VERSION "HNNBNNNYNNNNNNNNNNNNNNNNNNNNNNNNNNNNNNNNNN/4/%%%/4/'%**4NNN///"

NS_ :

BS_:

BU_: BAP_Tester CGS Gateway Gateway_PAG HUD Kombi Kombi_LB Kombi_PAG Waehlhebel_SB

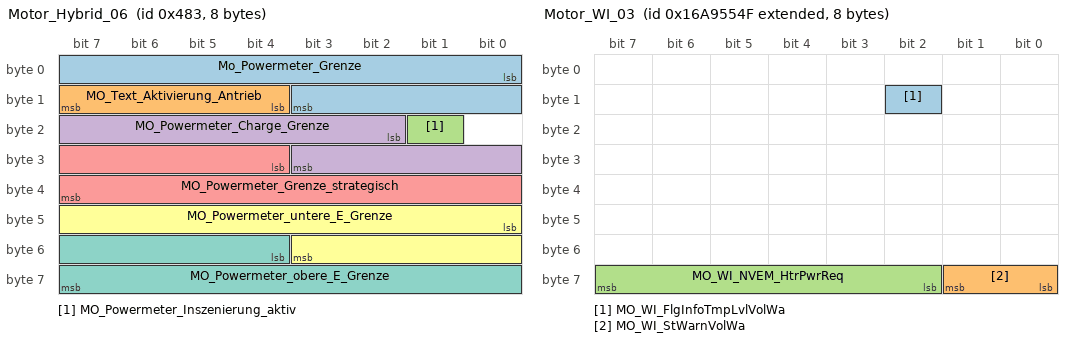
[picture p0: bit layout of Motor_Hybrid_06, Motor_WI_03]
BO_ 1155 Motor_Hybrid_06: 8 Gateway
 SG_ Mo_Powermeter_Grenze : 0|12@1+ (1,0) [0|4092] ""  HUD,Kombi,Kombi_LB,Kombi_PAG
 SG_ MO_Text_Aktivierung_Antrieb : 12|4@1+ (1.0,0.0) [0.0|15] ""  Kombi,Kombi_LB
 SG_ MO_Powermeter_Inszenierung_aktiv : 17|1@1+ (1.0,0.0) [0.0|1] ""  Kombi,Kombi_LB
 SG_ MO_Powermeter_Charge_Grenze : 18|10@1+ (1,0) [0|1021] "Unit_None"  HUD,Kombi,Kombi_LB,Kombi_PAG
 SG_ MO_Powermeter_Grenze_strategisch : 28|12@1+ (1,0) [0|4093] "Unit_None"  HUD,Kombi,Kombi_LB,Kombi_PAG
 SG_ MO_Powermeter_untere_E_Grenze : 40|12@1+ (1,0) [0|4093] "Unit_None"  Kombi,Kombi_LB,Kombi_PAG
 SG_ MO_Powermeter_obere_E_Grenze : 52|12@1+ (1,0) [0|4093] "Unit_None"  Kombi,Kombi_LB,Kombi_PAG

BO_ 878 Motor_Hybrid_12: 8 Gateway
 SG_ RML_Status_Anzeige_Range : 51|3@1+ (1.0,0.0) [0.0|7] ""  HUD,Kombi,Kombi_LB,Kombi_PAG
 SG_ RML_vMax_Range : 54|10@1+ (0.32,0) [0.00|326.72] "Unit_KiloMeterPerHour"  HUD,Kombi,Kombi_LB,Kombi_PAG

BO_ 2527679823 Motor_WI_03: 8 Gateway_PAG
 SG_ MO_WI_FlgInfoTmpLvlVolWa : 10|1@1+ (1.0,0.0) [0.0|1] ""  Kombi_PAG
 SG_ MO_WI_StWarnVolWa : 56|2@1+ (1.0,0.0) [0.0|3] ""  Kombi,Kombi_PAG
 SG_ MO_WI_NVEM_HtrPwrReq : 58|6@1+ (50,0) [0|3150] "Unit_Watt"  Vector__XXX

BO_ 2589284146 MRR_HL_P_Text_01: 8 Gateway
 SG_ MRR_HL_P_Text_Mux M  : 0|2@1+ (1,0) [0|3] ""  Kombi,Kombi_LB
 SG_ MRR_HL_P_Text_ASCII_01 m0  : 8|8@1+ (1.0,0.0) [0.0|255] ""  Kombi,Kombi_LB
 SG_ MRR_HL_P_Text_ASCII_08 m1  : 8|8@1+ (1.0,0.0) [0.0|255] ""  Kombi,Kombi_LB
 SG_ MRR_HL_P_Text_ASCII_15 m2  : 8|8@1+ (1.0,0.0) [0.0|255] ""  Kombi,Kombi_LB
 SG_ MRR_HL_P_Text_ASCII_02 m0  : 16|8@1+ (1.0,0.0) [0.0|255] ""  Kombi,Kombi_LB
 SG_ MRR_HL_P_Text_ASCII_09 m1  : 16|8@1+ (1.0,0.0) [0.0|255] ""  Kombi,Kombi_LB
 SG_ MRR_HL_P_Text_ASCII_16 m2  : 16|8@1+ (1.0,0.0) [0.0|255] ""  Kombi,Kombi_LB
 SG_ MRR_HL_P_Text_ASCII_03 m0  : 24|8@1+ (1.0,0.0) [0.0|255] ""  Kombi,Kombi_LB
 SG_ MRR_HL_P_Text_ASCII_10 m1  : 24|8@1+ (1.0,0.0) [0.0|255] ""  Kombi,Kombi_LB
 SG_ MRR_HL_P_Text_ASCII_17 m2  : 24|8@1+ (1.0,0.0) [0.0|255] ""  Kombi,Kombi_LB
 SG_ MRR_HL_P_Text_ASCII_04 m0  : 32|8@1+ (1.0,0.0) [0.0|255] ""  Kombi,Kombi_LB
 SG_ MRR_HL_P_Text_ASCII_11 m1  : 32|8@1+ (1.0,0.0) [0.0|255] ""  Kombi,Kombi_LB
 SG_ MRR_HL_P_Text_ASCII_18 m2  : 32|8@1+ (1.0,0.0) [0.0|255] ""  Kombi,Kombi_LB
 SG_ MRR_HL_P_Text_ASCII_05 m0  : 40|8@1+ (1.0,0.0) [0.0|255] ""  Kombi,Kombi_LB
 SG_ MRR_HL_P_Text_ASCII_12 m1  : 40|8@1+ (1.0,0.0) [0.0|255] ""  Kombi,Kombi_LB
 SG_ MRR_HL_P_Text_ASCII_19 m2  : 40|8@1+ (1.0,0.0) [0.0|255] ""  Kombi,Kombi_LB
 SG_ MRR_HL_P_Text_ASCII_06 m0  : 48|8@1+ (1.0,0.0) [0.0|255] ""  Kombi,Kombi_LB
 SG_ MRR_HL_P_Text_ASCII_13 m1  : 48|8@1+ (1.0,0.0) [0.0|255] ""  Kombi,Kombi_LB
 SG_ MRR_HL_P_Text_ASCII_20 m2  : 48|8@1+ (1.0,0.0) [0.0|255] ""  Kombi,Kombi_LB
 SG_ MRR_HL_P_Text_ASCII_07 m0  : 56|8@1+ (1.0,0.0) [0.0|255] ""  Kombi,Kombi_LB
 SG_ MRR_HL_P_Text_ASCII_14 m1  : 56|8@1+ (1.0,0.0) [0.0|255] ""  Kombi,Kombi_LB
 SG_ MRR_HL_P_Text_ASCII_21 m2  : 56|8@1+ (1.0,0.0) [0.0|255] ""  Kombi,Kombi_LB

BO_ 2589284147 MRR_HR_P_Text_01: 8 Gateway
 SG_ MRR_HR_P_Text_Mux M  : 0|2@1+ (1,0) [0|3] ""  Kombi,Kombi_LB
 SG_ MRR_HR_P_Text_ASCII_01 m0  : 8|8@1+ (1.0,0.0) [0.0|255] ""  Kombi,Kombi_LB
 SG_ MRR_HR_P_Text_ASCII_08 m1  : 8|8@1+ (1.0,0.0) [0.0|255] ""  Kombi,Kombi_LB
 SG_ MRR_HR_P_Text_ASCII_15 m2  : 8|8@1+ (1.0,0.0) [0.0|255] ""  Kombi,Kombi_LB
 SG_ MRR_HR_P_Text_ASCII_02 m0  : 16|8@1+ (1.0,0.0) [0.0|255] ""  Kombi,Kombi_LB
 SG_ MRR_HR_P_Text_ASCII_09 m1  : 16|8@1+ (1.0,0.0) [0.0|255] ""  Kombi,Kombi_LB
 SG_ MRR_HR_P_Text_ASCII_16 m2  : 16|8@1+ (1.0,0.0) [0.0|255] ""  Kombi,Kombi_LB
 SG_ MRR_HR_P_Text_ASCII_03 m0  : 24|8@1+ (1.0,0.0) [0.0|255] ""  Kombi,Kombi_LB
 SG_ MRR_HR_P_Text_ASCII_10 m1  : 24|8@1+ (1.0,0.0) [0.0|255] ""  Kombi,Kombi_LB
 SG_ MRR_HR_P_Text_ASCII_17 m2  : 24|8@1+ (1.0,0.0) [0.0|255] ""  Kombi,Kombi_LB
 SG_ MRR_HR_P_Text_ASCII_04 m0  : 32|8@1+ (1.0,0.0) [0.0|255] ""  Kombi,Kombi_LB
 SG_ MRR_HR_P_Text_ASCII_11 m1  : 32|8@1+ (1.0,0.0) [0.0|255] ""  Kombi,Kombi_LB
 SG_ MRR_HR_P_Text_ASCII_18 m2  : 32|8@1+ (1.0,0.0) [0.0|255] ""  Kombi,Kombi_LB
 SG_ MRR_HR_P_Text_ASCII_05 m0  : 40|8@1+ (1.0,0.0) [0.0|255] ""  Kombi,Kombi_LB
 SG_ MRR_HR_P_Text_ASCII_12 m1  : 40|8@1+ (1.0,0.0) [0.0|255] ""  Kombi,Kombi_LB
 SG_ MRR_HR_P_Text_ASCII_19 m2  : 40|8@1+ (1.0,0.0) [0.0|255] ""  Kombi,Kombi_LB
 SG_ MRR_HR_P_Text_ASCII_06 m0  : 48|8@1+ (1.0,0.0) [0.0|255] ""  Kombi,Kombi_LB
 SG_ MRR_HR_P_Text_ASCII_13 m1  : 48|8@1+ (1.0,0.0) [0.0|255] ""  Kombi,Kombi_LB
 SG_ MRR_HR_P_Text_ASCII_20 m2  : 48|8@1+ (1.0,0.0) [0.0|255] ""  Kombi,Kombi_LB
 SG_ MRR_HR_P_Text_ASCII_07 m0  : 56|8@1+ (1.0,0.0) [0.0|255] ""  Kombi,Kombi_LB
 SG_ MRR_HR_P_Text_ASCII_14 m1  : 56|8@1+ (1.0,0.0) [0.0|255] ""  Kombi,Kombi_LB
 SG_ MRR_HR_P_Text_ASCII_21 m2  : 56|8@1+ (1.0,0.0) [0.0|255] ""  Kombi,Kombi_LB

BO_ 2589284144 MRR_VL_P_Text_01: 8 Gateway
 SG_ MRR_VL_P_Text_Mux M  : 0|2@1+ (1,0) [0|3] ""  Kombi,Kombi_LB
 SG_ MRR_VL_P_Text_ASCII_01 m0  : 8|8@1+ (1.0,0.0) [0.0|255] ""  Kombi,Kombi_LB
 SG_ MRR_VL_P_Text_ASCII_08 m1  : 8|8@1+ (1.0,0.0) [0.0|255] ""  Kombi,Kombi_LB
 SG_ MRR_VL_P_Text_ASCII_15 m2  : 8|8@1+ (1.0,0.0) [0.0|255] ""  Kombi,Kombi_LB
 SG_ MRR_VL_P_Text_ASCII_02 m0  : 16|8@1+ (1.0,0.0) [0.0|255] ""  Kombi,Kombi_LB
 SG_ MRR_VL_P_Text_ASCII_09 m1  : 16|8@1+ (1.0,0.0) [0.0|255] ""  Kombi,Kombi_LB
 SG_ MRR_VL_P_Text_ASCII_16 m2  : 16|8@1+ (1.0,0.0) [0.0|255] ""  Kombi,Kombi_LB
 SG_ MRR_VL_P_Text_ASCII_03 m0  : 24|8@1+ (1.0,0.0) [0.0|255] ""  Kombi,Kombi_LB
 SG_ MRR_VL_P_Text_ASCII_10 m1  : 24|8@1+ (1.0,0.0) [0.0|255] ""  Kombi,Kombi_LB
 SG_ MRR_VL_P_Text_ASCII_17 m2  : 24|8@1+ (1.0,0.0) [0.0|255] ""  Kombi,Kombi_LB
 SG_ MRR_VL_P_Text_ASCII_04 m0  : 32|8@1+ (1.0,0.0) [0.0|255] ""  Kombi,Kombi_LB
 SG_ MRR_VL_P_Text_ASCII_11 m1  : 32|8@1+ (1.0,0.0) [0.0|255] ""  Kombi,Kombi_LB
 SG_ MRR_VL_P_Text_ASCII_18 m2  : 32|8@1+ (1.0,0.0) [0.0|255] ""  Kombi,Kombi_LB
 SG_ MRR_VL_P_Text_ASCII_05 m0  : 40|8@1+ (1.0,0.0) [0.0|255] ""  Kombi,Kombi_LB
 SG_ MRR_VL_P_Text_ASCII_12 m1  : 40|8@1+ (1.0,0.0) [0.0|255] ""  Kombi,Kombi_LB
 SG_ MRR_VL_P_Text_ASCII_19 m2  : 40|8@1+ (1.0,0.0) [0.0|255] ""  Kombi,Kombi_LB
 SG_ MRR_VL_P_Text_ASCII_06 m0  : 48|8@1+ (1.0,0.0) [0.0|255] ""  Kombi,Kombi_LB
 SG_ MRR_VL_P_Text_ASCII_13 m1  : 48|8@1+ (1.0,0.0) [0.0|255] ""  Kombi,Kombi_LB
 SG_ MRR_VL_P_Text_ASCII_20 m2  : 48|8@1+ (1.0,0.0) [0.0|255] ""  Kombi,Kombi_LB
 SG_ MRR_VL_P_Text_ASCII_07 m0  : 56|8@1+ (1.0,0.0) [0.0|255] ""  Kombi,Kombi_LB
 SG_ MRR_VL_P_Text_ASCII_14 m1  : 56|8@1+ (1.0,0.0) [0.0|255] ""  Kombi,Kombi_LB
 SG_ MRR_VL_P_Text_ASCII_21 m2  : 56|8@1+ (1.0,0.0) [0.0|255] ""  Kombi,Kombi_LB

BO_ 2589284145 MRR_VR_P_Text_01: 8 Gateway
 SG_ MRR_VR_P_Text_Mux M  : 0|2@1+ (1,0) [0|3] ""  Kombi,Kombi_LB
 SG_ MRR_VR_P_Text_ASCII_01 m0  : 8|8@1+ (1.0,0.0) [0.0|255] ""  Kombi,Kombi_LB
 SG_ MRR_VR_P_Text_ASCII_08 m1  : 8|8@1+ (1.0,0.0) [0.0|255] ""  Kombi,Kombi_LB
 SG_ MRR_VR_P_Text_ASCII_15 m2  : 8|8@1+ (1.0,0.0) [0.0|255] ""  Kombi,Kombi_LB
 SG_ MRR_VR_P_Text_ASCII_02 m0  : 16|8@1+ (1.0,0.0) [0.0|255] ""  Kombi,Kombi_LB
 SG_ MRR_VR_P_Text_ASCII_09 m1  : 16|8@1+ (1.0,0.0) [0.0|255] ""  Kombi,Kombi_LB
 SG_ MRR_VR_P_Text_ASCII_16 m2  : 16|8@1+ (1.0,0.0) [0.0|255] ""  Kombi,Kombi_LB
 SG_ MRR_VR_P_Text_ASCII_03 m0  : 24|8@1+ (1.0,0.0) [0.0|255] ""  Kombi,Kombi_LB
 SG_ MRR_VR_P_Text_ASCII_10 m1  : 24|8@1+ (1.0,0.0) [0.0|255] ""  Kombi,Kombi_LB
 SG_ MRR_VR_P_Text_ASCII_17 m2  : 24|8@1+ (1.0,0.0) [0.0|255] ""  Kombi,Kombi_LB
 SG_ MRR_VR_P_Text_ASCII_04 m0  : 32|8@1+ (1.0,0.0) [0.0|255] ""  Kombi,Kombi_LB
 SG_ MRR_VR_P_Text_ASCII_11 m1  : 32|8@1+ (1.0,0.0) [0.0|255] ""  Kombi,Kombi_LB
 SG_ MRR_VR_P_Text_ASCII_18 m2  : 32|8@1+ (1.0,0.0) [0.0|255] ""  Kombi,Kombi_LB
 SG_ MRR_VR_P_Text_ASCII_05 m0  : 40|8@1+ (1.0,0.0) [0.0|255] ""  Kombi,Kombi_LB
 SG_ MRR_VR_P_Text_ASCII_12 m1  : 40|8@1+ (1.0,0.0) [0.0|255] ""  Kombi,Kombi_LB
 SG_ MRR_VR_P_Text_ASCII_19 m2  : 40|8@1+ (1.0,0.0) [0.0|255] ""  Kombi
 SG_ MRR_VR_P_Text_ASCII_06 m0  : 48|8@1+ (1.0,0.0) [0.0|255] ""  Kombi,Kombi_LB
 SG_ MRR_VR_P_Text_ASCII_13 m1  : 48|8@1+ (1.0,0.0) [0.0|255] ""  Kombi,Kombi_LB
 SG_ MRR_VR_P_Text_ASCII_20 m2  : 48|8@1+ (1.0,0.0) [0.0|255] ""  Kombi
 SG_ MRR_VR_P_Text_ASCII_07 m0  : 56|8@1+ (1.0,0.0) [0.0|255] ""  Kombi,Kombi_LB
 SG_ MRR_VR_P_Text_ASCII_14 m1  : 56|8@1+ (1.0,0.0) [0.0|255] ""  Kombi,Kombi_LB
 SG_ MRR_VR_P_Text_ASCII_21 m2  : 56|8@1+ (1.0,0.0) [0.0|255] ""  Kombi

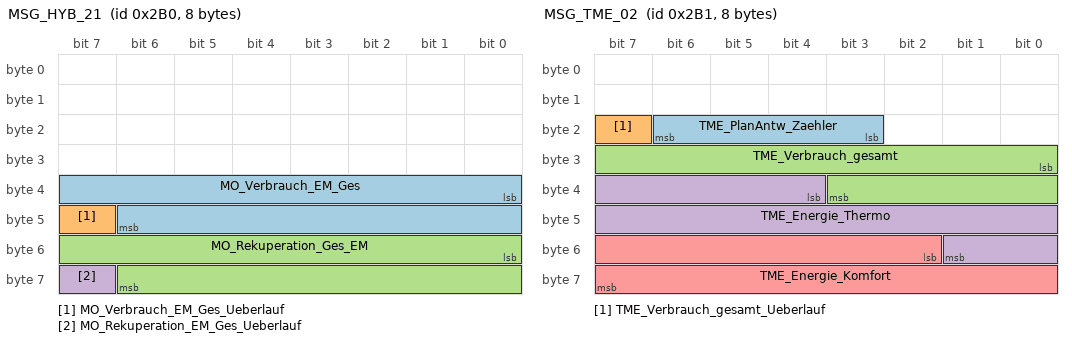
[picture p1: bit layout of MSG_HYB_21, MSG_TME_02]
BO_ 688 MSG_HYB_21: 8 Gateway
 SG_ MO_Verbrauch_EM_Ges : 32|15@1+ (10,0) [0|327670] "Unit_WattSecond"  Kombi,Kombi_LB,Kombi_PAG
 SG_ MO_Verbrauch_EM_Ges_Ueberlauf : 47|1@1+ (1.0,0.0) [0.0|1] ""  Kombi,Kombi_LB,Kombi_PAG
 SG_ MO_Rekuperation_Ges_EM : 48|15@1+ (10,0) [0|327670] "Unit_WattSecond"  Kombi,Kombi_LB,Kombi_PAG
 SG_ MO_Rekuperation_EM_Ges_Ueberlauf : 63|1@1+ (1.0,0.0) [0.0|1] ""  Kombi,Kombi_LB,Kombi_PAG

BO_ 689 MSG_TME_02: 8 Gateway
 SG_ TME_PlanAntw_Zaehler : 19|4@1+ (1,0) [0|13] "Unit_None"  Vector__XXX
 SG_ TME_Verbrauch_gesamt_Ueberlauf : 23|1@1+ (1.0,0.0) [0.0|1] ""  Kombi,Kombi_LB
 SG_ TME_Verbrauch_gesamt : 24|12@1+ (1,0) [0|4095] "Unit_WattSecond"  Kombi,Kombi_LB
 SG_ TME_Energie_Thermo : 36|14@1+ (5,0) [0|63250] "Unit_WattHour"  Vector__XXX
 SG_ TME_Energie_Komfort : 50|14@1+ (5,0) [0|63250] "Unit_WattHour"  Vector__XXX

BO_ 1284 MVK_01: 8 Gateway
 SG_ MVK_01_CRC : 0|8@1+ (1,0) [0|255] ""  Vector__XXX
 SG_ MVK_01_BZ : 8|4@1+ (1,0) [0|15] ""  Vector__XXX
 SG_ MVK_DCDC_Sollmodus_02 : 12|4@1+ (1.0,0.0) [0.0|15] ""  Vector__XXX
 SG_ MVK_eKAT_Sollmodus : 24|3@1+ (1.0,0.0) [0.0|7] ""  Vector__XXX
 SG_ MVK_eKMV_Sollmodus : 27|3@1+ (1.0,0.0) [0.0|7] ""  Vector__XXX
 SG_ MVK_MVH_L_Sollmodus : 30|3@1+ (1.0,0.0) [0.0|7] ""  Vector__XXX
 SG_ MV_Bordnetz_aktiv : 33|1@1+ (1.0,0.0) [0.0|1] ""  Vector__XXX
 SG_ MVK_BOOST_Sollmodus : 34|3@1+ (1.0,0.0) [0.0|7] ""  Vector__XXX
 SG_ MVK_eABC_Sollmodus : 37|3@1+ (1.0,0.0) [0.0|7] ""  Vector__XXX
 SG_ MVK_eAWS_Sollmodus : 40|3@1+ (1.0,0.0) [0.0|7] ""  Vector__XXX
 SG_ MV_Bordnetz_Fehler : 43|1@1+ (1.0,0.0) [0.0|1] ""  Vector__XXX
 SG_ MVK_MVPTC_Sollmodus : 44|3@1+ (1.0,0.0) [0.0|7] ""  Vector__XXX
 SG_ MVK_Istmodus_Anf : 47|1@1+ (1.0,0.0) [0.0|1] ""  Vector__XXX
 SG_ MVK_MO_EmSollzustand : 48|8@1+ (1.0,0.0) [0.0|255] ""  Vector__XXX
 SG_ MVK_BMS_Sollmodus : 56|3@1+ (1.0,0.0) [0.0|7] ""  Vector__XXX
 SG_ MVK_DCDC_Sollmodus : 59|3@1+ (1.0,0.0) [0.0|7] ""  Vector__XXX
 SG_ MVK_MV_Netz_Warnungen : 62|2@1+ (1.0,0.0) [0.0|3] ""  Kombi,Kombi_PAG

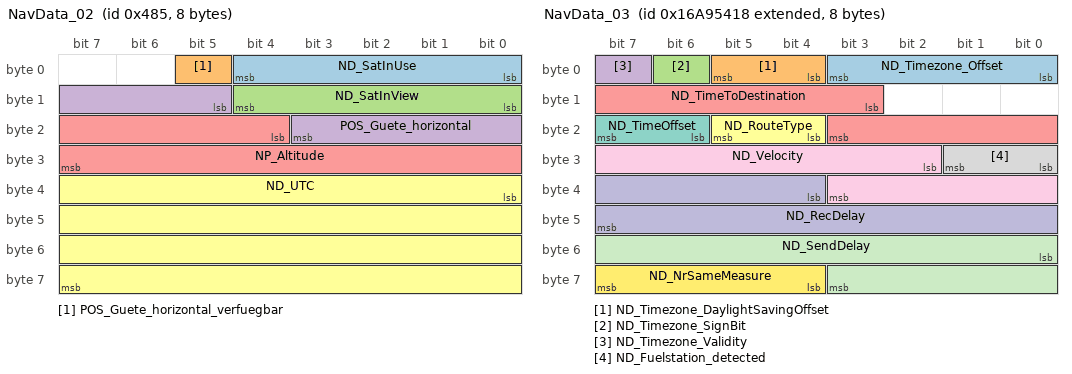
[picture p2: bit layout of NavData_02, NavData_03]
BO_ 1157 NavData_02: 8 Gateway
 SG_ ND_SatInUse : 0|5@1+ (1,0) [0|29] ""  Vector__XXX
 SG_ POS_Guete_horizontal_verfuegbar : 5|1@1+ (1.0,0.0) [0.0|1] ""  Vector__XXX
 SG_ ND_SatInView : 8|5@1+ (1,0) [0|29] ""  Vector__XXX
 SG_ POS_Guete_horizontal : 13|7@1+ (2,0) [0|246] "Unit_Meter"  Vector__XXX
 SG_ NP_Altitude : 20|12@1+ (2,-500) [-500|7686] "Unit_Meter"  Kombi_PAG
 SG_ ND_UTC : 32|32@1+ (1,0) [0|4294967293] "Unit_Secon"  Vector__XXX

BO_ 2527679512 NavData_03: 8 Gateway
 SG_ ND_Timezone_Offset : 0|4@1+ (1,0) [0|12] "Unit_Hours"  Vector__XXX
 SG_ ND_Timezone_DaylightSavingOffset : 4|2@1+ (30,0) [0|60] "Unit_Minut"  Vector__XXX
 SG_ ND_Timezone_SignBit : 6|1@1+ (1.0,0.0) [0.0|1] ""  Vector__XXX
 SG_ ND_Timezone_Validity : 7|1@1+ (1.0,0.0) [0.0|1] ""  Vector__XXX
 SG_ ND_TimeToDestination : 11|9@1+ (1,0) [0|509] "Unit_Minut"  Vector__XXX
 SG_ ND_RouteType : 20|2@1+ (1.0,0.0) [0.0|3] ""  Vector__XXX
 SG_ ND_TimeOffset : 22|2@1+ (1.0,0.0) [0.0|3] ""  Vector__XXX
 SG_ ND_Fuelstation_detected : 24|2@1+ (1.0,0.0) [0.0|3] ""  Kombi,Kombi_LB,Kombi_PAG
 SG_ ND_Velocity : 26|10@1+ (0.1,0) [0.0|102.1] "Unit_MeterPerSecon"  Vector__XXX
 SG_ ND_RecDelay : 36|12@1+ (1,0) [0|4093] "Unit_MilliSecon"  Vector__XXX
 SG_ ND_SendDelay : 48|12@1+ (1,0) [0|4093] "Unit_MilliSecon"  Vector__XXX
 SG_ ND_NrSameMeasure : 60|4@1+ (1,0) [0|8] ""  Vector__XXX

BO_ 1696 NightVision_01: 8 Gateway
 SG_ NV_aktiv : 12|1@1+ (1.0,0.0) [0.0|1] ""  Kombi,Kombi_PAG
 SG_ NV_Texte : 13|3@1+ (1.0,0.0) [0.0|7] ""  Kombi,Kombi_PAG
 SG_ NV_Gong : 16|2@1+ (1.0,0.0) [0.0|3] ""  Kombi,Kombi_PAG
 SG_ NV_Symbol : 18|1@1+ (1.0,0.0) [0.0|1] ""  HUD,Kombi,Kombi_PAG
 SG_ NV_Hinweise : 19|2@1+ (1.0,0.0) [0.0|3] ""  Kombi,Kombi_PAG
 SG_ NV_Piktogramm_aktiv : 21|1@1+ (1.0,0.0) [0.0|1] ""  Kombi,Kombi_PAG
 SG_ NV_Akustik_deaktiviert_Icon : 22|1@1+ (1.0,0.0) [0.0|1] ""  Kombi,Kombi_PAG
 SG_ NV_FGM_deaktiviert_Icon : 23|1@1+ (1.0,0.0) [0.0|1] ""  Kombi,Kombi_PAG
 SG_ NV_Markierungslicht_links : 24|1@1+ (1.0,0.0) [0.0|1] ""  Vector__XXX
 SG_ NV_Markierungslicht_rechts : 25|1@1+ (1.0,0.0) [0.0|1] ""  Vector__XXX
 SG_ NV_Symbol_Tierwarnung : 26|1@1+ (1.0,0.0) [0.0|1] ""  HUD,Kombi,Kombi_PAG
 SG_ NV_Anf_Prefill : 27|1@1+ (1.0,0.0) [0.0|1] ""  Vector__XXX
 SG_ NV_HBA_Parameter : 28|2@1+ (1.0,0.0) [0.0|3] ""  Vector__XXX
 SG_ NV_LED_Leiste : 30|2@1+ (1.0,0.0) [0.0|3] ""  HUD,Kombi,Kombi_PAG
 SG_ NV_PreSense_Status : 32|2@1+ (1.0,0.0) [0.0|3] ""  Vector__XXX
 SG_ NV_PreSense_Modus_System : 34|1@1+ (1.0,0.0) [0.0|1] ""  Vector__XXX
 SG_ NV_PreSense_Modus_Warnung : 35|3@1+ (1.0,0.0) [0.0|7] ""  Vector__XXX
 SG_ NV_FAS_Fkt_Status : 38|2@1+ (1.0,0.0) [0.0|3] ""  Vector__XXX
 SG_ NV_Akt_Status_MMI : 40|2@1+ (1.0,0.0) [0.0|3] ""  Kombi,Kombi_PAG
 SG_ NV_AnforderungBildaufschaltung : 42|1@1+ (1.0,0.0) [0.0|1] ""  Kombi

BO_ 2600468496 NMH_Gateway: 8 Gateway
 SG_ NM_Gateway_SNI : 0|8@1+ (1.0,0.0) [0.0|255] ""  CGS,HUD,Kombi,Kombi_LB,Kombi_PAG,Waehlhebel_SB
 SG_ NM_Gateway_CBV_AWB : 12|1@1+ (1.0,0.0) [0.0|1] ""  Vector__XXX
 SG_ NM_Gateway_CBV_CRI : 14|1@1+ (1.0,0.0) [0.0|1] ""  CGS,HUD,Kombi,Kombi_LB,Kombi_PAG,Waehlhebel_SB
 SG_ NM_Gateway_NM_State : 16|6@1+ (1.0,0.0) [0.0|63] ""  Vector__XXX
 SG_ NM_Gateway_Car_Wakeup : 22|1@1+ (1.0,0.0) [0.0|1] ""  Vector__XXX
 SG_ NM_Gateway_UDS_CC : 23|1@1+ (1.0,0.0) [0.0|1] ""  Vector__XXX
 SG_ NM_Gateway_NM_aktiv_KL15 : 24|1@1+ (1.0,0.0) [0.0|1] ""  Vector__XXX
 SG_ NM_Gateway_NM_aktiv_Diagnose : 25|1@1+ (1.0,0.0) [0.0|1] ""  Vector__XXX
 SG_ NM_Gateway_NM_aktiv_Tmin : 26|1@1+ (1.0,0.0) [0.0|1] ""  Vector__XXX
 SG_ NM_Gateway_NM_aktiv_CWU : 27|1@1+ (1.0,0.0) [0.0|1] ""  Vector__XXX
 SG_ NM_Gateway_NM_aktiv_FC : 28|1@1+ (1.0,0.0) [0.0|1] ""  Vector__XXX
 SG_ NM_Gateway_NM_aktiv_Connect : 29|1@1+ (1.0,0.0) [0.0|1] ""  Vector__XXX
 SG_ NM_Gateway_NM_aktiv_EM : 30|1@1+ (1.0,0.0) [0.0|1] ""  Vector__XXX
 SG_ NM_Gateway_NM_aktiv_OBDC : 31|1@1+ (1.0,0.0) [0.0|1] ""  Vector__XXX
 SG_ NM_Gateway_NM_aktiv_Buskopplung : 32|1@1+ (1.0,0.0) [0.0|1] ""  Vector__XXX
 SG_ NM_Gateway_NM_aktiv_LIN2 : 33|1@1+ (1.0,0.0) [0.0|1] ""  Vector__XXX
 SG_ NM_Gateway_NM_aktiv_Fremdladung : 34|1@1+ (1.0,0.0) [0.0|1] ""  Vector__XXX
 SG_ NM_Gateway_CAB : 40|24@1+ (1.0,0.0) [0.0|16777215] ""  CGS,HUD,Kombi,Kombi_LB,Kombi_PAG,Waehlhebel_SB

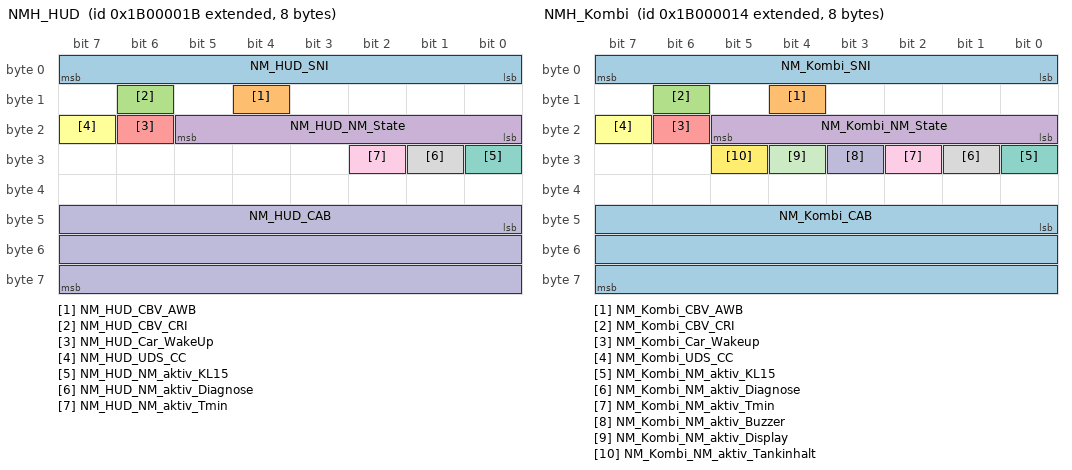
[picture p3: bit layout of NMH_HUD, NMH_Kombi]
BO_ 2600468507 NMH_HUD: 8 HUD
 SG_ NM_HUD_SNI : 0|8@1+ (1.0,0.0) [0.0|255] ""  CGS,Gateway,Gateway_PAG,HUD,Kombi,Kombi_LB,Kombi_PAG,Waehlhebel_SB
 SG_ NM_HUD_CBV_AWB : 12|1@1+ (1.0,0.0) [0.0|1] ""  Gateway,Gateway_PAG
 SG_ NM_HUD_CBV_CRI : 14|1@1+ (1.0,0.0) [0.0|1] ""  CGS,Gateway,Gateway_PAG,HUD,Kombi,Kombi_LB,Kombi_PAG,Waehlhebel_SB
 SG_ NM_HUD_NM_State : 16|6@1+ (1.0,0.0) [0.0|63] ""  Vector__XXX
 SG_ NM_HUD_Car_WakeUp : 22|1@1+ (1.0,0.0) [0.0|1] ""  Gateway
 SG_ NM_HUD_UDS_CC : 23|1@1+ (1.0,0.0) [0.0|1] ""  Vector__XXX
 SG_ NM_HUD_NM_aktiv_KL15 : 24|1@1+ (1.0,0.0) [0.0|1] ""  Vector__XXX
 SG_ NM_HUD_NM_aktiv_Diagnose : 25|1@1+ (1.0,0.0) [0.0|1] ""  Vector__XXX
 SG_ NM_HUD_NM_aktiv_Tmin : 26|1@1+ (1.0,0.0) [0.0|1] ""  Vector__XXX
 SG_ NM_HUD_CAB : 40|24@1+ (1.0,0.0) [0.0|16777215] ""  CGS,Gateway,Gateway_PAG,HUD,Kombi,Kombi_LB,Kombi_PAG,Waehlhebel_SB

BO_ 2600468500 NMH_Kombi: 8 Kombi
 SG_ NM_Kombi_SNI : 0|8@1+ (1.0,0.0) [0.0|255] ""  CGS,Gateway,Gateway_PAG,HUD,Kombi,Kombi_PAG,Waehlhebel_SB
 SG_ NM_Kombi_CBV_AWB : 12|1@1+ (1.0,0.0) [0.0|1] ""  Gateway,Gateway_PAG
 SG_ NM_Kombi_CBV_CRI : 14|1@1+ (1.0,0.0) [0.0|1] ""  CGS,Gateway,Gateway_PAG,HUD,Kombi,Kombi_PAG,Waehlhebel_SB
 SG_ NM_Kombi_NM_State : 16|6@1+ (1.0,0.0) [0.0|63] ""  Vector__XXX
 SG_ NM_Kombi_Car_Wakeup : 22|1@1+ (1.0,0.0) [0.0|1] ""  Gateway,Gateway_PAG
 SG_ NM_Kombi_UDS_CC : 23|1@1+ (1.0,0.0) [0.0|1] ""  Vector__XXX
 SG_ NM_Kombi_NM_aktiv_KL15 : 24|1@1+ (1.0,0.0) [0.0|1] ""  Vector__XXX
 SG_ NM_Kombi_NM_aktiv_Diagnose : 25|1@1+ (1.0,0.0) [0.0|1] ""  Vector__XXX
 SG_ NM_Kombi_NM_aktiv_Tmin : 26|1@1+ (1.0,0.0) [0.0|1] ""  Vector__XXX
 SG_ NM_Kombi_NM_aktiv_Buzzer : 27|1@1+ (1.0,0.0) [0.0|1] ""  Vector__XXX
 SG_ NM_Kombi_NM_aktiv_Display : 28|1@1+ (1.0,0.0) [0.0|1] ""  Vector__XXX
 SG_ NM_Kombi_NM_aktiv_Tankinhalt : 29|1@1+ (1.0,0.0) [0.0|1] ""  Vector__XXX
 SG_ NM_Kombi_CAB : 40|24@1+ (1.0,0.0) [0.0|16777215] ""  CGS,Gateway,Gateway_PAG,HUD,Kombi,Kombi_PAG,Waehlhebel_SB

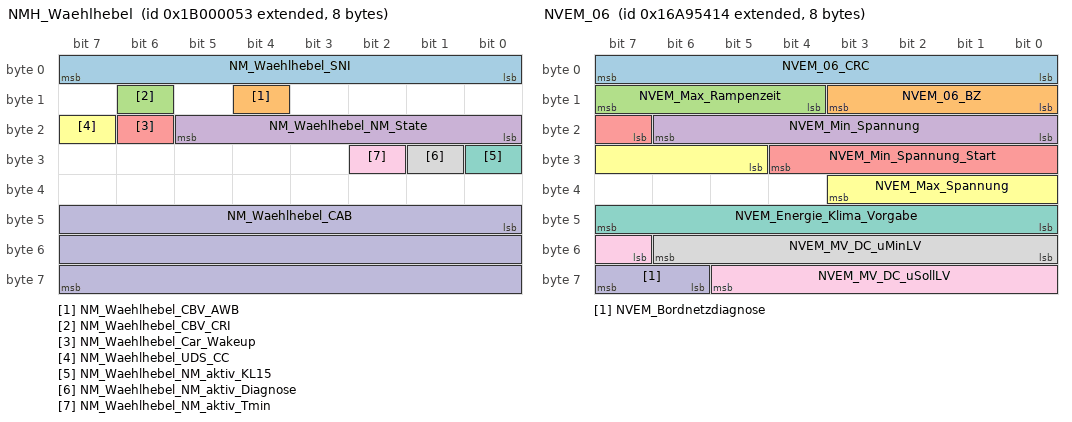
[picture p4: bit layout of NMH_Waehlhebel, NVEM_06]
BO_ 2600468563 NMH_Waehlhebel: 8 CGS
 SG_ NM_Waehlhebel_SNI : 0|8@1+ (1.0,0.0) [0.0|255] ""  Gateway,Gateway_PAG,HUD,Kombi,Kombi_LB,Kombi_PAG
 SG_ NM_Waehlhebel_CBV_AWB : 12|1@1+ (1.0,0.0) [0.0|1] ""  Gateway,Gateway_PAG
 SG_ NM_Waehlhebel_CBV_CRI : 14|1@1+ (1.0,0.0) [0.0|1] ""  Gateway,Gateway_PAG,HUD,Kombi,Kombi_LB,Kombi_PAG
 SG_ NM_Waehlhebel_NM_State : 16|6@1+ (1.0,0.0) [0.0|63] ""  Vector__XXX
 SG_ NM_Waehlhebel_Car_Wakeup : 22|1@1+ (1.0,0.0) [0.0|1] ""  Gateway,Gateway_PAG
 SG_ NM_Waehlhebel_UDS_CC : 23|1@1+ (1.0,0.0) [0.0|1] ""  Vector__XXX
 SG_ NM_Waehlhebel_NM_aktiv_KL15 : 24|1@1+ (1.0,0.0) [0.0|1] ""  Vector__XXX
 SG_ NM_Waehlhebel_NM_aktiv_Diagnose : 25|1@1+ (1.0,0.0) [0.0|1] ""  Vector__XXX
 SG_ NM_Waehlhebel_NM_aktiv_Tmin : 26|1@1+ (1.0,0.0) [0.0|1] ""  Vector__XXX
 SG_ NM_Waehlhebel_CAB : 40|24@1+ (1.0,0.0) [0.0|16777215] ""  Gateway,Gateway_PAG,HUD,Kombi,Kombi_LB,Kombi_PAG

BO_ 1635 NVEM_02: 8 Gateway
 SG_ BEM_02_Abschaltstufen : 0|3@1+ (1.0,0.0) [0.0|7] ""  HUD,Kombi,Kombi_LB,Kombi_PAG
 SG_ BEM_STH_Zielzeit : 3|4@1+ (5,0) [0|60] "Unit_Minut"  Vector__XXX
 SG_ BEM_MMI_Vorwarnung : 7|1@1+ (1.0,0.0) [0.0|1] ""  Vector__XXX
 SG_ NVEM_Anf_SD_schalten : 15|1@1+ (1.0,0.0) [0.0|1] ""  Vector__XXX
 SG_ BEM_Generatordiagnose : 16|2@1+ (1.0,0.0) [0.0|3] ""  Kombi,Kombi_LB,Kombi_PAG
 SG_ BEM_Red_Innengeblaese : 18|2@1+ (1.0,0.0) [0.0|3] ""  Vector__XXX
 SG_ BEM_STH_Einschaltverbot : 20|1@1+ (1.0,0.0) [0.0|1] ""  Vector__XXX
 SG_ BEM_HL_Regelung_Status : 21|3@1+ (1.0,0.0) [0.0|7] ""  Vector__XXX
 SG_ BEM_Ladezustand : 24|4@1+ (10,0) [0|100] "Unit_PerCent"  Kombi,Kombi_LB,Kombi_PAG
 SG_ BEM_Batteriediagnose : 28|3@1+ (1.0,0.0) [0.0|7] ""  Kombi,Kombi_LB,Kombi_PAG
 SG_ MIB_Stromsparmodus : 31|1@1+ (1.0,0.0) [0.0|1] ""  Vector__XXX
 SG_ BEM_REK_aktiv : 37|1@1+ (1.0,0.0) [0.0|1] ""  Vector__XXX
 SG_ NVEM_Last_Anf : 38|2@1+ (1.0,0.0) [0.0|3] ""  Vector__XXX
 SG_ BEM_UBDM : 40|8@1+ (0.05,5) [5.05|17.70] "Unit_Volt"  Kombi_PAG
 SG_ BEM_UGenSoll : 48|6@1+ (0.1,10.6) [10.6|16.0] "Unit_Volt"  Vector__XXX
 SG_ BEM_Anf_KL15_schalten : 54|2@1+ (1.0,0.0) [0.0|3] ""  Vector__XXX
 SG_ NVEM_Batterie_Service : 56|2@1+ (1.0,0.0) [0.0|3] ""  Kombi,Kombi_LB,Kombi_PAG
 SG_ NVEM_Freigabe_OnlineUpdate : 58|1@1+ (1.0,0.0) [0.0|1] ""  Vector__XXX
 SG_ NVEM_Freigabe_ORU4 : 59|2@1+ (1.0,0.0) [0.0|3] ""  Vector__XXX

BO_ 2527679508 NVEM_06: 8 Gateway
 SG_ NVEM_06_CRC : 0|8@1+ (1,0) [0|255] ""  Kombi,Kombi_LB,Kombi_PAG
 SG_ NVEM_06_BZ : 8|4@1+ (1,0) [0|15] ""  Kombi,Kombi_LB,Kombi_PAG
 SG_ NVEM_Max_Rampenzeit : 12|4@1+ (1.0,0.0) [0.0|15] ""  Vector__XXX
 SG_ NVEM_Min_Spannung : 16|7@1+ (0.05,10.6) [10.60|16.00] "Unit_Volt"  Vector__XXX
 SG_ NVEM_Min_Spannung_Start : 23|6@1+ (0.1,7) [7.0|13.1] "Unit_Volt"  Vector__XXX
 SG_ NVEM_Max_Spannung : 29|7@1+ (0.05,10.6) [10.60|16.00] "Unit_Volt"  Vector__XXX
 SG_ NVEM_Energie_Klima_Vorgabe : 40|8@1+ (10,0) [0|2530] "Unit_WattHour"  Vector__XXX
 SG_ NVEM_MV_DC_uMinLV : 48|7@1+ (0.1,3.5) [3.5|16.0] "Unit_Volt"  Vector__XXX
 SG_ NVEM_MV_DC_uSollLV : 55|7@1+ (0.05,10.6) [10.60|16.00] "Unit_Volt"  Vector__XXX
 SG_ NVEM_Bordnetzdiagnose : 62|2@1+ (1.0,0.0) [0.0|3] ""  Kombi,Kombi_LB,Kombi_PAG

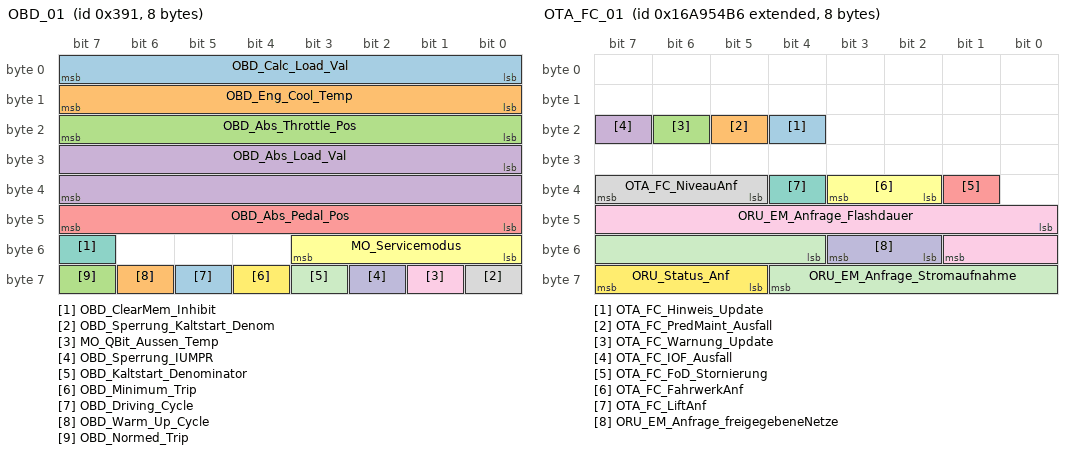
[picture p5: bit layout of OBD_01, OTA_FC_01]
BO_ 913 OBD_01: 8 Gateway
 SG_ OBD_Calc_Load_Val : 0|8@1+ (0.39215686274509803,0) [0E-17|99.99999999999999765] "Unit_PerCent"  Vector__XXX
 SG_ OBD_Eng_Cool_Temp : 8|8@1+ (1,-40) [-40|215] "Unit_DegreCelsi"  Vector__XXX
 SG_ OBD_Abs_Throttle_Pos : 16|8@1+ (0.39215686274509803,0) [0E-17|99.99999999999999765] "Unit_PerCent"  Vector__XXX
 SG_ OBD_Abs_Load_Val : 24|16@1+ (0.39215686274509803,0) [0E-17|25699.99999999999939605] "Unit_PerCent"  Vector__XXX
 SG_ OBD_Abs_Pedal_Pos : 40|8@1+ (0.39215686274509803,0) [0E-17|99.99999999999999765] "Unit_PerCent"  Vector__XXX
 SG_ MO_Servicemodus : 48|4@1+ (1.0,0.0) [0.0|15] ""  Vector__XXX
 SG_ OBD_ClearMem_Inhibit : 55|1@1+ (1.0,0.0) [0.0|1] ""  Vector__XXX
 SG_ OBD_Sperrung_Kaltstart_Denom : 56|1@1+ (1.0,0.0) [0.0|1] ""  Vector__XXX
 SG_ MO_QBit_Aussen_Temp : 57|1@1+ (1.0,0.0) [0.0|1] ""  Vector__XXX
 SG_ OBD_Sperrung_IUMPR : 58|1@1+ (1.0,0.0) [0.0|1] ""  Vector__XXX
 SG_ OBD_Kaltstart_Denominator : 59|1@1+ (1.0,0.0) [0.0|1] ""  Vector__XXX
 SG_ OBD_Minimum_Trip : 60|1@1+ (1.0,0.0) [0.0|1] ""  Vector__XXX
 SG_ OBD_Driving_Cycle : 61|1@1+ (1.0,0.0) [0.0|1] ""  Waehlhebel_SB
 SG_ OBD_Warm_Up_Cycle : 62|1@1+ (1.0,0.0) [0.0|1] ""  HUD,Kombi,Kombi_PAG,Waehlhebel_SB
 SG_ OBD_Normed_Trip : 63|1@1+ (1.0,0.0) [0.0|1] ""  Vector__XXX

BO_ 2549940736 OBDC_Funktionaler_Req_All: 8 Gateway
 SG_ OBDC_Funktionaler_Req_All_Data : 0|64@1+ (1.0,0.0) [0.0|18446744073709551615] ""  CGS,HUD,Kombi,Kombi_LB,Kombi_PAG,Waehlhebel_SB

BO_ 2549875227 OBDC_HUD_Req: 8 Gateway
 SG_ OBDC_HUD_Req_Data : 0|64@1+ (1.0,0.0) [0.0|18446744073709551615] ""  HUD

BO_ 2550006299 OBDC_HUD_Resp: 8 HUD
 SG_ OBDC_HUD_Resp_Data : 0|64@1+ (1.0,0.0) [0.0|18446744073709551615] ""  Gateway,Gateway_PAG

BO_ 2549875220 OBDC_Kombi_Req: 8 Gateway
 SG_ OBDC_Kombi_Req_Data : 0|64@1+ (1.0,0.0) [0.0|18446744073709551615] ""  Kombi,Kombi_LB,Kombi_PAG

BO_ 2550006292 OBDC_Kombi_Resp: 8 Kombi
 SG_ OBDC_Kombi_Resp_Data : 0|64@1+ (1.0,0.0) [0.0|18446744073709551615] ""  Gateway,Gateway_PAG

BO_ 2549875283 OBDC_Waehlhebel_Req: 8 Gateway
 SG_ OBDC_Waehlhebel_Req_Data : 0|64@1+ (1.0,0.0) [0.0|18446744073709551615] ""  CGS,Waehlhebel_SB

BO_ 2550006355 OBDC_Waehlhebel_Resp: 8 CGS
 SG_ OBDC_Waehlhebel_Resp_Data : 0|64@1+ (1.0,0.0) [0.0|18446744073709551615] ""  Gateway,Gateway_PAG

BO_ 2589283656 ORU_01: 8 Gateway
 SG_ ORU_Warnung : 58|2@1+ (1.0,0.0) [0.0|3] ""  Kombi,Kombi_LB,Kombi_PAG
 SG_ ORU_Status : 61|3@1+ (1.0,0.0) [0.0|7] ""  HUD,Kombi_PAG

BO_ 2527679670 OTA_FC_01: 8 Gateway_PAG
 SG_ OTA_FC_Hinweis_Update : 20|1@1+ (1.0,0.0) [0.0|1] ""  Kombi_PAG
 SG_ OTA_FC_PredMaint_Ausfall : 21|1@1+ (1.0,0.0) [0.0|1] ""  Kombi_PAG
 SG_ OTA_FC_Warnung_Update : 22|1@1+ (1.0,0.0) [0.0|1] ""  Kombi_PAG
 SG_ OTA_FC_IOF_Ausfall : 23|1@1+ (1.0,0.0) [0.0|1] ""  Kombi_PAG
 SG_ OTA_FC_FoD_Stornierung : 33|1@1+ (1.0,0.0) [0.0|1] ""  Kombi_PAG
 SG_ OTA_FC_FahrwerkAnf : 34|2@1+ (1.0,0.0) [0.0|3] ""  Vector__XXX
 SG_ OTA_FC_LiftAnf : 36|1@1+ (1.0,0.0) [0.0|1] ""  Vector__XXX
 SG_ OTA_FC_NiveauAnf : 37|3@1+ (1.0,0.0) [0.0|7] ""  Vector__XXX
 SG_ ORU_EM_Anfrage_Flashdauer : 40|10@1+ (10,0) [0|10230] "Unit_Secon"  Vector__XXX
 SG_ ORU_EM_Anfrage_freigegebeneNetze : 50|2@1+ (1.0,0.0) [0.0|3] ""  Vector__XXX
 SG_ ORU_EM_Anfrage_Stromaufnahme : 52|9@1+ (0.1,0) [0.0|51.1] "Unit_Amper"  Vector__XXX
 SG_ ORU_Status_Anf : 61|3@1+ (1.0,0.0) [0.0|7] ""  Vector__XXX

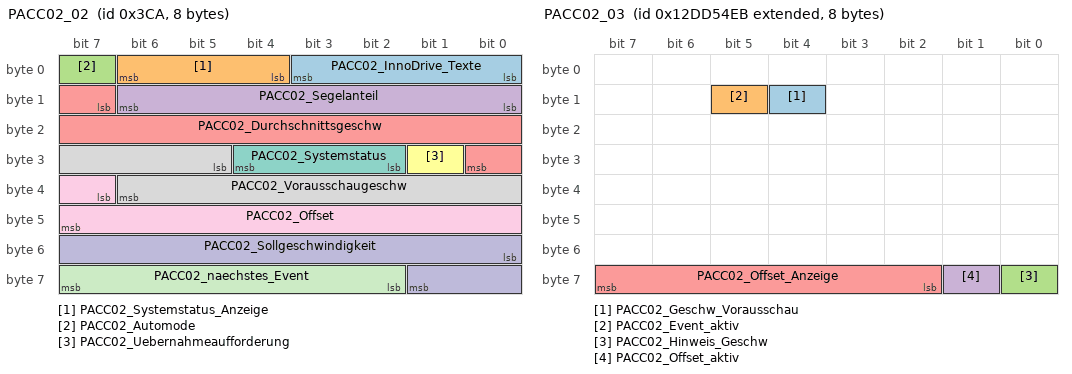
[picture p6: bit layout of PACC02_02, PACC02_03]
BO_ 970 PACC02_02: 8 Gateway
 SG_ PACC02_InnoDrive_Texte : 0|4@1+ (1.0,0.0) [0.0|15] ""  Kombi_PAG
 SG_ PACC02_Systemstatus_Anzeige : 4|3@1+ (1.0,0.0) [0.0|7] ""  HUD,Kombi_PAG
 SG_ PACC02_Automode : 7|1@1+ (1.0,0.0) [0.0|1] ""  HUD,Kombi_PAG
 SG_ PACC02_Segelanteil : 8|7@1+ (1,0) [1|100] "Unit_PerCent"  Vector__XXX
 SG_ PACC02_Durchschnittsgeschw : 15|10@1+ (0.3,0) [0.3|306.9] "Unit_KiloMeterPerHour"  Vector__XXX
 SG_ PACC02_Uebernahmeaufforderung : 25|1@1+ (1.0,0.0) [0.0|1] ""  Kombi_PAG
 SG_ PACC02_Systemstatus : 26|3@1+ (1.0,0.0) [0.0|7] ""  Kombi_PAG
 SG_ PACC02_Vorausschaugeschw : 29|10@1+ (0.32,0) [0.00|327.04] "Unit_KiloMeterPerHour"  HUD,Kombi_PAG
 SG_ PACC02_Offset : 39|9@1+ (1,-255) [-255|256] "Unit_KiloMeterPerHour"  Kombi_PAG
 SG_ PACC02_Sollgeschwindigkeit : 48|10@1+ (0.32,0) [0.00|327.04] "Unit_KiloMeterPerHour"  HUD,Kombi_PAG
 SG_ PACC02_naechstes_Event : 58|6@1+ (1.0,0.0) [0.0|63] ""  HUD,Kombi_PAG

BO_ 2463978731 PACC02_03: 8 Gateway
 SG_ PACC02_Geschw_Vorausschau : 12|1@1+ (1.0,0.0) [0.0|1] ""  HUD,Kombi_PAG
 SG_ PACC02_Event_aktiv : 13|1@1+ (1.0,0.0) [0.0|1] ""  HUD,Kombi_PAG
 SG_ PACC02_Hinweis_Geschw : 56|1@1+ (1.0,0.0) [0.0|1] ""  Kombi_PAG
 SG_ PACC02_Offset_aktiv : 57|1@1+ (1.0,0.0) [0.0|1] ""  HUD,Kombi_PAG
 SG_ PACC02_Offset_Anzeige : 58|6@1+ (1.0,0.0) [0.0|63] ""  HUD,Kombi_PAG

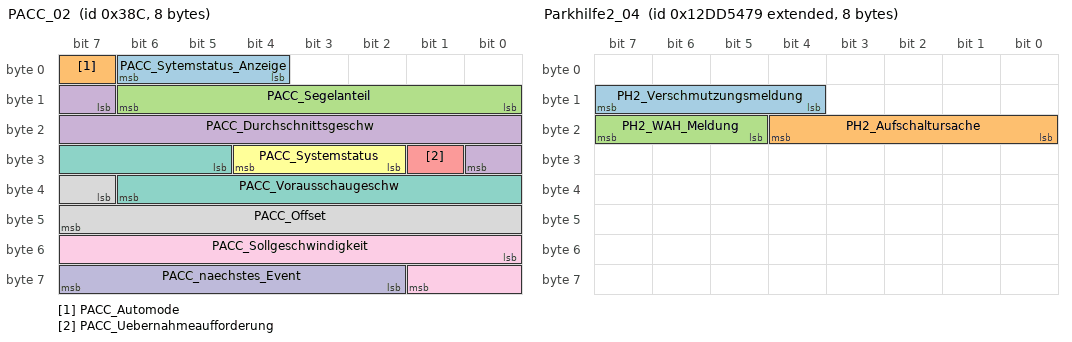
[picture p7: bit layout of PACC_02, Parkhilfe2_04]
BO_ 908 PACC_02: 8 Gateway
 SG_ PACC_Sytemstatus_Anzeige : 4|3@1+ (1.0,0.0) [0.0|7] ""  HUD,Kombi_PAG
 SG_ PACC_Automode : 7|1@1+ (1.0,0.0) [0.0|1] ""  HUD,Kombi_PAG
 SG_ PACC_Segelanteil : 8|7@1+ (1,0) [1|100] "Unit_PerCent"  Vector__XXX
 SG_ PACC_Durchschnittsgeschw : 15|10@1+ (0.3,0) [0.3|306.9] "Unit_KiloMeterPerHour"  Vector__XXX
 SG_ PACC_Uebernahmeaufforderung : 25|1@1+ (1.0,0.0) [0.0|1] ""  Vector__XXX
 SG_ PACC_Systemstatus : 26|3@1+ (1.0,0.0) [0.0|7] ""  HUD,Kombi_PAG
 SG_ PACC_Vorausschaugeschw : 29|10@1+ (0.32,0) [0.00|327.04] "Unit_KiloMeterPerHour"  Vector__XXX
 SG_ PACC_Offset : 39|9@1+ (1,-255) [-255|256] "Unit_KiloMeterPerHour"  Vector__XXX
 SG_ PACC_Sollgeschwindigkeit : 48|10@1+ (0.32,0) [0.00|327.04] "Unit_KiloMeterPerHour"  HUD,Kombi_PAG
 SG_ PACC_naechstes_Event : 58|6@1+ (1.0,0.0) [0.0|63] ""  Vector__XXX

BO_ 696 PADM_01: 8 Gateway
 SG_ PADM_Warnmeldung_Prio2 : 63|1@1+ (1.0,0.0) [0.0|1] ""  Kombi_PAG

BO_ 872 Parkhilfe2_01: 8 Gateway
 SG_ PH2_Visualisierung : 0|3@1+ (1.0,0.0) [0.0|7] ""  Vector__XXX
 SG_ PDC2_Tonausgabe_Front : 4|4@1+ (1.0,0.0) [0.0|15] ""  Kombi_PAG
 SG_ PDC2_Tonausgabe_Heck : 8|4@1+ (1.0,0.0) [0.0|15] ""  Kombi_PAG
 SG_ PH2_nachtr_Stopp_An : 12|1@1+ (1.0,0.0) [0.0|1] ""  Vector__XXX
 SG_ PH2_Abschaltursache : 13|3@1+ (1.0,0.0) [0.0|7] ""  Vector__XXX
 SG_ PH2_Opt_Anzeige_V_ein : 16|1@1+ (1.0,0.0) [0.0|1] ""  Vector__XXX
 SG_ PH2_Opt_Anzeige_H_ein : 17|1@1+ (1.0,0.0) [0.0|1] ""  Vector__XXX
 SG_ PH2_Opt_Anz_V_Hindernis : 18|1@1+ (1.0,0.0) [0.0|1] ""  Vector__XXX
 SG_ PH2_Opt_Anz_H_Hindernis : 19|1@1+ (1.0,0.0) [0.0|1] ""  Vector__XXX
 SG_ PH2_Tongeber_V_aktiv : 20|1@1+ (1.0,0.0) [0.0|1] ""  Vector__XXX
 SG_ PH2_Tongeber_H_aktiv : 21|1@1+ (1.0,0.0) [0.0|1] ""  Vector__XXX
 SG_ PH2_Tongeber_mute : 22|1@1+ (1.0,0.0) [0.0|1] ""  Vector__XXX
 SG_ PH2_Anf_Audioabsenkung : 23|1@1+ (1.0,0.0) [0.0|1] ""  Vector__XXX
 SG_ PH2_Tongeber_H_verfuegbar : 24|1@1+ (1.0,0.0) [0.0|1] ""  Vector__XXX
 SG_ PH2_Taster : 28|2@1+ (1.0,0.0) [0.0|3] ""  Vector__XXX
 SG_ PH2_Anf_Verdeck : 30|2@1+ (1.0,0.0) [0.0|3] ""  Vector__XXX
 SG_ PH2_Frequenz_hinten : 32|4@1+ (1,0) [0|15] ""  Vector__XXX
 SG_ PH2_Lautstaerke_hinten : 36|4@1+ (1,0) [0|15] ""  Kombi_PAG
 SG_ PH2_Frequenz_vorn : 40|4@1+ (1,0) [0|15] ""  Vector__XXX
 SG_ PH2_Lautstaerke_vorn : 44|4@1+ (1,0) [0|15] ""  Kombi_PAG
 SG_ PH2_StartStopp_Info : 49|2@1+ (1.0,0.0) [0.0|3] ""  Vector__XXX
 SG_ PH2_Stoermeldung : 52|4@1+ (1.0,0.0) [0.0|15] ""  Kombi,Kombi_LB,Kombi_PAG
 SG_ PH2_defekt : 56|1@1+ (1.0,0.0) [0.0|1] ""  Vector__XXX
 SG_ PH2_gestoert : 57|1@1+ (1.0,0.0) [0.0|1] ""  Vector__XXX
 SG_ PH2_Systemzustand : 58|3@1+ (1.0,0.0) [0.0|7] ""  Vector__XXX
 SG_ PH2_Display_Kundenwunsch : 61|2@1+ (1.0,0.0) [0.0|3] ""  Vector__XXX

BO_ 2463978617 Parkhilfe2_04: 8 Gateway
 SG_ PH2_Verschmutzungsmeldung : 12|4@1+ (1.0,0.0) [0.0|15] ""  Kombi,Kombi_LB,Kombi_PAG
 SG_ PH2_Aufschaltursache : 16|5@1+ (1.0,0.0) [0.0|31] ""  Vector__XXX
 SG_ PH2_WAH_Meldung : 21|3@1+ (1.0,0.0) [0.0|7] ""  Kombi,Kombi_LB,Kombi_PAG

BO_ 1175 Parkhilfe_01: 8 Gateway
 SG_ PH_Visualisierung : 0|3@1+ (1.0,0.0) [0.0|7] ""  Vector__XXX
 SG_ PDC_Tonausgabe_Front : 4|4@1+ (1.0,0.0) [0.0|15] ""  Kombi,Kombi_LB,Kombi_PAG
 SG_ PDC_Tonausgabe_Heck : 8|4@1+ (1.0,0.0) [0.0|15] ""  Kombi,Kombi_LB,Kombi_PAG
 SG_ PH_nachtr_Stopp_Anf : 12|1@1+ (1.0,0.0) [0.0|1] ""  Vector__XXX
 SG_ PH_Abschaltursache : 13|3@1+ (1.0,0.0) [0.0|7] ""  Vector__XXX
 SG_ PH_Opt_Anzeige_V_ein : 16|1@1+ (1.0,0.0) [0.0|1] ""  Vector__XXX
 SG_ PH_Opt_Anzeige_H_ein : 17|1@1+ (1.0,0.0) [0.0|1] ""  Vector__XXX
 SG_ PH_Opt_Anz_V_Hindernis : 18|1@1+ (1.0,0.0) [0.0|1] ""  Vector__XXX
 SG_ PH_Opt_Anz_H_Hindernis : 19|1@1+ (1.0,0.0) [0.0|1] ""  Vector__XXX
 SG_ PH_Tongeber_V_aktiv : 20|1@1+ (1.0,0.0) [0.0|1] ""  Vector__XXX
 SG_ PH_Tongeber_H_aktiv : 21|1@1+ (1.0,0.0) [0.0|1] ""  Vector__XXX
 SG_ PH_Tongeber_mute : 22|1@1+ (1.0,0.0) [0.0|1] ""  Vector__XXX
 SG_ PH_Anf_Audioabsenkung : 23|1@1+ (1.0,0.0) [0.0|1] ""  Vector__XXX
 SG_ PH_Tongeber_H_verfuegbar : 24|1@1+ (1.0,0.0) [0.0|1] ""  Vector__XXX
 SG_ PLA_Anf_Aufschaltung_RVC : 25|1@1+ (1.0,0.0) [0.0|1] ""  Vector__XXX
 SG_ PH_Taster : 28|2@1+ (1.0,0.0) [0.0|3] ""  Vector__XXX
 SG_ PH_Anf_Verdeck : 30|2@1+ (1.0,0.0) [0.0|3] ""  Vector__XXX
 SG_ PH_Frequenz_hinten : 32|4@1+ (1,0) [0|15] ""  Kombi,Kombi_LB,Kombi_PAG
 SG_ PH_Lautstaerke_hinten : 36|4@1+ (1,0) [0|15] ""  Kombi,Kombi_LB,Kombi_PAG
 SG_ PH_Frequenz_vorn : 40|4@1+ (1,0) [0|15] ""  Kombi,Kombi_LB,Kombi_PAG
 SG_ PH_Lautstaerke_vorn : 44|4@1+ (1,0) [0|15] ""  Kombi,Kombi_LB,Kombi_PAG
 SG_ PH_StartStopp_Info : 49|2@1+ (1.0,0.0) [0.0|3] ""  Vector__XXX
 SG_ PH_Stoermeldung : 52|4@1+ (1.0,0.0) [0.0|15] ""  Kombi,Kombi_LB,Kombi_PAG
 SG_ PH_defekt : 56|1@1+ (1.0,0.0) [0.0|1] ""  Vector__XXX
 SG_ PH_gestoert : 57|1@1+ (1.0,0.0) [0.0|1] ""  Vector__XXX
 SG_ PH_Systemzustand : 58|3@1+ (1.0,0.0) [0.0|7] ""  Vector__XXX
 SG_ PH_Display_Kundenwunsch : 61|2@1+ (1.0,0.0) [0.0|3] ""  Vector__XXX

BO_TX_BU_ 1155 :Gateway,Gateway_PAG;
BO_TX_BU_ 878 :Gateway,Gateway_PAG;
BO_TX_BU_ 2589284146 :Gateway,Gateway_PAG;
BO_TX_BU_ 2589284147 :Gateway,Gateway_PAG;
BO_TX_BU_ 2589284144 :Gateway,Gateway_PAG;
BO_TX_BU_ 2589284145 :Gateway,Gateway_PAG;
BO_TX_BU_ 688 :Gateway,Gateway_PAG;
BO_TX_BU_ 689 :Gateway,Gateway_PAG;
BO_TX_BU_ 1284 :Gateway,Gateway_PAG;
BO_TX_BU_ 1157 :Gateway,Gateway_PAG;
BO_TX_BU_ 2527679512 :Gateway,Gateway_PAG;
BO_TX_BU_ 1696 :Gateway,Gateway_PAG;
BO_TX_BU_ 2600468496 :Gateway,Gateway_PAG;
BO_TX_BU_ 2600468500 :Kombi,Kombi_LB,Kombi_PAG;
BO_TX_BU_ 2600468563 :CGS,Waehlhebel_SB;
BO_TX_BU_ 1635 :Gateway,Gateway_PAG;
BO_TX_BU_ 2527679508 :Gateway,Gateway_PAG;
BO_TX_BU_ 913 :Gateway,Gateway_PAG;
BO_TX_BU_ 2549940736 :Gateway,Gateway_PAG;
BO_TX_BU_ 2549875227 :Gateway,Gateway_PAG;
BO_TX_BU_ 2549875220 :Gateway,Gateway_PAG;
BO_TX_BU_ 2550006292 :Kombi,Kombi_LB,Kombi_PAG;
BO_TX_BU_ 2549875283 :Gateway,Gateway_PAG;
BO_TX_BU_ 2550006355 :CGS,Waehlhebel_SB;
BO_TX_BU_ 2589283656 :Gateway,Gateway_PAG;
BO_TX_BU_ 970 :Gateway,Gateway_PAG;
BO_TX_BU_ 2463978731 :Gateway,Gateway_PAG;
BO_TX_BU_ 908 :Gateway,Gateway_PAG;
BO_TX_BU_ 696 :Gateway,Gateway_PAG;
BO_TX_BU_ 872 :Gateway,Gateway_PAG;
BO_TX_BU_ 2463978617 :Gateway,Gateway_PAG;
BO_TX_BU_ 1175 :Gateway,Gateway_PAG;
CM_ BO_ 1696 "MLBevo ohne KD-Bit";
CM_ BO_ 2600468507 "CAN_NM_PDU MLBevo";
CM_ BO_ 1635 "DLC=8 ab D4 gültig";
CM_ BO_ 2549940736 "VDC funktionaler Request auf CANHS";
CM_ BO_ 1175 "neue Struktur ab MQB ohne KD-Fehler";

CM_ SG_ 1155 MO_Powermeter_Charge_Grenze "Zeigt eine Einschränkung der Rekuperationsleistung an
";
CM_ SG_ 1155 Mo_Powermeter_Grenze "Anzeige des verfügbaren Powermeterstands im Kombi. Bei EV Unterscheidung zwischen Boost- und Dauerbereich, bei HEV für die Zustartgrenze nutzber";
CM_ SG_ 1155 MO_Powermeter_Grenze_strategisch "Zeigt eine strategische Leistungsbeschränkung des Antriebs, 
zum Beispiel kein Boost im Efficiency Modus";
CM_ SG_ 1155 MO_Powermeter_Inszenierung_aktiv "Mit Hilfe des Signals kann eine Dynamikabfahrt für den Kunden inszeniert werden. Die Inszenierung wird im Powermeter des Kombi-Instruments verortet.";
CM_ SG_ 1155 MO_Powermeter_obere_E_Grenze "Zeigt die obere Grenze für das elektrische Fahren an";
CM_ SG_ 1155 MO_Powermeter_untere_E_Grenze "Zeigt die untere Grenze für das elektrische Fahren an";
CM_ SG_ 1155 MO_Text_Aktivierung_Antrieb "Fahrerinformation zur Antriebsstrangaktivierung.";

CM_ SG_ 878 RML_Status_Anzeige_Range "Der Statuswert steuert die Anzeige für den Range Mode in der Anzeigeeinheit.";
CM_ SG_ 878 RML_vMax_Range "Maximale Sollgeschwindigkeit des Range Mode.";

CM_ SG_ 2527679823 MO_WI_FlgInfoTmpLvlVolWa "Trigger für temporäre Füllstandsanzeige";
CM_ SG_ 2527679823 MO_WI_NVEM_HtrPwrReq "Heizleistungsanfrage für Gesamt WI System (Heizungskoordinator Motor)";
CM_ SG_ 2527679823 MO_WI_StWarnVolWa "Füllstandswarnung des WCU Wassertanks";

CM_ SG_ 2589284146 MRR_HL_P_Text_ASCII_01 "Übertragung der Textanzeigen des Kalibrierungsstatus";
CM_ SG_ 2589284146 MRR_HL_P_Text_ASCII_02 "Übertragung der Textanzeigen des Kalibrierungsstatus";
CM_ SG_ 2589284146 MRR_HL_P_Text_ASCII_03 "Übertragung der Textanzeigen des Kalibrierungsstatus";
CM_ SG_ 2589284146 MRR_HL_P_Text_ASCII_04 "Übertragung der Textanzeigen des Kalibrierungsstatus";
CM_ SG_ 2589284146 MRR_HL_P_Text_ASCII_05 "Übertragung der Textanzeigen des Kalibrierungsstatus";
CM_ SG_ 2589284146 MRR_HL_P_Text_ASCII_06 "Übertragung der Textanzeigen des Kalibrierungsstatus";
CM_ SG_ 2589284146 MRR_HL_P_Text_ASCII_07 "Übertragung der Textanzeigen des Kalibrierungsstatus";
CM_ SG_ 2589284146 MRR_HL_P_Text_ASCII_08 "Übertragung der Textanzeigen des Kalibrierungsstatus";
CM_ SG_ 2589284146 MRR_HL_P_Text_ASCII_09 "Übertragung der Textanzeigen des Kalibrierungsstatus";
CM_ SG_ 2589284146 MRR_HL_P_Text_ASCII_10 "Übertragung der Textanzeigen des Kalibrierungsstatus";
CM_ SG_ 2589284146 MRR_HL_P_Text_ASCII_11 "Übertragung der Textanzeigen des Kalibrierungsstatus";
CM_ SG_ 2589284146 MRR_HL_P_Text_ASCII_12 "Übertragung der Textanzeigen des Kalibrierungsstatus";
CM_ SG_ 2589284146 MRR_HL_P_Text_ASCII_13 "Übertragung der Textanzeigen des Kalibrierungsstatus";
CM_ SG_ 2589284146 MRR_HL_P_Text_ASCII_14 "Übertragung der Textanzeigen des Kalibrierungsstatus";
CM_ SG_ 2589284146 MRR_HL_P_Text_ASCII_15 "Übertragung der Textanzeigen des Kalibrierungsstatus";
CM_ SG_ 2589284146 MRR_HL_P_Text_ASCII_16 "Übertragung der Textanzeigen des Kalibrierungsstatus";
CM_ SG_ 2589284146 MRR_HL_P_Text_ASCII_17 "Übertragung der Textanzeigen des Kalibrierungsstatus";
CM_ SG_ 2589284146 MRR_HL_P_Text_ASCII_18 "Übertragung der Textanzeigen des Kalibrierungsstatus";
CM_ SG_ 2589284146 MRR_HL_P_Text_ASCII_19 "Übertragung der Textanzeigen des Kalibrierungsstatus";
CM_ SG_ 2589284146 MRR_HL_P_Text_ASCII_20 "Übertragung der Textanzeigen des Kalibrierungsstatus";
CM_ SG_ 2589284146 MRR_HL_P_Text_ASCII_21 "Übertragung der Textanzeigen des Kalibrierungsstatus";
CM_ SG_ 2589284146 MRR_HL_P_Text_Mux "Übertragung der Textanzeigen des Kalibrierungsstatus";

CM_ SG_ 2589284147 MRR_HR_P_Text_ASCII_01 "Übertragung der Textanzeigen des Kalibrierungsstatus";
CM_ SG_ 2589284147 MRR_HR_P_Text_ASCII_02 "Übertragung der Textanzeigen des Kalibrierungsstatus";
CM_ SG_ 2589284147 MRR_HR_P_Text_ASCII_03 "Übertragung der Textanzeigen des Kalibrierungsstatus";
CM_ SG_ 2589284147 MRR_HR_P_Text_ASCII_04 "Übertragung der Textanzeigen des Kalibrierungsstatus";
CM_ SG_ 2589284147 MRR_HR_P_Text_ASCII_05 "Übertragung der Textanzeigen des Kalibrierungsstatus";
CM_ SG_ 2589284147 MRR_HR_P_Text_ASCII_06 "Übertragung der Textanzeigen des Kalibrierungsstatus";
CM_ SG_ 2589284147 MRR_HR_P_Text_ASCII_07 "Übertragung der Textanzeigen des Kalibrierungsstatus";
CM_ SG_ 2589284147 MRR_HR_P_Text_ASCII_08 "Übertragung der Textanzeigen des Kalibrierungsstatus";
CM_ SG_ 2589284147 MRR_HR_P_Text_ASCII_09 "Übertragung der Textanzeigen des Kalibrierungsstatus";
CM_ SG_ 2589284147 MRR_HR_P_Text_ASCII_10 "Übertragung der Textanzeigen des Kalibrierungsstatus";
CM_ SG_ 2589284147 MRR_HR_P_Text_ASCII_11 "Übertragung der Textanzeigen des Kalibrierungsstatus";
CM_ SG_ 2589284147 MRR_HR_P_Text_ASCII_12 "Übertragung der Textanzeigen des Kalibrierungsstatus";
CM_ SG_ 2589284147 MRR_HR_P_Text_ASCII_13 "Übertragung der Textanzeigen des Kalibrierungsstatus";
CM_ SG_ 2589284147 MRR_HR_P_Text_ASCII_14 "Übertragung der Textanzeigen des Kalibrierungsstatus";
CM_ SG_ 2589284147 MRR_HR_P_Text_ASCII_15 "Übertragung der Textanzeigen des Kalibrierungsstatus";
CM_ SG_ 2589284147 MRR_HR_P_Text_ASCII_16 "Übertragung der Textanzeigen des Kalibrierungsstatus";
CM_ SG_ 2589284147 MRR_HR_P_Text_ASCII_17 "Übertragung der Textanzeigen des Kalibrierungsstatus";
CM_ SG_ 2589284147 MRR_HR_P_Text_ASCII_18 "Übertragung der Textanzeigen des Kalibrierungsstatus";
CM_ SG_ 2589284147 MRR_HR_P_Text_ASCII_19 "Übertragung der Textanzeigen des Kalibrierungsstatus";
CM_ SG_ 2589284147 MRR_HR_P_Text_ASCII_20 "Übertragung der Textanzeigen des Kalibrierungsstatus";
CM_ SG_ 2589284147 MRR_HR_P_Text_ASCII_21 "Übertragung der Textanzeigen des Kalibrierungsstatus";
CM_ SG_ 2589284147 MRR_HR_P_Text_Mux "Übertragung der Textanzeigen des Kalibrierungsstatus";

CM_ SG_ 2589284144 MRR_VL_P_Text_ASCII_01 "Übertragung der Textanzeigen des Kalibrierungsstatus";
CM_ SG_ 2589284144 MRR_VL_P_Text_ASCII_02 "Übertragung der Textanzeigen des Kalibrierungsstatus";
CM_ SG_ 2589284144 MRR_VL_P_Text_ASCII_03 "Übertragung der Textanzeigen des Kalibrierungsstatus";
CM_ SG_ 2589284144 MRR_VL_P_Text_ASCII_04 "Übertragung der Textanzeigen des Kalibrierungsstatus";
CM_ SG_ 2589284144 MRR_VL_P_Text_ASCII_05 "Übertragung der Textanzeigen des Kalibrierungsstatus";
CM_ SG_ 2589284144 MRR_VL_P_Text_ASCII_06 "Übertragung der Textanzeigen des Kalibrierungsstatus";
CM_ SG_ 2589284144 MRR_VL_P_Text_ASCII_07 "Übertragung der Textanzeigen des Kalibrierungsstatus";
CM_ SG_ 2589284144 MRR_VL_P_Text_ASCII_08 "Übertragung der Textanzeigen des Kalibrierungsstatus";
CM_ SG_ 2589284144 MRR_VL_P_Text_ASCII_09 "Übertragung der Textanzeigen des Kalibrierungsstatus";
CM_ SG_ 2589284144 MRR_VL_P_Text_ASCII_10 "Übertragung der Textanzeigen des Kalibrierungsstatus";
CM_ SG_ 2589284144 MRR_VL_P_Text_ASCII_11 "Übertragung der Textanzeigen des Kalibrierungsstatus";
CM_ SG_ 2589284144 MRR_VL_P_Text_ASCII_12 "Übertragung der Textanzeigen des Kalibrierungsstatus";
CM_ SG_ 2589284144 MRR_VL_P_Text_ASCII_13 "Übertragung der Textanzeigen des Kalibrierungsstatus";
CM_ SG_ 2589284144 MRR_VL_P_Text_ASCII_14 "Übertragung der Textanzeigen des Kalibrierungsstatus";
CM_ SG_ 2589284144 MRR_VL_P_Text_ASCII_15 "Übertragung der Textanzeigen des Kalibrierungsstatus";
CM_ SG_ 2589284144 MRR_VL_P_Text_ASCII_16 "Übertragung der Textanzeigen des Kalibrierungsstatus";
CM_ SG_ 2589284144 MRR_VL_P_Text_ASCII_17 "Übertragung der Textanzeigen des Kalibrierungsstatus";
CM_ SG_ 2589284144 MRR_VL_P_Text_ASCII_18 "Übertragung der Textanzeigen des Kalibrierungsstatus";
CM_ SG_ 2589284144 MRR_VL_P_Text_ASCII_19 "Übertragung der Textanzeigen des Kalibrierungsstatus";
CM_ SG_ 2589284144 MRR_VL_P_Text_ASCII_20 "Übertragung der Textanzeigen des Kalibrierungsstatus";
CM_ SG_ 2589284144 MRR_VL_P_Text_ASCII_21 "Übertragung der Textanzeigen des Kalibrierungsstatus";
CM_ SG_ 2589284144 MRR_VL_P_Text_Mux "Übertragung der Textanzeigen des Kalibrierungsstatus";

CM_ SG_ 2589284145 MRR_VR_P_Text_ASCII_01 "Übertragung der Textanzeigen des Kalibrierungsstatus";
CM_ SG_ 2589284145 MRR_VR_P_Text_ASCII_02 "Übertragung der Textanzeigen des Kalibrierungsstatus";
CM_ SG_ 2589284145 MRR_VR_P_Text_ASCII_03 "Übertragung der Textanzeigen des Kalibrierungsstatus";
CM_ SG_ 2589284145 MRR_VR_P_Text_ASCII_04 "Übertragung der Textanzeigen des Kalibrierungsstatus";
CM_ SG_ 2589284145 MRR_VR_P_Text_ASCII_05 "Übertragung der Textanzeigen des Kalibrierungsstatus";
CM_ SG_ 2589284145 MRR_VR_P_Text_ASCII_06 "Übertragung der Textanzeigen des Kalibrierungsstatus";
CM_ SG_ 2589284145 MRR_VR_P_Text_ASCII_07 "Übertragung der Textanzeigen des Kalibrierungsstatus";
CM_ SG_ 2589284145 MRR_VR_P_Text_ASCII_08 "Übertragung der Textanzeigen des Kalibrierungsstatus";
CM_ SG_ 2589284145 MRR_VR_P_Text_ASCII_09 "Übertragung der Textanzeigen des Kalibrierungsstatus";
CM_ SG_ 2589284145 MRR_VR_P_Text_ASCII_10 "Übertragung der Textanzeigen des Kalibrierungsstatus";
CM_ SG_ 2589284145 MRR_VR_P_Text_ASCII_11 "Übertragung der Textanzeigen des Kalibrierungsstatus";
CM_ SG_ 2589284145 MRR_VR_P_Text_ASCII_12 "Übertragung der Textanzeigen des Kalibrierungsstatus";
CM_ SG_ 2589284145 MRR_VR_P_Text_ASCII_13 "Übertragung der Textanzeigen des Kalibrierungsstatus";
CM_ SG_ 2589284145 MRR_VR_P_Text_ASCII_14 "Übertragung der Textanzeigen des Kalibrierungsstatus";
CM_ SG_ 2589284145 MRR_VR_P_Text_ASCII_15 "Übertragung der Textanzeigen des Kalibrierungsstatus";
CM_ SG_ 2589284145 MRR_VR_P_Text_ASCII_16 "Übertragung der Textanzeigen des Kalibrierungsstatus";
CM_ SG_ 2589284145 MRR_VR_P_Text_ASCII_17 "Übertragung der Textanzeigen des Kalibrierungsstatus";
CM_ SG_ 2589284145 MRR_VR_P_Text_ASCII_18 "Übertragung der Textanzeigen des Kalibrierungsstatus";
CM_ SG_ 2589284145 MRR_VR_P_Text_ASCII_19 "Übertragung der Textanzeigen des Kalibrierungsstatus";
CM_ SG_ 2589284145 MRR_VR_P_Text_ASCII_20 "Übertragung der Textanzeigen des Kalibrierungsstatus";
CM_ SG_ 2589284145 MRR_VR_P_Text_ASCII_21 "Übertragung der Textanzeigen des Kalibrierungsstatus";
CM_ SG_ 2589284145 MRR_VR_P_Text_Mux "Übertragung der Textanzeigen des Kalibrierungsstatus";

CM_ SG_ 688 MO_Rekuperation_EM_Ges_Ueberlauf "Rekuperationleistungssignal mindest 1x übergelaufen";
CM_ SG_ 688 MO_Rekuperation_Ges_EM "Rekuperation-Energie des Antriebs";
CM_ SG_ 688 MO_Verbrauch_EM_Ges "Antriebs-Energie des Antriebs";
CM_ SG_ 688 MO_Verbrauch_EM_Ges_Ueberlauf "Verbrauchssignal mindest 1x übergelaufen";

CM_ SG_ 689 TME_Energie_Komfort "Energieverbrauch für die Vorkonditionierung des Innenraums (beim Laden)";
CM_ SG_ 689 TME_Energie_Thermo "Energieverbrauch für die Temperierung der Bauteile (beim Laden)";
CM_ SG_ 689 TME_PlanAntw_Zaehler "TME Antwort-Zähler der Ladeplan-Anfragen des ILF";
CM_ SG_ 689 TME_Verbrauch_gesamt "Energieverbrauch vom TME für Komfort- und Thermo-Bereich";
CM_ SG_ 689 TME_Verbrauch_gesamt_Ueberlauf "Überlauf-Bit für das Signal TME_Verbrauch_gesamt";

CM_ SG_ 1284 MV_Bordnetz_aktiv "Signalisiert ein aktives MV-Bordnetz. MV-Schütze geschlossen.";
CM_ SG_ 1284 MV_Bordnetz_Fehler "Status ob im  MV-Netz ein Fehler detektiert wurde.";
CM_ SG_ 1284 MVK_01_BZ "4bit Botschaftszähler, wird mit jeder Sendebotschaft inkrementiert";
CM_ SG_ 1284 MVK_01_CRC "Für MLB:
Berechnung siehe Lastenheft 'Kommunikationsabsicherung für FlexRay und CAN'
Ab MQB und MLBevo:
Berechnung siehe Lastenheft 'End-to-End Kommunikationsabsicherung'

Endwerte siehe Begleitdokument 'S-PDU Kennungsfolgen'";
CM_ SG_ 1284 MVK_BMS_Sollmodus "Angeforderter Sollmodus der MV-Batterie:
0 : MV_Off                                
1 : MV_On (HS geschlossen)                
2 : nicht belegbar                        
3 : nicht belegbar                        
4 : nicht belegbar 
5 : nicht belegb";
CM_ SG_ 1284 MVK_BOOST_Sollmodus "Sollmodus eBooster auf 48V
0 : keine Freigabe
1 : Freigabe
2 : nicht belegbar
3 : nicht belegbar
4 : nicht belegbar
5 : nicht belegbar
6 : nicht belegbar
7 : Init   (CAN-Initialisierung)   

Info: 'nicht belegbar' d.h. Sollmodus nicht relevant f";
CM_ SG_ 1284 MVK_DCDC_Sollmodus "angeforderte Soll-Betriebsart des 48V DC/DC-Wandlers: 
0: Standby; Kommunikation aktiv
1: MvOn (48V-Netz ist aktiv)
2: Tiefsetzen (48V --> BN 14,4V)
3: Hochsetzen (BN 14,4V --> 48V)
4: Startunterstuetzung_48V (Stützung des 48V-BN im Startvorgang)
5:";
CM_ SG_ 1284 MVK_DCDC_Sollmodus_02 "Angeforderte Soll-Betriebsart des 48V DC/DC-Wandlers: 
0: Standby; Kommunikation aktiv
1: MvOn (48V-Netz ist aktiv)
2: Tiefsetzen (48V --> BN12)
3: Hochsetzen (BN12 --> 48V)
4: Startunterstuetzung_48V (Stützung des 48V-BN im Startvorgang)
5: nicht v";
CM_ SG_ 1284 MVK_eABC_Sollmodus "Sollmodus eABC auf 48V
0 : keine Freigabe
1 : Freigabe
2 : nicht belegbar
3 : nicht belegbar
4 : nicht belegbar
5 : nicht belegbar
6 : nicht belegbar
7 : Init   (CAN-Initialisierung)   

Info: 'nicht belegbar' d.h. Sollmodus nicht relevant für M";
CM_ SG_ 1284 MVK_eAWS_Sollmodus "Sollmodus eAWS auf 48V
0 : keine Freigabe
1 : Freigabe
2 : nicht belegbar
3 : nicht belegbar
4 : nicht belegbar
5 : nicht belegbar
6 : nicht belegbar
7 : Init   (CAN-Initialisierung)   

Info: 'nicht belegbar' d.h. Sollmodus nicht relevant für M";
CM_ SG_ 1284 MVK_eKAT_Sollmodus "Angeforderter Sollmodus des eKAT";
CM_ SG_ 1284 MVK_eKMV_Sollmodus "Sollmodus MVK --> TME für Ansteuerung des eKMV";
CM_ SG_ 1284 MVK_Istmodus_Anf "MVK-Anforderung an alle 48V-Komponenten deren Istmodus im schnellen Zyklus (Inhibitzeit) zu senden.";
CM_ SG_ 1284 MVK_MO_EmSollzustand "Anforderung vom MVK Sollzustand der Elm_State
0 = MvOff              
1 = MvStbyReq          
2 = MvStbyWait         
3 = MvBattOnReq        
4 = MvBattOnWait       
10 = MvOnIdle          
18 = MvOnDrvReq        
19 = MvOnDrvWait       
20 = MvO";
CM_ SG_ 1284 MVK_MV_Netz_Warnungen "Anforderung Warnung/Fehler MV-System im Kombi
0: Keine Warnung/Init
1:Anforderung_Anzeige_Warnung_MV-Netz (gelbes Symbol)
2:Anforderung_Anzeige_Fehler_MV-Netz (rotes Symbol)
3:Anforderung_Anzeige_Warnung_Kein_Wiederstart_möglich";
CM_ SG_ 1284 MVK_MVH_L_Sollmodus "Sollmodus MVK --> TME für Ansteuerung des MVH_L";
CM_ SG_ 1284 MVK_MVPTC_Sollmodus "Sollmodus MV-PTC
0 : keine Freigabe
1 : Freigabe
2 : nicht belegbar
3 : nicht belegbar
4 : nicht belegbar
5 : nicht belegbar
6 : nicht belegbar
7 : Init   (CAN-Initialisierung)   

Info: 'nicht belegbar' d.h. Sollmodus nicht relevant für MVK";

CM_ SG_ 1157 ND_SatInUse "Anzahl der zur Berechnung verwendeten Satelliten";
CM_ SG_ 1157 ND_SatInView "Anzahl der sichtbaren Satelliten";
CM_ SG_ 1157 ND_UTC "UTC-Zeit, verstrichene Sekunden seit 01.01.1970 00:00
0xFFFFFFFE = Init
0xFFFFFFFF = Fehler bei Berechnung der UTC-Time";
CM_ SG_ 1157 NP_Altitude "Hoehe ueber NN
0xFFF = Fehler bei der Berechnung der Höhe über NN";
CM_ SG_ 1157 POS_Guete_horizontal "Horizontale Genauigkeit der Position in der Botschaft NavPos_02_MapMatched (Signale
POS_LatDegree, POS_LongDegree)

Abhängig vom Signal
POS_Guete_horizontal_verfuegbar";
CM_ SG_ 1157 POS_Guete_horizontal_verfuegbar "Bei gesetztem Bit wird das Signal POS_Guete_horizontal befüllt und ist verfügbar.";

CM_ SG_ 2527679512 ND_Fuelstation_detected "Signal gibt an ob eine Tankstelle erkannt wurde";
CM_ SG_ 2527679512 ND_NrSameMeasure "GPS Anzahl der gleichen Messungen";
CM_ SG_ 2527679512 ND_RecDelay "Für MLBevo:
Zeit in ms zwischen zwei Interruptauslösungen des GPS Receiver.

Für MLBevoGen2:
Zeit in ms zwischen UTC-Sekunde und Messzeitpunkt des GPS Receiver.";
CM_ SG_ 2527679512 ND_RouteType "Routentyp.";
CM_ SG_ 2527679512 ND_SendDelay "Zeit in ms zwischen Interruptauslösung GPS Receiver (Beginn der Messung) und Senden auf den CAN Bus.";
CM_ SG_ 2527679512 ND_TimeOffset "Offset zu ND_TimeToDestination.";
CM_ SG_ 2527679512 ND_TimeToDestination "Zeit in min bis zum Erreichen des Ziel. Wird ausgegeben bei aktiver Routenführung oder bei gelernter Route (MPR).";
CM_ SG_ 2527679512 ND_Timezone_DaylightSavingOffset "Offest der Sommerzeit/Winterzeit
 
0 = kein Offset ; 
1 = 0,5h;  
2 = 1h";
CM_ SG_ 2527679512 ND_Timezone_Offset "Aktuelle Zeitzonen-Offset des Fahrzeugs.
Vorzeichen und Gültigkeit beachten";
CM_ SG_ 2527679512 ND_Timezone_SignBit "Vorzeichen des Zeitzonenoffsets.";
CM_ SG_ 2527679512 ND_Timezone_Validity "Gültigkeit des Zeitzonensignals.";
CM_ SG_ 2527679512 ND_Velocity "GPS Geschwindigkeit";

CM_ SG_ 1696 NV_Akt_Status_MMI "Zustand des Nightvison Systems im MMI: Warnalgo & NV-Reiter Ein/Aus

";
CM_ SG_ 1696 NV_aktiv "Nightvision aktiviert (liefert Bild)";
CM_ SG_ 1696 NV_Akustik_deaktiviert_Icon "Ansteuerungssignal für das  Akustik-deaktiviert-Icon";
CM_ SG_ 1696 NV_Anf_Prefill "Anforderung an ESP, dass die Prefill-Funktion aktiviert werden soll.";
CM_ SG_ 1696 NV_AnforderungBildaufschaltung "Automatische Bildaufschaltung im Warnfall";
CM_ SG_ 1696 NV_FAS_Fkt_Status "Signal für FAS Profile-Master";
CM_ SG_ 1696 NV_FGM_deaktiviert_Icon "Ansteuerungssignal für das  Fussgängermarkierung-deaktiviert-Icon";
CM_ SG_ 1696 NV_Gong "Das Signal löst einen Gong des NightVision-Systems im Kombidisplay aus";
CM_ SG_ 1696 NV_HBA_Parameter "Anforderung an ESP, welcher HBA-Parametersatz verwendet werden soll. Die Festlegung der Empfindlichkeitsschwellen der verschiedenen Parametersätze erfolgt mit der Applikation des Gesamtsystems ESP/ACC bzw. des HBA.
Nur Audi B8: Umsetzung der Anforderung ";
CM_ SG_ 1696 NV_Hinweise "Das Signal dient dazu Hinweistexte in das NightVision Bild im Kombiinstrument einzublenden.Die Anzeigedauer der Hinweistexte ist Signalgesteuert. D.h., sie werden angezeigt bis das CAN-Signal s_NV_Texte seinen Wert ändert.";
CM_ SG_ 1696 NV_LED_Leiste "Ansteuerung_LED_Warnleiste";
CM_ SG_ 1696 NV_Markierungslicht_links "Das Signal steuert die Aktivierung des Markierungslicht links bei Fußgängerwarnung";
CM_ SG_ 1696 NV_Markierungslicht_rechts "Das Signal steuert die Aktivierung des Markierungslicht rechts bei Fußgängerwarnung";
CM_ SG_ 1696 NV_Piktogramm_aktiv "Signal sagt, dass das Piktogramm im NightVision-Reiter geändert werden soll";
CM_ SG_ 1696 NV_PreSense_Modus_System "Signal zur Realisierung der BAP-Kommunikation für PreSense";
CM_ SG_ 1696 NV_PreSense_Modus_Warnung "Signal zur Realisierung der BAP-Kommunikation für PreSense";
CM_ SG_ 1696 NV_PreSense_Status "Signal zur Realisierung der BAP-Kommunikation für PreSense";
CM_ SG_ 1696 NV_Symbol "Wenn das NV-System einen Fußgänger findet, fordert es mit dem Signal das HUD auf, ein Symbol zu zeigen";
CM_ SG_ 1696 NV_Symbol_Tierwarnung "Signal zur Anforderung einer Symbolanzeige für Tierwarnung.";
CM_ SG_ 1696 NV_Texte "Angeforderte Textmeldung";

CM_ SG_ 2600468496 NM_Gateway_CAB "CAB = Clusteraktivbits";
CM_ SG_ 2600468496 NM_Gateway_Car_Wakeup "Car Wakeup (Subbusmaster wertet aus)

MQB: 
-Diagnose- oder Komponentenschutzmaster-Funktion weckt den schlafenden Subbus (z.B. MOST)

E3_Volumen:
- Diagnose aktiv -aktive Diagnosekommunikation am OBD-Stecker

MQBw_Baseline:
- Diagnose aktiv -akt";
CM_ SG_ 2600468496 NM_Gateway_CBV_AWB "Das Signal ist zu setzen, wenn das SG aktiv den Bus geweckt hat
0 = Passiver_WakeUp = SG hat das Netzwerk nicht aktiv geweckt
1 = Akitiver_WakeUp = SG hat das Netzwerk aktiv geweckt";
CM_ SG_ 2600468496 NM_Gateway_CBV_CRI "Das Signal ist dauerhaft gesetzt, wenn das NM-Layout Cluster- Anforderungen enthält";
CM_ SG_ 2600468496 NM_Gateway_NM_aktiv_Buskopplung "Nachlauf aufgrund Kopplung zweier Busse. z.B. K-CAN und K2-CAN";
CM_ SG_ 2600468496 NM_Gateway_NM_aktiv_Connect "Nachlauf aufgrund Connect";
CM_ SG_ 2600468496 NM_Gateway_NM_aktiv_CWU "Nachlauf aufgrund CWU Anforderung";
CM_ SG_ 2600468496 NM_Gateway_NM_aktiv_Diagnose "Diagnose befindet sich nach VW80124 in einer NonDefaultDiagnostic-Session, z.B. ExtendedDiagnostic-Session";
CM_ SG_ 2600468496 NM_Gateway_NM_aktiv_EM "Nachlauf aufgrund Energiemanagement";
CM_ SG_ 2600468496 NM_Gateway_NM_aktiv_FC "Nachlauf aufgrund Funktionscluster Anforderung";
CM_ SG_ 2600468496 NM_Gateway_NM_aktiv_Fremdladung "Nachlauf aufgrund Fremdladung";
CM_ SG_ 2600468496 NM_Gateway_NM_aktiv_KL15 "Steuergerät hat KL15-EIN erkannt";
CM_ SG_ 2600468496 NM_Gateway_NM_aktiv_LIN2 "Bus aktiv aufgrund aktivem LIN2 (Hupe betätigt)";
CM_ SG_ 2600468496 NM_Gateway_NM_aktiv_OBDC "Nachlauf aufgrund OBDC";
CM_ SG_ 2600468496 NM_Gateway_NM_aktiv_Tmin "Mindestaktivzeit ist noch nicht abgelaufen (bei jedem Weckereignis wird die Mindestaktivzeit neu gestartet)";
CM_ SG_ 2600468496 NM_Gateway_NM_State "1 = Zustand Repeat Message (<-- Bus-Sleep Mode)
2 = Zustand Repeat Message (<-- Prepare Bus-Sleep Mode)
4 = Zustand Normal Operation (<-- Repeat Message)
8 = Zustand Normal Operation (<-- Ready Sleep)";
CM_ SG_ 2600468496 NM_Gateway_SNI "Source Node-Identifier (SNI) identifiziert den Sender der NM-Botschaft (Knotenadresse) eindeutig im Fahrzeug";
CM_ SG_ 2600468496 NM_Gateway_UDS_CC "Funktionseinschränkung aufgrund aktivem UDS-Communication Control, siehe VW80124";

CM_ SG_ 2600468507 NM_HUD_CAB "CAB = Clusteraktivbits";
CM_ SG_ 2600468507 NM_HUD_Car_WakeUp "Das Bit wird vom Waehlhebel nicht bedient. Die Car Wakeup-Funktionalität ist im Waehlhebel nicht umgesetzt.
";
CM_ SG_ 2600468507 NM_HUD_CBV_AWB "Das Signal ist zu setzen, wenn das SG aktiv den Bus geweckt hat
0 = Passiver_WakeUp = SG hat das Netzwerk nicht aktiv geweckt
1 = Akitiver_WakeUp = SG hat das Netzwerk aktiv geweckt";
CM_ SG_ 2600468507 NM_HUD_CBV_CRI "Das Signal ist dauerhaft gesetzt, wenn das NM-Layout Cluster- Anforderungen enthält";
CM_ SG_ 2600468507 NM_HUD_NM_aktiv_Diagnose "Diagnose befindet sich nach VW80124 in einer NonDefaultDiagnostic-Session, z.B. ExtendedDiagnostic-Session";
CM_ SG_ 2600468507 NM_HUD_NM_aktiv_KL15 "Steuergerät hat KL15-EIN erkannt";
CM_ SG_ 2600468507 NM_HUD_NM_aktiv_Tmin "Mindestaktivzeit ist noch nicht abgelaufen (bei jedem Weckereignis wird die Mindestaktivzeit neu gestartet)";
CM_ SG_ 2600468507 NM_HUD_NM_State "1 = Zustand Repeat Message (<-- Bus-Sleep Mode)
2 = Zustand Repeat Message (<-- Prepare Bus-Sleep Mode)
4 = Zustand Normal Operation (<-- Repeat Message)
8 = Zustand Normal Operation (<-- Ready Sleep)";
CM_ SG_ 2600468507 NM_HUD_SNI "Source Node-Identifier (SNI) identifiziert den Sender der NM-Botschaft (Knotenadresse) eindeutig im Fahrzeug";
CM_ SG_ 2600468507 NM_HUD_UDS_CC "Funktionseinschränkung aufgrund aktivem UDS-Communication Control, siehe VW80124";

CM_ SG_ 2600468500 NM_Kombi_CAB "CAB = Clusteraktivbits";
CM_ SG_ 2600468500 NM_Kombi_Car_Wakeup "Car Wakeup (Gateway wertet aus)
MQB: Timer abgelaufen, Zeitverstellung manuell oder automatisch (>5Min) beim aktiven Timer, Verlassenswarnung

MLBevo: Timer abgelaufen, Zeitverstellung manuell oder automatisch (>5Min) beim aktiven Timer
Berechnung Tan";
CM_ SG_ 2600468500 NM_Kombi_CBV_AWB "Das Signal ist zu setzen, wenn das SG aktiv den Bus geweckt hat";
CM_ SG_ 2600468500 NM_Kombi_CBV_CRI "Das Signal ist dauerhaft gesetzt, wenn das NM-Layout dem neuen NM-Layout für Teilnetzbetrieb entspricht";
CM_ SG_ 2600468500 NM_Kombi_NM_aktiv_Buzzer "Buzzer Weckereignis aktiv (1 Minute)";
CM_ SG_ 2600468500 NM_Kombi_NM_aktiv_Diagnose "Diagnose befindet sich nach VW80124 in einer NonDefaultDiagnostic-Session, z.B. ExtendedDiagnostic-Session";
CM_ SG_ 2600468500 NM_Kombi_NM_aktiv_Display "Display ist im Kombi aktiv und Anzeigen erfolgen";
CM_ SG_ 2600468500 NM_Kombi_NM_aktiv_KL15 "Steuergerät hat KL15-EIN erkannt";
CM_ SG_ 2600468500 NM_Kombi_NM_aktiv_Tankinhalt "Ermittlung des Tankinhaltes aktiv";
CM_ SG_ 2600468500 NM_Kombi_NM_aktiv_Tmin "Mindestaktivzeit ist noch nicht abgelaufen (bei jedem Weckereignis wird die Mindestaktivzeit neu gestartet)";
CM_ SG_ 2600468500 NM_Kombi_NM_State "1 = Zustand Repeat Message (<-- Bus-Sleep Mode)
2 = Zustand Repeat Message (<-- Prepare Bus-Sleep Mode)
4 = Zustand Normal Operation (<-- Repeat Message)
8 = Zustand Normal Operation (<-- Ready Sleep)";
CM_ SG_ 2600468500 NM_Kombi_SNI "Source Node-Identifier (SNI) identifiziert den Sender der NM-Botschaft (Knotenadresse) eindeutig im Fahrzeug";
CM_ SG_ 2600468500 NM_Kombi_UDS_CC "Funktionseinschränkung aufgrund aktivem UDS-Communication Control; siehe VW80124";

CM_ SG_ 2600468563 NM_Waehlhebel_CAB "CAB = Clusteraktivbits";
CM_ SG_ 2600468563 NM_Waehlhebel_Car_Wakeup "Car Wakeup (Gateway wertet aus)

MLBevo: Fahrerwunsch_P";
CM_ SG_ 2600468563 NM_Waehlhebel_CBV_AWB "Das Signal ist zu setzen, wenn das SG aktiv den Bus geweckt hat
0 = Passiver_WakeUp = SG hat das Netzwerk nicht aktiv geweckt
1 = Akitiver_WakeUp = SG hat das Netzwerk aktiv geweckt";
CM_ SG_ 2600468563 NM_Waehlhebel_CBV_CRI "Das Signal ist dauerhaft gesetzt, wenn das NM-Layout Cluster- Anforderungen enthält";
CM_ SG_ 2600468563 NM_Waehlhebel_NM_aktiv_Diagnose "Diagnose befindet sich nach VW80124 in einer NonDefaultDiagnostic-Session, z.B. ExtendedDiagnostic-Session";
CM_ SG_ 2600468563 NM_Waehlhebel_NM_aktiv_KL15 "Steuergerät hat KL15-EIN erkannt";
CM_ SG_ 2600468563 NM_Waehlhebel_NM_aktiv_Tmin "Mindestaktivzeit ist noch nicht abgelaufen (bei jedem Weckereignis wird die Mindestaktivzeit neu gestartet)";
CM_ SG_ 2600468563 NM_Waehlhebel_NM_State "1 = Zustand Repeat Message (<-- Bus-Sleep Mode)
2 = Zustand Repeat Message (<-- Prepare Bus-Sleep Mode)
4 = Zustand Normal Operation (<-- Repeat Message)
8 = Zustand Normal Operation (<-- Ready Sleep)";
CM_ SG_ 2600468563 NM_Waehlhebel_SNI "Source Node-Identifier (SNI) identifiziert den Sender der NM-Botschaft (Knotenadresse) eindeutig im Fahrzeug";
CM_ SG_ 2600468563 NM_Waehlhebel_UDS_CC "Funktionseinschränkung aufgrund aktivem UDS-Communication Control, siehe VW80124";

CM_ SG_ 1635 BEM_02_Abschaltstufen "Abschaltstufen des Ruhestrommanagements (Initialisierungswert aus EEprom)

Stufe 0 (keine Einschraenkungen)
Stufe 1 (Abschaltung Hochstromverbraucher)
Stufe 2 (Infotainmentabschaltung)
Stufe 3 (Wake-Up-Sperre)

Für den Transport- und Ruhestrommessm";
CM_ SG_ 1635 BEM_Anf_KL15_schalten "Abschaltempfehlung bzw. Verhinderung der automatischen Abschaltung Kl15 durch das BCM";
CM_ SG_ 1635 BEM_Batteriediagnose "Anzeige von Textwarnungen";
CM_ SG_ 1635 BEM_Generatordiagnose "Ansteuerung Generatorwarnleuchte im Kombi
";
CM_ SG_ 1635 BEM_HL_Regelung_Status "Status Regelung Heizleistung
";
CM_ SG_ 1635 BEM_Ladezustand "Ladezustand der Niedervoltbatterie
";
CM_ SG_ 1635 BEM_MMI_Vorwarnung "Anzeige Vorwarnung MMI-Abschaltung (Initialisierungswert aus EEprom)
";
CM_ SG_ 1635 BEM_Red_Innengeblaese "Reduzierung Innengebläse
";
CM_ SG_ 1635 BEM_REK_aktiv "Rekuperationsfreigabe vom Energiemanagement
0x0 = keine Rekuperationsfreigabe
0x1 = Rekuperationsfreigabe";
CM_ SG_ 1635 BEM_STH_Einschaltverbot "Einschränkung Standheizung/-lüftung durch BEM: Setzt der BEM das Bit, dann darf die Standheizung nicht mehr einschalten
(Die Standheizung muss aber nicht abschalten, sondern darf weiterbrennen)
(Initialisierungswert aus EEprom)
";
CM_ SG_ 1635 BEM_STH_Zielzeit "Maximal mögliche Zeit für den Standheizungsbetrieb, um die Startfähigkeit nicht zu gefährden";
CM_ SG_ 1635 BEM_UBDM "Batteriespannung, gemessen vom Batteriedatenmodul";
CM_ SG_ 1635 BEM_UGenSoll "Sollspannungsvorgabe an den Generator, beinhaltet temperaturoptimierte Batterieladung und Rekuperation";
CM_ SG_ 1635 MIB_Stromsparmodus "Signal beschreibt die Aktivierung für den Stromsparmodus beim MIB.
Bei AUS (= 0) gibt es keine weitere Anforderung an die MIB-Komponenten.
Bei EIN (= 1) werden alle MIB Komponenten in einen Stromsparmodus versetzt.";
CM_ SG_ 1635 NVEM_Anf_SD_schalten "Anforderung Nachlauf für den Steckdosenbetrieb
Initialisierungswert aus EEprom";
CM_ SG_ 1635 NVEM_Batterie_Service "Anforderung einer Batterie-Service - Anzeige / Anforderung an die Werkstatt über MOD";
CM_ SG_ 1635 NVEM_Freigabe_OnlineUpdate "Freigabe für Online-Update durch Energiemanagement";
CM_ SG_ 1635 NVEM_Freigabe_ORU4 "Bestätigung oder Ablehnung eines konkreten, angefragten Online Updates durch das Energiemanagements";
CM_ SG_ 1635 NVEM_Last_Anf "Das NVEM fordert für die Batteriediagnose einen Lastimpuls vom Fahrzeug an, der durch kontrollierte Verbraucherzuschaltungen (z. B. Aktivierung Heckscheibenheizung) generiert wird";

CM_ SG_ 2527679508 NVEM_06_BZ "4bit Botschaftszähler, wird mit jeder Sendebotschaft inkrementiert";
CM_ SG_ 2527679508 NVEM_06_CRC "Für MLB:
'Berechnung siehe Lastenheft 'Kommunikationsabsicherung für FlexRay und CAN''

Ab MQB und MLBevo:
'Berechnung siehe Lastenheft 'End-to-End Kommunikationsabsicherung''

Endwerte siehe Begleitdokument 'S-PDU Kennungsfolgen'";
CM_ SG_ 2527679508 NVEM_Bordnetzdiagnose "Wird vom NVEM im NV-Netz ein Bordnetz-Fehler erkannt, so soll dies zu einer mehrstufigen Anzeige führen.";
CM_ SG_ 2527679508 NVEM_Energie_Klima_Vorgabe "NVEM-Energievorgabe für Klima-Vorkonditionierung";
CM_ SG_ 2527679508 NVEM_Max_Rampenzeit "Vorgabe der max. Rampenzeit für den Generatorbetrieb des 12V-RSG (RSG-Ansteuerung durch Motor-SG)";
CM_ SG_ 2527679508 NVEM_Max_Spannung "Mild_Hybrid: erlaubte Maximalspannung 12V - Netz
";
CM_ SG_ 2527679508 NVEM_Min_Spannung "Mild_Hybrid: erforderliche Mindestspannung 12V - Netz";
CM_ SG_ 2527679508 NVEM_Min_Spannung_Start "Minimale einzuhaltende Spannung im RSG Wiederstart";
CM_ SG_ 2527679508 NVEM_MV_DC_uMinLV "Abregelgrenze: minimal erlaubte Bordnetzspannung im Hochsetzbetrieb vom 12V-Bordnetz ins 48V-Netz";
CM_ SG_ 2527679508 NVEM_MV_DC_uSollLV "Sollwert für die 12V-Bordnetzspannung im Tiefsetzbetrieb vom 48V-Netz ins 12V-Bordnetz";

CM_ SG_ 913 MO_QBit_Aussen_Temp "QBit der Aussentemperatur. Gesetzt bei Ersatzwert, Init oder Fehler.";
CM_ SG_ 913 MO_Servicemodus "Ausgabe aktiver Service-Mode";
CM_ SG_ 913 OBD_Abs_Load_Val "Absolute Load Value

Übertragung von Meßgrößen an das Getriebesteuergerät für Freeze Frame Abspeicherung bei Getriebefehlern

PID $43 Absolute Load Value; 0 .. 25700%  mit 100/255 %/bit";
CM_ SG_ 913 OBD_Abs_Pedal_Pos "Absolute Pedal Position

Übertragung von Meßgrößen an das Getriebesteuergerät für Freeze Frame Abspeicherung bei Getriebefehlern

PID $49 Accelerator Pedal Position D; 0 .. 100% mit 100/255 %/bit";
CM_ SG_ 913 OBD_Abs_Throttle_Pos "Absolute Throttle Position

Übertragung von Meßgrößen an das Getriebesteuergerät für Freeze Frame Abspeicherung bei Getriebefehlern

PID $11 Absolute Throttle Position; 0 .. 100% mit 100/255 %/bit";
CM_ SG_ 913 OBD_Calc_Load_Val "Calculated Load Value

Übertragung von Meßgrößen an das Getriebesteuergerät für Freeze Frame Abspeicherung bei Getriebefehlern

PID $04 Calculated Load Value; 0 .. 100% mit 100/255 % per bit
";
CM_ SG_ 913 OBD_ClearMem_Inhibit "Bei FSP_Loeschen_zulässig müssen alle OBD-ECUs im Gesamtfahrzeug einen Service 04hex Request (Ereignisspeicher löschen) korrekt ausführen. 

In MLB-, MLBevo-, MQB-Fahrzeugkonzepten muss der MIL-Master/Motorsteuergerät bei Kl.15 ein, projektabhängig, kon";
CM_ SG_ 913 OBD_Driving_Cycle "Signalisierung Driving Cycle Qualifizierung - Trigger Ignition Cycle Counter";
CM_ SG_ 913 OBD_Eng_Cool_Temp "Engine Coolant Temperature

Übertragung von Meßgrößen an das Getriebesteuergerät für Freeze Frame Abspeicherung bei Getriebefehlern

PID $05 Engine Coolant Temperature; -40 .. +215°C mit 1°C/bit und 40°C Offset";
CM_ SG_ 913 OBD_Kaltstart_Denominator "Bestimmte Diagnosen werden nur unter Kaltstartbedingungen durchgeführt, der entsprechende Denominator bei IUMPR-pflichtigen Systemen wird anhand dieses vom MSG gebildeten Signals inkrementiert. (Entspricht EVAP-Denominator)";
CM_ SG_ 913 OBD_Minimum_Trip "Grundlage OBD-Gesetz CCR 1968.2 (d)(4.3) Denominator Specifications
Bildung des General Denominator 'Normed Trip':
 600 sec. (kumulativ) Zeit nach Motorstart
 300 sec. (kumulativ) mit Fahrzeuggeschwindigkeit > 25 mph (40 km/h)
 30 sec. (kontinuierlich";
CM_ SG_ 913 OBD_Normed_Trip "Gesetzlich definierte 'Normed Condition' erfüllt, 'General Denominator' darf erhöht werden";
CM_ SG_ 913 OBD_Sperrung_IUMPR "Wenn der General Denominator auf Grund eines Fehlers in den Eingangsgrößen gesperrt wird, wird diese Information über Bussystem als OBD-Statusinformation OBD_Sperrung_IUMPR für andere OBD-Steuergeräte bereitgestellt. 

Das MSG (MIL-Master) setzt dieses ";
CM_ SG_ 913 OBD_Sperrung_Kaltstart_Denom "Information vom MIL Master, dass die Bildung des EVAP Denominators  im Motor nicht möglich ist und damit der noECM-Denominator gesperrt werden darf.";
CM_ SG_ 913 OBD_Warm_Up_Cycle "Mit dem Warm-Up-Cycle wird der zentrale Verlernzähler vom Gateway inkrementiert";

CM_ SG_ 2549940736 OBDC_Funktionaler_Req_All_Data "VDC funktionaler Request auf CANHS";

CM_ SG_ 2589283656 ORU_Status "Verteilung des internen ORU Zustandes";
CM_ SG_ 2589283656 ORU_Warnung "Wenn durch Störungen der Funktion Online Remote Update nicht sichergestellt ist, dass vor Kunde keine Funktionseinschränkungen auftreten, muss der Benutzer des Fahrzeugs entsprechend gewarnt werden.";

CM_ SG_ 2527679670 ORU_EM_Anfrage_Flashdauer "Anfrage an das Energiemanagement, ob ein konkretes Online Remote Update durchgeführt werden kann - Flashdauer in 10s.";
CM_ SG_ 2527679670 ORU_EM_Anfrage_freigegebeneNetze "Meldung der während eines konkreten Online Remote Updates freigegebenen Netze (12V, 48V, HV)";
CM_ SG_ 2527679670 ORU_EM_Anfrage_Stromaufnahme "Meldung der voraussichtlichen durchschnittlichen Stromaufnahme eines konkreten Online Remote Updates an das NVEM";
CM_ SG_ 2527679670 ORU_Status_Anf "Übertragung des Status der Funktion Online Remote Update im Porsche / OTA-FC Fall: Sender ist OTA-FC, GW patcht den Inhalt auf ORU_Status";
CM_ SG_ 2527679670 OTA_FC_FahrwerkAnf "Fahrwerk Anforderung OTA-FC";
CM_ SG_ 2527679670 OTA_FC_FoD_Stornierung "Falls der Kunde eine Assistenz-Funktion storniert, muss der Fahrer darüber informiert werden.
Dies geschieht zum einen durch ein FoD-Icon und andererseits durch einen Anzeigetext.";
CM_ SG_ 2527679670 OTA_FC_Hinweis_Update "Funktion: SWaP online und SW Update
Hinweismeldung, wenn ein OTA SW-Update/Aktivierung verfügbar ist";
CM_ SG_ 2527679670 OTA_FC_IOF_Ausfall "Funktion: IOF (PIDM)
Warnmeldung, wenn Funktion IOF (PIDM) ist ausgefallen ist";
CM_ SG_ 2527679670 OTA_FC_LiftAnf "OTA-FC Lift Anforderung";
CM_ SG_ 2527679670 OTA_FC_NiveauAnf "OTA-FC Niveau Anforderung";
CM_ SG_ 2527679670 OTA_FC_PredMaint_Ausfall "Funktion: Predictive Maintenance
Warnmeldung, wenn Funktion Predictive Maintenance ausgefallen ist";
CM_ SG_ 2527679670 OTA_FC_Warnung_Update "Funktion: SWaP online    und    SW Update
Warnmeldung, wenn OTA SW-Update/Aktivierung nicht erfolgreich war";

CM_ SG_ 970 PACC02_Automode "Signal zu Steuerung der AUTO-Anzeige im InnoDrive2-Icon";
CM_ SG_ 970 PACC02_Durchschnittsgeschw "Anzeige einer Durchschnittsgeschwindigkeit während des PACChigh / InnoDrive - Betriebs. Dient in Verbindung mit PACC_Durchschnittsverbrauch und PACC_Segelanteil zur Anzeige des Effizienzpotentials.";
CM_ SG_ 970 PACC02_InnoDrive_Texte "Anzeige von Warnmeldungen durch Innodrive";
CM_ SG_ 970 PACC02_naechstes_Event "Anzeige des naechsten Streckenereignisses, welches in der PACC-Regelung eine signifikante Änderung der Zielgeschwindigkeit zur Folge hat (Weiterleitung durch ACC).";
CM_ SG_ 970 PACC02_Offset "Anzeige des vom Fahrer (über Tip hoch/Tip runter am KLSM) eingestellten Geschwindigkeitsoffsets (Weiterleitung durch ACC).";
CM_ SG_ 970 PACC02_Segelanteil "Anzeige eines kumulierten Segelanteils während des PACChigh / InnoDrive - Betriebs. Dient in Verbindung mit PACC_Durchschnittsverbrauch und PACC_Durchschnittsgeschwindigkeit zur Anzeige des Effizienzpotentials.";
CM_ SG_ 970 PACC02_Sollgeschwindigkeit "Wunschgeschwindigkeit von InnoDrive zum ACC";
CM_ SG_ 970 PACC02_Systemstatus "Anzeige des Systemstatus InnoDrive";
CM_ SG_ 970 PACC02_Systemstatus_Anzeige "Signal zur Anzeige des PACC02_Systemstatus, ggf. mit Entprellung der einzelnen Stati";
CM_ SG_ 970 PACC02_Uebernahmeaufforderung "Hinweis an den Fahrer, dass PACC nicht mehr regelt und er die Laengsführung wieder uebernehmen muss (Weiterleitung durch ACC)";
CM_ SG_ 970 PACC02_Vorausschaugeschw "Anzeige der durch PACC in Kürze eingeregelten Zielgeschwindigkeit für den Fahrer.";

CM_ SG_ 2463978731 PACC02_Event_aktiv "Kennzeichnung eines aktiven oder inaktiven Vorausschauevents";
CM_ SG_ 2463978731 PACC02_Geschw_Vorausschau "Zeigt dem KBI an, ob eine Setzgeschw. aus der Vorausschau kommt, oder der aktuellen Setzgesch. entspricht";
CM_ SG_ 2463978731 PACC02_Hinweis_Geschw "Signalisierung der Verfuegbarkeit des Tempolimit Assistenten von zFAS an KBI/LQRK";
CM_ SG_ 2463978731 PACC02_Offset_aktiv "Signalisierung der Verfuegbarkeit von Regelung auf Strassenverlauf im MIB";
CM_ SG_ 2463978731 PACC02_Offset_Anzeige "Signalisierung der PID-Konfiguration im Auslieferungszustand von zFAS an KBI/LQRK";

CM_ SG_ 908 PACC_Automode "Signal zur Anzeige des InnoDrive Automodes";
CM_ SG_ 908 PACC_Durchschnittsgeschw "Anzeige einer Durchschnittsgeschwindigkeit während des PACChigh / InnoDrive - Betriebs. Dient in Verbindung mit PACC_Durchschnittsverbrauch und PACC_Segelanteil zur Anzeige des Effizienzpotentials.";
CM_ SG_ 908 PACC_naechstes_Event "Anzeige des naechsten Streckenereignisses, welches in der PACC-Regelung eine signifikante Änderung der Zielgeschwindigkeit zur Folge hat (Weiterleitung durch ACC).";
CM_ SG_ 908 PACC_Offset "Anzeige des vom Fahrer (über Tip hoch/Tip runter am KLSM) eingestellten Geschwindigkeitsoffsets (Weiterleitung durch ACC).";
CM_ SG_ 908 PACC_Segelanteil "Anzeige eines kumulierten Segelanteils während des PACChigh / InnoDrive - Betriebs. Dient in Verbindung mit PACC_Durchschnittsverbrauch und PACC_Durchschnittsgeschwindigkeit zur Anzeige des Effizienzpotentials.";
CM_ SG_ 908 PACC_Sollgeschwindigkeit "Wunschgeschwindigkeit von InnoDrive zum ACC";
CM_ SG_ 908 PACC_Systemstatus "Anzeige des Systemstatus InnoDrive";
CM_ SG_ 908 PACC_Sytemstatus_Anzeige "Signal zur Anzeige des PACC_Systemstatus, ggf. mit Entprellung der einzelnen Stati.";
CM_ SG_ 908 PACC_Uebernahmeaufforderung "Hinweis an den Fahrer, dass PACC nicht mehr regelt und er die Laengsführung wieder uebernehmen muss (Weiterleitung durch ACC)";
CM_ SG_ 908 PACC_Vorausschaugeschw "Anzeige der durch PACC in Kürze eingeregelten Zielgeschwindigkeit für den Fahrer.";

CM_ SG_ 696 PADM_Warnmeldung_Prio2 "Signal zur Ansteuerung der Prio2 Warnmeldung für das PADM im Kombi.";

CM_ SG_ 872 PDC2_Tonausgabe_Front "In Abhängigkeit der Systemaktivitäten werden unterschiedliche Tonwarnungen ausgegeben. 
Kombi spielt entsprechende WAV.-Datei über internen Audiomaster ab.

0 = kein Ton
1 = Intervallton 1
2 = Intervallton 2
3 = Intervallton 3
4 = Intervallton 4
5";
CM_ SG_ 872 PDC2_Tonausgabe_Heck "In Abhängigkeit der Systemaktivitäten werden unterschiedliche Tonwarnungen ausgegeben. 
Kombi spielt entsprechende WAV.-Datei über internen Audiomaster ab.

0 = kein Ton
1 = Intervallton 1
2 = Intervallton 2
3 = Intervallton 3
4 = Intervallton 4
5";
CM_ SG_ 872 PH2_Abschaltursache "Abschaltursache bleibt bis zur nächsten Aktivierung bzw. bis KL15 aus gesetzt
Im Fehlerfall (blinkende LED) wird '7' gesendet obwohl das System noch aktiv ist, bei 'geheiltem' Fehler wird sofort wieder der Zustand '0' gesendet";
CM_ SG_ 872 PH2_Anf_Audioabsenkung "Es gibt zwei unterschiedliche Nachlauftimer für dieses Bit:
1. normale Funktion
2. Demotonausgabe";
CM_ SG_ 872 PH2_Anf_Verdeck "Anforderung an ein Verdeck-System, die vom Fahrer angeforderte Öffnung/Schließung zu verhindern";
CM_ SG_ 872 PH2_defekt "Zeigt an das sich die Parkhilfe im Fehlerzustand befindet. Signal bleibt bis zur nächsten 'Gut-Aktivierung' gesetzt.
Spezialfall: Sensordefekt hinten bei Anhängerbetrieb. Anhänger wird abgesteckt Fehler wird gesetzt. Fehlerfall bleibt bis Behebung des De";
CM_ SG_ 872 PH2_Display_Kundenwunsch "Anzeige der bei Aktivierung verwendeten Parameter bzgl. Kundenwunsch Displayanziege. Änderungen werden erst bei erneuter Aktivierung aktualisiert.";
CM_ SG_ 872 PH2_Frequenz_hinten "Uebertragung der aktuell im APS Steuergeraet gespeicherten Werte fuer Tongeber Frequenz hinten
Anzeige der aktuell verwendeten Parameter (nicht zwingend die abgespeicherten - da Werte erst 2s nach der letzten Änderung gespeichert werden!)";
CM_ SG_ 872 PH2_Frequenz_vorn "Uebertragung der aktuell im APS Steuergeraet gespeicherten Werte fuer Tongeber Frequenz vorne
Anzeige der aktuell verwendeten Parameter (nicht zwingend die abgespeicherten - da Werte erst 2s nach der letzten Änderung gespeichert werden!)";
CM_ SG_ 872 PH2_gestoert "Eine Störung ist aufgetreten, der die Parkhilfe in einen 'gestört-Zustand' versetzt, z.B. massiver Fremdultraschall, Vereisung, Schnee.Derzeit nur für Störschall benutzt, da keinerlei andere Erkennung implementiert.";
CM_ SG_ 872 PH2_Lautstaerke_hinten "Uebertragung der aktuell im APS Steuergeraet gespeicherten Werte fuer Tongeber Lautstaerke hinten
Anzeige der aktuell verwendeten Parameter (nicht zwingend die abgespeicherten - da Werte erst 2s nach der letzten Änderung gespeichert werden!)";
CM_ SG_ 872 PH2_Lautstaerke_vorn "Uebertragung der aktuell im APS Steuergeraet gespeicherten Werte fuer Tongeber Lautstaerke vorn.
Anzeige der aktuell verwendeten Parameter (nicht zwingend die abgespeicherten - da Werte erst 2s nach der letzten Änderung gespeichert werden!)";
CM_ SG_ 872 PH2_nachtr_Stopp_An "Dieses Signal dient dem Motor als Trigger, dass ein nachträglicher Motorstopp eingeleitet werden kann, wenn es die Bedingungen des StSt Koordinators dies zulassen. ";
CM_ SG_ 872 PH2_Opt_Anz_H_Hindernis "mindestens 1 Segment wird für den hinteren Detekionsbereich dargestellt, also ein Hindernis ist im Detektionsbereich. Funktion nur bei gesicherter Rückmeldung vom ASG gegeben.";
CM_ SG_ 872 PH2_Opt_Anz_V_Hindernis "mindestens 1 Segment wird für den vorderen Detekionsbereich dargestellt, also ein Hindernis ist im Detektionsbereich. Funktion nur bei gesicherter Rückmeldung vom ASG gegeben.";
CM_ SG_ 872 PH2_Opt_Anzeige_H_ein "OPS hinten ist im Display aktiv bzw. Anzeigemodule hinten sind eingeschaltet. Funktion nur bei gesicherter Rückmeldung vom ASG gegeben.";
CM_ SG_ 872 PH2_Opt_Anzeige_V_ein "OPS vorne ist im Display aktiv bzw. Anzeigemodule vorne sind eingeschaltet. Funktion nur bei gesicherter Rückmeldung vom ASG gegeben.";
CM_ SG_ 872 PH2_StartStopp_Info "Stopp-Freigabe und Start-Anforderung an den Start-Stopp-Koordinator";
CM_ SG_ 872 PH2_Stoermeldung "Meldung einer Störung der PDC an das Kombi";
CM_ SG_ 872 PH2_Systemzustand "Aktivierungsursache wird für die Dauer der Aktivierung gemeldet.
Im Fehlerfall bei atkviem System wechselt das Signal auf '7'
(siehe auch 'Abschaltursache')";
CM_ SG_ 872 PH2_Taster "Taster Status (für RVC/TopView)";
CM_ SG_ 872 PH2_Tongeber_H_aktiv "Rohsignal für 'Tongeber hinten wird angesteuert', verlängerbar mit Nachlauftimer.
Bit wird nicht während des Stellgliedtests angesteuert.";
CM_ SG_ 872 PH2_Tongeber_H_verfuegbar "Tongeber ist für die Tonausgabe für externe Funktionen verfügbar. PDC ist aktiv und Tongeber ist nicht gestört.";
CM_ SG_ 872 PH2_Tongeber_mute "Die Akustikausgabe des Systems wird unterdrückt, z.B. Wählhebel in 'P', Parlbremse geschlossen (8-Kanal-System)";
CM_ SG_ 872 PH2_Tongeber_V_aktiv "Rohsignal für 'Tongeber vorne wird angesteuert', verlängerbar mit Nachlauftimer.
Bit wird nicht während des Stellgliedtests angesteuert.";
CM_ SG_ 872 PH2_Visualisierung "Signal zeigt den Partnersteuergeräten RearView/TopView/ARA/... den aktuellen Status der Visualisierung des OPS. Die Partnersteuergeräte können dadurch auch ihre Aufschaltung an dieses Signal koppeln.";

CM_ SG_ 2463978617 PH2_Aufschaltursache "Der Grund für die Aufschaltung der Einparkhilfe wird angegeben, z.B. bei der Aktivierung der Einparkhilfe durch eine andere Funktion, wird diese Funktion als Aktivierungsursache für die Dauer der Aktivierung gemeldet.
Das Signal wird den PH_Systemzustand";
CM_ SG_ 2463978617 PH2_Verschmutzungsmeldung "Meldung einer Verschmutzung/Vereisung der PDC an das Kombi";
CM_ SG_ 2463978617 PH2_WAH_Meldung "Steuert die HMI-Meldungen im Kombi für den Wiederanfahrhinweis";

CM_ SG_ 1175 PDC_Tonausgabe_Front "In Abhängigkeit der Systemaktivitäten werden unterschiedliche Tonwarnungen ausgegeben. 
Kombi spielt entsprechende WAV.-Datei über internen Audiomaster ab.

0 = kein Ton
1 = Intervallton 1
2 = Intervallton 2
3 = Intervallton 3
4 = Intervallton 4
5";
CM_ SG_ 1175 PDC_Tonausgabe_Heck "In Abhängigkeit der Systemaktivitäten werden unterschiedliche Tonwarnungen ausgegeben. 
Kombi spielt entsprechende WAV.-Datei über internen Audiomaster ab.

0 = kein Ton
1 = Intervallton 1
2 = Intervallton 2
3 = Intervallton 3
4 = Intervallton 4
5";
CM_ SG_ 1175 PH_Abschaltursache "Abschaltursache bleibt bis zur nächsten Aktivierung bzw. bis KL15 aus gesetzt
Im Fehlerfall (blinkende LED) wird '7' gesendet obwohl das System noch aktiv ist, bei 'geheiltem' Fehler wird sofort wieder der Zustand '0' gesendet";
CM_ SG_ 1175 PH_Anf_Audioabsenkung "Es gibt zwei unterschiedliche Nachlauftimer für dieses Bit:
1. normale Funktion
2. Demotonausgabe";
CM_ SG_ 1175 PH_Anf_Verdeck "Anforderung an ein Verdeck-System, die vom Fahrer angeforderte Öffnung/Schließung zu verhindern";
CM_ SG_ 1175 PH_defekt "Zeigt an das sich die Parkhilfe im Fehlerzustand befindet. Signal bleibt bis zur nächsten 'Gut-Aktivierung' gesetzt.
Spezialfall: Sensordefekt hinten bei Anhängerbetrieb. Anhänger wird abgesteckt Fehler wird gesetzt. Fehlerfall bleibt bis Behebung des De";
CM_ SG_ 1175 PH_Display_Kundenwunsch "Anzeige der bei Aktivierung verwendeten Parameter bzgl. Kundenwunsch Displayanziege. Änderungen werden erst bei erneuter Aktivierung aktualisiert.";
CM_ SG_ 1175 PH_Frequenz_hinten "Uebertragung der aktuell im APS Steuergeraet gespeicherten Werte fuer Tongeber Frequenz hinten
Anzeige der aktuell verwendeten Parameter (nicht zwingend die abgespeicherten - da Werte erst 2s nach der letzten Änderung gespeichert werden!)";
CM_ SG_ 1175 PH_Frequenz_vorn "Uebertragung der aktuell im APS Steuergeraet gespeicherten Werte fuer Tongeber Frequenz vorne
Anzeige der aktuell verwendeten Parameter (nicht zwingend die abgespeicherten - da Werte erst 2s nach der letzten Änderung gespeichert werden!)";
CM_ SG_ 1175 PH_gestoert "Eine Störung ist aufgetreten, der die Parkhilfe in einen 'gestört-Zustand' versetzt, z.B. massiver Fremdultraschall, Vereisung, Schnee.Derzeit nur für Störschall benutzt, da keinerlei andere Erkennung implementiert.";
CM_ SG_ 1175 PH_Lautstaerke_hinten "Uebertragung der aktuell im APS Steuergeraet gespeicherten Werte fuer Tongeber Lautstaerke hinten
Anzeige der aktuell verwendeten Parameter (nicht zwingend die abgespeicherten - da Werte erst 2s nach der letzten Änderung gespeichert werden!)";
CM_ SG_ 1175 PH_Lautstaerke_vorn "Uebertragung der aktuell im APS Steuergeraet gespeicherten Werte fuer Tongeber Lautstaerke vorn.
Anzeige der aktuell verwendeten Parameter (nicht zwingend die abgespeicherten - da Werte erst 2s nach der letzten Änderung gespeichert werden!)";
CM_ SG_ 1175 PH_nachtr_Stopp_Anf "Dieses Signal dient dem Motor als Trigger, dass ein nachträglicher Motorstopp eingeleitet werden kann, wenn es die Bedingungen des StSt Koordinators dies zulassen. ";
CM_ SG_ 1175 PH_Opt_Anz_H_Hindernis "mindestens 1 Segment wird für den hinteren Detekionsbereich dargestellt, also ein Hindernis ist im Detektionsbereich. Funktion nur bei gesicherter Rückmeldung vom ASG gegeben.";
CM_ SG_ 1175 PH_Opt_Anz_V_Hindernis "mindestens 1 Segment wird für den vorderen Detekionsbereich dargestellt, also ein Hindernis ist im Detektionsbereich. Funktion nur bei gesicherter Rückmeldung vom ASG gegeben.";
CM_ SG_ 1175 PH_Opt_Anzeige_H_ein "OPS hinten ist im Display aktiv bzw. Anzeigemodule hinten sind eingeschaltet. Funktion nur bei gesicherter Rückmeldung vom ASG gegeben.";
CM_ SG_ 1175 PH_Opt_Anzeige_V_ein "OPS vorne ist im Display aktiv bzw. Anzeigemodule vorne sind eingeschaltet. Funktion nur bei gesicherter Rückmeldung vom ASG gegeben.";
CM_ SG_ 1175 PH_StartStopp_Info "Stopp-Freigabe und Start-Anforderung an den Start-Stopp-Koordinator";
CM_ SG_ 1175 PH_Stoermeldung "Meldung einer Störung der PDC an das Kombi";
CM_ SG_ 1175 PH_Systemzustand "Aktivierungsursache wird für die Dauer der Aktivierung gemeldet.
Im Fehlerfall bei atkviem System wechselt das Signal auf '7'
(siehe auch 'Abschaltursache')";
CM_ SG_ 1175 PH_Taster "Taster Status (für RVC/TopView)";
CM_ SG_ 1175 PH_Tongeber_H_aktiv "Rohsignal für 'Tongeber hinten wird angesteuert', verlängerbar mit Nachlauftimer.
Bit wird nicht während des Stellgliedtests angesteuert.";
CM_ SG_ 1175 PH_Tongeber_H_verfuegbar "Tongeber ist für die Tonausgabe für externe Funktionen verfügbar. PDC ist aktiv und Tongeber ist nicht gestört.";
CM_ SG_ 1175 PH_Tongeber_mute "Die Akustikausgabe des Systems wird unterdrückt, z.B. Wählhebel in 'P', Parlbremse geschlossen (8-Kanal-System)";
CM_ SG_ 1175 PH_Tongeber_V_aktiv "Rohsignal für 'Tongeber vorne wird angesteuert', verlängerbar mit Nachlauftimer.
Bit wird nicht während des Stellgliedtests angesteuert.";
CM_ SG_ 1175 PH_Visualisierung "Signal zeigt den Partnersteuergeräten RearView/TopView/ARA/... den aktuellen Status der Visualisierung des OPS. Die Partnersteuergeräte können dadurch auch ihre Aufschaltung an dieses Signal koppeln.";
CM_ SG_ 1175 PLA_Anf_Aufschaltung_RVC "Anforderung der Aufschaltung RVC durch PLA";
BA_DEF_REL_ BU_SG_REL_  "GenSigTimeoutTime" INT 0 65535;
BA_DEF_ BO_  "DiagRequest" ENUM "No", "Yes";
BA_DEF_ BO_  "DiagResponse" ENUM "No", "Yes";
BA_DEF_ BO_  "DiagState" ENUM "No", "Yes";
BA_DEF_ BO_  "GenMsgChkConstant" HEX 0 4095;
BA_DEF_ BO_  "GenMsgCycleTime" INT 0 65535;
BA_DEF_ BO_  "GenMsgCycleTimeFast" INT 0 65535;
BA_DEF_ BO_  "GenMsgDelayTime" INT 0 100000;
BA_DEF_ BO_  "GenMsgILSupport" ENUM "No", "Yes";
BA_DEF_ BO_  "GenMsgNrOfRepetition" INT 0 100;
BA_DEF_ BO_  "GenMsgPDUConstants" STRING;
BA_DEF_ BO_  "GenMsgSendType" ENUM "Cyclic", "not_used", "not_used", "not_used", "not_used", "not_used", "not_used", "IfActive", "NoMsgSendType";
BA_DEF_ BO_  "GenMsgStartDelayTime" INT 0 100000;
BA_DEF_ BO_  "NmMessage" ENUM "No", "Yes";
BA_DEF_ BO_  "NmhMessage" ENUM "No", "Yes";
BA_DEF_ BO_  "MsgType" ENUM "Application", "NM ", "NMH", "TP2.0", "ISO-TP ", "BAP", "EID", "KS", "XCP_PRE_CONFIGURED", "XCP_RUNTIME_CONFIGURED";
BA_DEF_ BO_  "VAGTP20_API" HEX 0 255;
BA_DEF_ BO_  "VAGTP20_DynConnection" ENUM "No", "Yes";
BA_DEF_ BO_  "VAGTP20_DynSetup" ENUM "No", "Yes";
BA_DEF_ BO_  "VAGTP20_StatConnection" ENUM "No", "Yes";
BA_DEF_ SG_  "GenSigActiveRepetitions" INT -2147483648 2147483647;
BA_DEF_ SG_  "GenSigInactiveValue" INT -2147483648 2147483647;
BA_DEF_ SG_  "GenSigSendType" ENUM "Cyclic", "OnWrite", "OnWriteWithRepetition", "OnChange", "OnChangeWithRepetition", "IfActive", "IfActiveWithRepetition", "NoSigSendType", "OnChangeAndIfActive", "OnChangeAndIfActiveWithRepetition";
BA_DEF_ SG_  "GenSigStartValue" INT -2147483648 2147483647;
BA_DEF_ SG_  "NWM-WakeupAllowed" ENUM "No", "Yes";
BA_DEF_ SG_  "GenSigFuncType" ENUM "NoFunction", "MsgCounter", "CRC-8", "XOR", "XOR-2", "DatedBit", "SW-Kl15", "CHK", "Constant", "Protocol", "CRC-8-SAE_J1850", "CRC-32", "DataLength", "DataID", "MsgCounter16", "SOK-Signatur", "Cluster";
BA_DEF_ SG_  "GenSigSwitchedByIgnition" ENUM "No", "Yes";
BA_DEF_ SG_  "Fehlerwert" HEX 0 2147483647;
BA_DEF_ SG_  "GenSigMissingSourceValue" HEX 0 2147483647;
BA_DEF_DEF_REL_  "GenSigTimeoutTime" 0;
BA_DEF_DEF_  "DiagRequest" "No";
BA_DEF_DEF_  "DiagResponse" "No";
BA_DEF_DEF_  "DiagState" "No";
BA_DEF_DEF_  "GenMsgChkConstant" 0;
BA_DEF_DEF_  "GenMsgCycleTime" 0;
BA_DEF_DEF_  "GenMsgCycleTimeFast" 0;
BA_DEF_DEF_  "GenMsgDelayTime" 0;
BA_DEF_DEF_  "GenMsgILSupport" "No";
BA_DEF_DEF_  "GenMsgNrOfRepetition" 0;
BA_DEF_DEF_  "GenMsgPDUConstants" "";
BA_DEF_DEF_  "GenMsgSendType" "NoMsgSendType";
BA_DEF_DEF_  "GenMsgStartDelayTime" 0;
BA_DEF_DEF_  "NmMessage" "No";
BA_DEF_DEF_  "NmhMessage" "No";
BA_DEF_DEF_  "MsgType" "Application";
BA_DEF_DEF_  "VAGTP20_API" 0;
BA_DEF_DEF_  "VAGTP20_DynConnection" "No";
BA_DEF_DEF_  "VAGTP20_DynSetup" "No";
BA_DEF_DEF_  "VAGTP20_StatConnection" "No";
BA_DEF_DEF_  "GenSigActiveRepetitions" 0;
BA_DEF_DEF_  "GenSigInactiveValue" 0;
BA_DEF_DEF_  "GenSigSendType" "NoSigSendType";
BA_DEF_DEF_  "GenSigStartValue" 0;
BA_DEF_DEF_  "NWM-WakeupAllowed" "No";
BA_DEF_DEF_  "GenSigFuncType" "NoFunction";
BA_DEF_DEF_  "GenSigSwitchedByIgnition" "Yes";
BA_DEF_DEF_  "Fehlerwert" 0;
BA_DEF_DEF_  "GenSigMissingSourceValue" 0;
BA_ "GenMsgCycleTime" BO_ 1155 320;
BA_ "GenMsgDelayTime" BO_ 1155 40;
BA_ "GenMsgILSupport" BO_ 1155 1;
BA_ "GenMsgSendType" BO_ 1155 0;
BA_ "GenMsgCycleTime" BO_ 878 80;
BA_ "GenMsgILSupport" BO_ 878 1;
BA_ "GenMsgSendType" BO_ 878 0;
BA_ "GenMsgCycleTime" BO_ 2527679823 160;
BA_ "GenMsgILSupport" BO_ 2527679823 1;
BA_ "GenMsgSendType" BO_ 2527679823 0;
BA_ "GenMsgDelayTime" BO_ 2589284146 320;
BA_ "GenMsgILSupport" BO_ 2589284146 1;
BA_ "GenMsgDelayTime" BO_ 2589284147 320;
BA_ "GenMsgILSupport" BO_ 2589284147 1;
BA_ "GenMsgDelayTime" BO_ 2589284144 320;
BA_ "GenMsgILSupport" BO_ 2589284144 1;
BA_ "GenMsgDelayTime" BO_ 2589284145 320;
BA_ "GenMsgILSupport" BO_ 2589284145 1;
BA_ "GenMsgCycleTime" BO_ 688 40;
BA_ "GenMsgILSupport" BO_ 688 1;
BA_ "GenMsgSendType" BO_ 688 0;
BA_ "GenMsgCycleTime" BO_ 689 40;
BA_ "GenMsgILSupport" BO_ 689 1;
BA_ "GenMsgSendType" BO_ 689 0;
BA_ "GenMsgCycleTime" BO_ 1284 100;
BA_ "GenMsgDelayTime" BO_ 1284 10;
BA_ "GenMsgILSupport" BO_ 1284 1;
BA_ "GenMsgPDUConstants" BO_ 1284 "0x03,0x63,0x3e,0x04,0xf9,0xb4,0x4f,0x32,0x25,0x56,0x1e,0xc1,0x83,0xfa,0x31,0x97";
BA_ "GenMsgSendType" BO_ 1284 0;
BA_ "GenMsgStartDelayTime" BO_ 1284 50;
BA_ "GenMsgCycleTime" BO_ 1157 200;
BA_ "GenMsgILSupport" BO_ 1157 1;
BA_ "GenMsgSendType" BO_ 1157 0;
BA_ "GenMsgCycleTime" BO_ 2527679512 200;
BA_ "GenMsgILSupport" BO_ 2527679512 1;
BA_ "GenMsgSendType" BO_ 2527679512 0;
BA_ "GenMsgStartDelayTime" BO_ 2527679512 60;
BA_ "GenMsgCycleTime" BO_ 1696 200;
BA_ "GenMsgDelayTime" BO_ 1696 20;
BA_ "GenMsgILSupport" BO_ 1696 1;
BA_ "GenMsgSendType" BO_ 1696 0;
BA_ "GenMsgCycleTime" BO_ 2600468496 200;
BA_ "GenMsgCycleTimeFast" BO_ 2600468496 10;
BA_ "GenMsgNrOfRepetition" BO_ 2600468496 3;
BA_ "GenMsgSendType" BO_ 2600468496 7;
BA_ "NmhMessage" BO_ 2600468496 1;
BA_ "MsgType" BO_ 2600468496 2;
BA_ "GenMsgCycleTime" BO_ 2600468507 200;
BA_ "GenMsgCycleTimeFast" BO_ 2600468507 10;
BA_ "GenMsgNrOfRepetition" BO_ 2600468507 3;
BA_ "GenMsgSendType" BO_ 2600468507 7;
BA_ "NmhMessage" BO_ 2600468507 1;
BA_ "MsgType" BO_ 2600468507 2;
BA_ "GenMsgCycleTime" BO_ 2600468500 200;
BA_ "GenMsgCycleTimeFast" BO_ 2600468500 10;
BA_ "GenMsgNrOfRepetition" BO_ 2600468500 3;
BA_ "GenMsgSendType" BO_ 2600468500 7;
BA_ "NmhMessage" BO_ 2600468500 1;
BA_ "MsgType" BO_ 2600468500 2;
BA_ "GenMsgCycleTime" BO_ 2600468563 200;
BA_ "GenMsgCycleTimeFast" BO_ 2600468563 10;
BA_ "GenMsgNrOfRepetition" BO_ 2600468563 3;
BA_ "GenMsgSendType" BO_ 2600468563 7;
BA_ "NmhMessage" BO_ 2600468563 1;
BA_ "MsgType" BO_ 2600468563 2;
BA_ "GenMsgCycleTime" BO_ 1635 100;
BA_ "GenMsgILSupport" BO_ 1635 1;
BA_ "GenMsgPDUConstants" BO_ 1635 "0x7d,0xba,0x97,0x94,0x5a,0x4a,0xeb,0xd4,0x6c,0x28,0x54,0x81,0xc7,0x1c,0x25,0x2a";
BA_ "GenMsgSendType" BO_ 1635 0;
BA_ "GenMsgStartDelayTime" BO_ 1635 10;
BA_ "GenMsgCycleTime" BO_ 2527679508 100;
BA_ "GenMsgDelayTime" BO_ 2527679508 80;
BA_ "GenMsgILSupport" BO_ 2527679508 1;
BA_ "GenMsgPDUConstants" BO_ 2527679508 "0xa3,0xed,0x65,0xcf,0xc5,0x26,0x54,0x1a,0x99,0x3c,0x01,0x84,0xf4,0x46,0x9c,0x28";
BA_ "GenMsgSendType" BO_ 2527679508 0;
BA_ "GenMsgStartDelayTime" BO_ 2527679508 10;
BA_ "GenMsgCycleTime" BO_ 913 500;
BA_ "GenMsgILSupport" BO_ 913 1;
BA_ "GenMsgSendType" BO_ 913 0;
BA_ "DiagState" BO_ 2549940736 1;
BA_ "MsgType" BO_ 2549940736 4;
BA_ "DiagRequest" BO_ 2549875227 1;
BA_ "MsgType" BO_ 2549875227 4;
BA_ "DiagResponse" BO_ 2550006299 1;
BA_ "MsgType" BO_ 2550006299 4;
BA_ "DiagRequest" BO_ 2549875220 1;
BA_ "MsgType" BO_ 2549875220 4;
BA_ "DiagResponse" BO_ 2550006292 1;
BA_ "MsgType" BO_ 2550006292 4;
BA_ "DiagRequest" BO_ 2549875283 1;
BA_ "MsgType" BO_ 2549875283 4;
BA_ "DiagResponse" BO_ 2550006355 1;
BA_ "MsgType" BO_ 2550006355 4;
BA_ "GenMsgCycleTime" BO_ 2589283656 960;
BA_ "GenMsgDelayTime" BO_ 2589283656 160;
BA_ "GenMsgILSupport" BO_ 2589283656 1;
BA_ "GenMsgPDUConstants" BO_ 2589283656 "0xee,0xcc,0x2f,0x27,0x93,0x0c,0x45,0x97,0x87,0x2e,0xec,0x3b,0xd3,0x35,0xcb,0x4a";
BA_ "GenMsgSendType" BO_ 2589283656 0;
BA_ "GenMsgStartDelayTime" BO_ 2589283656 160;
BA_ "GenMsgCycleTime" BO_ 2527679670 1000;
BA_ "GenMsgCycleTimeFast" BO_ 2527679670 200;
BA_ "GenMsgDelayTime" BO_ 2527679670 100;
BA_ "GenMsgILSupport" BO_ 2527679670 1;
BA_ "GenMsgNrOfRepetition" BO_ 2527679670 5;
BA_ "GenMsgSendType" BO_ 2527679670 0;
BA_ "GenMsgCycleTime" BO_ 970 100;
BA_ "GenMsgILSupport" BO_ 970 1;
BA_ "GenMsgSendType" BO_ 970 0;
BA_ "GenMsgCycleTime" BO_ 2463978731 100;
BA_ "GenMsgILSupport" BO_ 2463978731 1;
BA_ "GenMsgSendType" BO_ 2463978731 0;
BA_ "GenMsgCycleTime" BO_ 908 100;
BA_ "GenMsgILSupport" BO_ 908 1;
BA_ "GenMsgSendType" BO_ 908 0;
BA_ "GenMsgCycleTime" BO_ 696 160;
BA_ "GenMsgILSupport" BO_ 696 1;
BA_ "GenMsgSendType" BO_ 696 0;
BA_ "GenMsgCycleTime" BO_ 872 100;
BA_ "GenMsgDelayTime" BO_ 872 40;
BA_ "GenMsgILSupport" BO_ 872 1;
BA_ "GenMsgSendType" BO_ 872 0;
BA_ "GenMsgCycleTime" BO_ 2463978617 500;
BA_ "GenMsgDelayTime" BO_ 2463978617 40;
BA_ "GenMsgILSupport" BO_ 2463978617 1;
BA_ "GenMsgSendType" BO_ 2463978617 0;
BA_ "GenMsgCycleTime" BO_ 1175 100;
BA_ "GenMsgDelayTime" BO_ 1175 50;
BA_ "GenMsgILSupport" BO_ 1175 1;
BA_ "GenMsgSendType" BO_ 1175 0;
BA_ "GenSigSendType" SG_ 1155 MO_Powermeter_Charge_Grenze 3;
BA_ "GenSigStartValue" SG_ 1155 MO_Powermeter_Charge_Grenze 1022;
BA_ "GenSigSwitchedByIgnition" SG_ 1155 MO_Powermeter_Charge_Grenze 0;
BA_ "Fehlerwert" SG_ 1155 MO_Powermeter_Charge_Grenze 1023;
BA_ "GenSigSendType" SG_ 1155 Mo_Powermeter_Grenze 3;
BA_ "GenSigStartValue" SG_ 1155 Mo_Powermeter_Grenze 4093;
BA_ "GenSigSwitchedByIgnition" SG_ 1155 Mo_Powermeter_Grenze 0;
BA_ "GenSigSendType" SG_ 1155 MO_Powermeter_Grenze_strategisch 3;
BA_ "GenSigStartValue" SG_ 1155 MO_Powermeter_Grenze_strategisch 4094;
BA_ "GenSigSwitchedByIgnition" SG_ 1155 MO_Powermeter_Grenze_strategisch 0;
BA_ "Fehlerwert" SG_ 1155 MO_Powermeter_Grenze_strategisch 4095;
BA_ "GenSigSendType" SG_ 1155 MO_Powermeter_Inszenierung_aktiv 3;
BA_ "GenSigSwitchedByIgnition" SG_ 1155 MO_Powermeter_Inszenierung_aktiv 0;
BA_ "GenSigSendType" SG_ 1155 MO_Powermeter_obere_E_Grenze 3;
BA_ "GenSigStartValue" SG_ 1155 MO_Powermeter_obere_E_Grenze 4094;
BA_ "GenSigSwitchedByIgnition" SG_ 1155 MO_Powermeter_obere_E_Grenze 0;
BA_ "Fehlerwert" SG_ 1155 MO_Powermeter_obere_E_Grenze 4095;
BA_ "GenSigSendType" SG_ 1155 MO_Powermeter_untere_E_Grenze 3;
BA_ "GenSigStartValue" SG_ 1155 MO_Powermeter_untere_E_Grenze 4094;
BA_ "GenSigSwitchedByIgnition" SG_ 1155 MO_Powermeter_untere_E_Grenze 0;
BA_ "Fehlerwert" SG_ 1155 MO_Powermeter_untere_E_Grenze 4095;
BA_ "GenSigSendType" SG_ 1155 MO_Text_Aktivierung_Antrieb 3;
BA_ "GenSigStartValue" SG_ 1155 MO_Text_Aktivierung_Antrieb 15;
BA_ "GenSigSwitchedByIgnition" SG_ 1155 MO_Text_Aktivierung_Antrieb 0;
BA_ "GenSigSendType" SG_ 878 RML_Status_Anzeige_Range 0;
BA_ "GenSigSwitchedByIgnition" SG_ 878 RML_Status_Anzeige_Range 0;
BA_ "GenSigSendType" SG_ 878 RML_vMax_Range 0;
BA_ "GenSigStartValue" SG_ 878 RML_vMax_Range 1023;
BA_ "GenSigSwitchedByIgnition" SG_ 878 RML_vMax_Range 0;
BA_ "GenSigSendType" SG_ 2527679823 MO_WI_FlgInfoTmpLvlVolWa 0;
BA_ "GenSigSwitchedByIgnition" SG_ 2527679823 MO_WI_FlgInfoTmpLvlVolWa 0;
BA_ "GenSigSendType" SG_ 2527679823 MO_WI_NVEM_HtrPwrReq 0;
BA_ "GenSigSwitchedByIgnition" SG_ 2527679823 MO_WI_NVEM_HtrPwrReq 0;
BA_ "GenSigSendType" SG_ 2527679823 MO_WI_StWarnVolWa 0;
BA_ "GenSigSwitchedByIgnition" SG_ 2527679823 MO_WI_StWarnVolWa 0;
BA_ "GenSigStartValue" SG_ 2589284146 MRR_HL_P_Text_ASCII_01 45;
BA_ "GenSigSwitchedByIgnition" SG_ 2589284146 MRR_HL_P_Text_ASCII_01 0;
BA_ "GenSigStartValue" SG_ 2589284146 MRR_HL_P_Text_ASCII_02 45;
BA_ "GenSigSwitchedByIgnition" SG_ 2589284146 MRR_HL_P_Text_ASCII_02 0;
BA_ "GenSigStartValue" SG_ 2589284146 MRR_HL_P_Text_ASCII_03 45;
BA_ "GenSigSwitchedByIgnition" SG_ 2589284146 MRR_HL_P_Text_ASCII_03 0;
BA_ "GenSigStartValue" SG_ 2589284146 MRR_HL_P_Text_ASCII_04 45;
BA_ "GenSigSwitchedByIgnition" SG_ 2589284146 MRR_HL_P_Text_ASCII_04 0;
BA_ "GenSigStartValue" SG_ 2589284146 MRR_HL_P_Text_ASCII_05 45;
BA_ "GenSigSwitchedByIgnition" SG_ 2589284146 MRR_HL_P_Text_ASCII_05 0;
BA_ "GenSigStartValue" SG_ 2589284146 MRR_HL_P_Text_ASCII_06 45;
BA_ "GenSigSwitchedByIgnition" SG_ 2589284146 MRR_HL_P_Text_ASCII_06 0;
BA_ "GenSigStartValue" SG_ 2589284146 MRR_HL_P_Text_ASCII_07 45;
BA_ "GenSigSwitchedByIgnition" SG_ 2589284146 MRR_HL_P_Text_ASCII_07 0;
BA_ "GenSigStartValue" SG_ 2589284146 MRR_HL_P_Text_ASCII_08 45;
BA_ "GenSigSwitchedByIgnition" SG_ 2589284146 MRR_HL_P_Text_ASCII_08 0;
BA_ "GenSigStartValue" SG_ 2589284146 MRR_HL_P_Text_ASCII_09 45;
BA_ "GenSigSwitchedByIgnition" SG_ 2589284146 MRR_HL_P_Text_ASCII_09 0;
BA_ "GenSigStartValue" SG_ 2589284146 MRR_HL_P_Text_ASCII_10 45;
BA_ "GenSigSwitchedByIgnition" SG_ 2589284146 MRR_HL_P_Text_ASCII_10 0;
BA_ "GenSigStartValue" SG_ 2589284146 MRR_HL_P_Text_ASCII_11 45;
BA_ "GenSigSwitchedByIgnition" SG_ 2589284146 MRR_HL_P_Text_ASCII_11 0;
BA_ "GenSigStartValue" SG_ 2589284146 MRR_HL_P_Text_ASCII_12 45;
BA_ "GenSigSwitchedByIgnition" SG_ 2589284146 MRR_HL_P_Text_ASCII_12 0;
BA_ "GenSigStartValue" SG_ 2589284146 MRR_HL_P_Text_ASCII_13 45;
BA_ "GenSigSwitchedByIgnition" SG_ 2589284146 MRR_HL_P_Text_ASCII_13 0;
BA_ "GenSigStartValue" SG_ 2589284146 MRR_HL_P_Text_ASCII_14 45;
BA_ "GenSigSwitchedByIgnition" SG_ 2589284146 MRR_HL_P_Text_ASCII_14 0;
BA_ "GenSigStartValue" SG_ 2589284146 MRR_HL_P_Text_ASCII_15 45;
BA_ "GenSigSwitchedByIgnition" SG_ 2589284146 MRR_HL_P_Text_ASCII_15 0;
BA_ "GenSigStartValue" SG_ 2589284146 MRR_HL_P_Text_ASCII_16 45;
BA_ "GenSigSwitchedByIgnition" SG_ 2589284146 MRR_HL_P_Text_ASCII_16 0;
BA_ "GenSigStartValue" SG_ 2589284146 MRR_HL_P_Text_ASCII_17 45;
BA_ "GenSigSwitchedByIgnition" SG_ 2589284146 MRR_HL_P_Text_ASCII_17 0;
BA_ "GenSigStartValue" SG_ 2589284146 MRR_HL_P_Text_ASCII_18 45;
BA_ "GenSigSwitchedByIgnition" SG_ 2589284146 MRR_HL_P_Text_ASCII_18 0;
BA_ "GenSigStartValue" SG_ 2589284146 MRR_HL_P_Text_ASCII_19 45;
BA_ "GenSigSwitchedByIgnition" SG_ 2589284146 MRR_HL_P_Text_ASCII_19 0;
BA_ "GenSigStartValue" SG_ 2589284146 MRR_HL_P_Text_ASCII_20 45;
BA_ "GenSigSwitchedByIgnition" SG_ 2589284146 MRR_HL_P_Text_ASCII_20 0;
BA_ "GenSigStartValue" SG_ 2589284146 MRR_HL_P_Text_ASCII_21 45;
BA_ "GenSigSwitchedByIgnition" SG_ 2589284146 MRR_HL_P_Text_ASCII_21 0;
BA_ "GenSigSendType" SG_ 2589284146 MRR_HL_P_Text_Mux 1;
BA_ "GenSigSwitchedByIgnition" SG_ 2589284146 MRR_HL_P_Text_Mux 0;
BA_ "GenSigStartValue" SG_ 2589284147 MRR_HR_P_Text_ASCII_01 45;
BA_ "GenSigSwitchedByIgnition" SG_ 2589284147 MRR_HR_P_Text_ASCII_01 0;
BA_ "GenSigStartValue" SG_ 2589284147 MRR_HR_P_Text_ASCII_02 45;
BA_ "GenSigSwitchedByIgnition" SG_ 2589284147 MRR_HR_P_Text_ASCII_02 0;
BA_ "GenSigStartValue" SG_ 2589284147 MRR_HR_P_Text_ASCII_03 45;
BA_ "GenSigSwitchedByIgnition" SG_ 2589284147 MRR_HR_P_Text_ASCII_03 0;
BA_ "GenSigStartValue" SG_ 2589284147 MRR_HR_P_Text_ASCII_04 45;
BA_ "GenSigSwitchedByIgnition" SG_ 2589284147 MRR_HR_P_Text_ASCII_04 0;
BA_ "GenSigStartValue" SG_ 2589284147 MRR_HR_P_Text_ASCII_05 45;
BA_ "GenSigSwitchedByIgnition" SG_ 2589284147 MRR_HR_P_Text_ASCII_05 0;
BA_ "GenSigStartValue" SG_ 2589284147 MRR_HR_P_Text_ASCII_06 45;
BA_ "GenSigSwitchedByIgnition" SG_ 2589284147 MRR_HR_P_Text_ASCII_06 0;
BA_ "GenSigStartValue" SG_ 2589284147 MRR_HR_P_Text_ASCII_07 45;
BA_ "GenSigSwitchedByIgnition" SG_ 2589284147 MRR_HR_P_Text_ASCII_07 0;
BA_ "GenSigStartValue" SG_ 2589284147 MRR_HR_P_Text_ASCII_08 45;
BA_ "GenSigSwitchedByIgnition" SG_ 2589284147 MRR_HR_P_Text_ASCII_08 0;
BA_ "GenSigStartValue" SG_ 2589284147 MRR_HR_P_Text_ASCII_09 45;
BA_ "GenSigSwitchedByIgnition" SG_ 2589284147 MRR_HR_P_Text_ASCII_09 0;
BA_ "GenSigStartValue" SG_ 2589284147 MRR_HR_P_Text_ASCII_10 45;
BA_ "GenSigSwitchedByIgnition" SG_ 2589284147 MRR_HR_P_Text_ASCII_10 0;
BA_ "GenSigStartValue" SG_ 2589284147 MRR_HR_P_Text_ASCII_11 45;
BA_ "GenSigSwitchedByIgnition" SG_ 2589284147 MRR_HR_P_Text_ASCII_11 0;
BA_ "GenSigStartValue" SG_ 2589284147 MRR_HR_P_Text_ASCII_12 45;
BA_ "GenSigSwitchedByIgnition" SG_ 2589284147 MRR_HR_P_Text_ASCII_12 0;
BA_ "GenSigStartValue" SG_ 2589284147 MRR_HR_P_Text_ASCII_13 45;
BA_ "GenSigSwitchedByIgnition" SG_ 2589284147 MRR_HR_P_Text_ASCII_13 0;
BA_ "GenSigStartValue" SG_ 2589284147 MRR_HR_P_Text_ASCII_14 45;
BA_ "GenSigSwitchedByIgnition" SG_ 2589284147 MRR_HR_P_Text_ASCII_14 0;
BA_ "GenSigStartValue" SG_ 2589284147 MRR_HR_P_Text_ASCII_15 45;
BA_ "GenSigSwitchedByIgnition" SG_ 2589284147 MRR_HR_P_Text_ASCII_15 0;
BA_ "GenSigStartValue" SG_ 2589284147 MRR_HR_P_Text_ASCII_16 45;
BA_ "GenSigSwitchedByIgnition" SG_ 2589284147 MRR_HR_P_Text_ASCII_16 0;
BA_ "GenSigStartValue" SG_ 2589284147 MRR_HR_P_Text_ASCII_17 45;
BA_ "GenSigSwitchedByIgnition" SG_ 2589284147 MRR_HR_P_Text_ASCII_17 0;
BA_ "GenSigStartValue" SG_ 2589284147 MRR_HR_P_Text_ASCII_18 45;
BA_ "GenSigSwitchedByIgnition" SG_ 2589284147 MRR_HR_P_Text_ASCII_18 0;
BA_ "GenSigStartValue" SG_ 2589284147 MRR_HR_P_Text_ASCII_19 45;
BA_ "GenSigSwitchedByIgnition" SG_ 2589284147 MRR_HR_P_Text_ASCII_19 0;
BA_ "GenSigStartValue" SG_ 2589284147 MRR_HR_P_Text_ASCII_20 45;
BA_ "GenSigSwitchedByIgnition" SG_ 2589284147 MRR_HR_P_Text_ASCII_20 0;
BA_ "GenSigStartValue" SG_ 2589284147 MRR_HR_P_Text_ASCII_21 45;
BA_ "GenSigSwitchedByIgnition" SG_ 2589284147 MRR_HR_P_Text_ASCII_21 0;
BA_ "GenSigSendType" SG_ 2589284147 MRR_HR_P_Text_Mux 1;
BA_ "GenSigSwitchedByIgnition" SG_ 2589284147 MRR_HR_P_Text_Mux 0;
BA_ "GenSigStartValue" SG_ 2589284144 MRR_VL_P_Text_ASCII_01 45;
BA_ "GenSigStartValue" SG_ 2589284144 MRR_VL_P_Text_ASCII_02 45;
BA_ "GenSigStartValue" SG_ 2589284144 MRR_VL_P_Text_ASCII_03 45;
BA_ "GenSigStartValue" SG_ 2589284144 MRR_VL_P_Text_ASCII_04 45;
BA_ "GenSigStartValue" SG_ 2589284144 MRR_VL_P_Text_ASCII_05 45;
BA_ "GenSigStartValue" SG_ 2589284144 MRR_VL_P_Text_ASCII_06 45;
BA_ "GenSigStartValue" SG_ 2589284144 MRR_VL_P_Text_ASCII_07 45;
BA_ "GenSigStartValue" SG_ 2589284144 MRR_VL_P_Text_ASCII_08 45;
BA_ "GenSigStartValue" SG_ 2589284144 MRR_VL_P_Text_ASCII_09 45;
BA_ "GenSigStartValue" SG_ 2589284144 MRR_VL_P_Text_ASCII_10 45;
BA_ "GenSigStartValue" SG_ 2589284144 MRR_VL_P_Text_ASCII_11 45;
BA_ "GenSigStartValue" SG_ 2589284144 MRR_VL_P_Text_ASCII_12 45;
BA_ "GenSigStartValue" SG_ 2589284144 MRR_VL_P_Text_ASCII_13 45;
BA_ "GenSigStartValue" SG_ 2589284144 MRR_VL_P_Text_ASCII_14 45;
BA_ "GenSigStartValue" SG_ 2589284144 MRR_VL_P_Text_ASCII_15 45;
BA_ "GenSigStartValue" SG_ 2589284144 MRR_VL_P_Text_ASCII_16 45;
BA_ "GenSigStartValue" SG_ 2589284144 MRR_VL_P_Text_ASCII_17 45;
BA_ "GenSigStartValue" SG_ 2589284144 MRR_VL_P_Text_ASCII_18 45;
BA_ "GenSigStartValue" SG_ 2589284144 MRR_VL_P_Text_ASCII_19 45;
BA_ "GenSigStartValue" SG_ 2589284144 MRR_VL_P_Text_ASCII_20 45;
BA_ "GenSigStartValue" SG_ 2589284144 MRR_VL_P_Text_ASCII_21 45;
BA_ "GenSigSendType" SG_ 2589284144 MRR_VL_P_Text_Mux 1;
BA_ "GenSigStartValue" SG_ 2589284145 MRR_VR_P_Text_ASCII_01 45;
BA_ "GenSigStartValue" SG_ 2589284145 MRR_VR_P_Text_ASCII_02 45;
BA_ "GenSigStartValue" SG_ 2589284145 MRR_VR_P_Text_ASCII_03 45;
BA_ "GenSigStartValue" SG_ 2589284145 MRR_VR_P_Text_ASCII_04 45;
BA_ "GenSigStartValue" SG_ 2589284145 MRR_VR_P_Text_ASCII_05 45;
BA_ "GenSigStartValue" SG_ 2589284145 MRR_VR_P_Text_ASCII_06 45;
BA_ "GenSigStartValue" SG_ 2589284145 MRR_VR_P_Text_ASCII_07 45;
BA_ "GenSigStartValue" SG_ 2589284145 MRR_VR_P_Text_ASCII_08 45;
BA_ "GenSigStartValue" SG_ 2589284145 MRR_VR_P_Text_ASCII_09 45;
BA_ "GenSigStartValue" SG_ 2589284145 MRR_VR_P_Text_ASCII_10 45;
BA_ "GenSigStartValue" SG_ 2589284145 MRR_VR_P_Text_ASCII_11 45;
BA_ "GenSigStartValue" SG_ 2589284145 MRR_VR_P_Text_ASCII_12 45;
BA_ "GenSigStartValue" SG_ 2589284145 MRR_VR_P_Text_ASCII_13 45;
BA_ "GenSigStartValue" SG_ 2589284145 MRR_VR_P_Text_ASCII_14 45;
BA_ "GenSigStartValue" SG_ 2589284145 MRR_VR_P_Text_ASCII_15 45;
BA_ "GenSigStartValue" SG_ 2589284145 MRR_VR_P_Text_ASCII_16 45;
BA_ "GenSigStartValue" SG_ 2589284145 MRR_VR_P_Text_ASCII_17 45;
BA_ "GenSigStartValue" SG_ 2589284145 MRR_VR_P_Text_ASCII_18 45;
BA_ "GenSigStartValue" SG_ 2589284145 MRR_VR_P_Text_ASCII_19 45;
BA_ "GenSigStartValue" SG_ 2589284145 MRR_VR_P_Text_ASCII_20 45;
BA_ "GenSigStartValue" SG_ 2589284145 MRR_VR_P_Text_ASCII_21 45;
BA_ "GenSigSendType" SG_ 2589284145 MRR_VR_P_Text_Mux 1;
BA_ "GenSigSendType" SG_ 688 MO_Rekuperation_EM_Ges_Ueberlauf 0;
BA_ "GenSigSwitchedByIgnition" SG_ 688 MO_Rekuperation_EM_Ges_Ueberlauf 0;
BA_ "GenSigSendType" SG_ 688 MO_Rekuperation_Ges_EM 0;
BA_ "GenSigSwitchedByIgnition" SG_ 688 MO_Rekuperation_Ges_EM 0;
BA_ "GenSigSendType" SG_ 688 MO_Verbrauch_EM_Ges 0;
BA_ "GenSigSwitchedByIgnition" SG_ 688 MO_Verbrauch_EM_Ges 0;
BA_ "GenSigSendType" SG_ 688 MO_Verbrauch_EM_Ges_Ueberlauf 0;
BA_ "GenSigSwitchedByIgnition" SG_ 688 MO_Verbrauch_EM_Ges_Ueberlauf 0;
BA_ "GenSigSendType" SG_ 689 TME_Energie_Komfort 0;
BA_ "GenSigStartValue" SG_ 689 TME_Energie_Komfort 16382;
BA_ "GenSigSwitchedByIgnition" SG_ 689 TME_Energie_Komfort 0;
BA_ "Fehlerwert" SG_ 689 TME_Energie_Komfort 16383;
BA_ "GenSigSendType" SG_ 689 TME_Energie_Thermo 0;
BA_ "GenSigStartValue" SG_ 689 TME_Energie_Thermo 16382;
BA_ "GenSigSwitchedByIgnition" SG_ 689 TME_Energie_Thermo 0;
BA_ "Fehlerwert" SG_ 689 TME_Energie_Thermo 16383;
BA_ "GenSigSendType" SG_ 689 TME_PlanAntw_Zaehler 0;
BA_ "GenSigStartValue" SG_ 689 TME_PlanAntw_Zaehler 14;
BA_ "GenSigSwitchedByIgnition" SG_ 689 TME_PlanAntw_Zaehler 0;
BA_ "Fehlerwert" SG_ 689 TME_PlanAntw_Zaehler 15;
BA_ "GenSigSendType" SG_ 689 TME_Verbrauch_gesamt 0;
BA_ "GenSigSwitchedByIgnition" SG_ 689 TME_Verbrauch_gesamt 0;
BA_ "GenSigSendType" SG_ 689 TME_Verbrauch_gesamt_Ueberlauf 0;
BA_ "GenSigSwitchedByIgnition" SG_ 689 TME_Verbrauch_gesamt_Ueberlauf 0;
BA_ "GenSigSendType" SG_ 1284 MV_Bordnetz_aktiv 0;
BA_ "GenSigSwitchedByIgnition" SG_ 1284 MV_Bordnetz_aktiv 0;
BA_ "GenSigSendType" SG_ 1284 MV_Bordnetz_Fehler 3;
BA_ "GenSigSwitchedByIgnition" SG_ 1284 MV_Bordnetz_Fehler 0;
BA_ "Fehlerwert" SG_ 1284 MV_Bordnetz_Fehler 1;
BA_ "GenSigSendType" SG_ 1284 MVK_01_BZ 0;
BA_ "GenSigFuncType" SG_ 1284 MVK_01_BZ 1;
BA_ "GenSigSwitchedByIgnition" SG_ 1284 MVK_01_BZ 0;
BA_ "GenSigSendType" SG_ 1284 MVK_01_CRC 0;
BA_ "GenSigFuncType" SG_ 1284 MVK_01_CRC 2;
BA_ "GenSigSwitchedByIgnition" SG_ 1284 MVK_01_CRC 0;
BA_ "GenSigSendType" SG_ 1284 MVK_BMS_Sollmodus 3;
BA_ "GenSigStartValue" SG_ 1284 MVK_BMS_Sollmodus 7;
BA_ "GenSigSwitchedByIgnition" SG_ 1284 MVK_BMS_Sollmodus 0;
BA_ "GenSigSendType" SG_ 1284 MVK_BOOST_Sollmodus 3;
BA_ "GenSigStartValue" SG_ 1284 MVK_BOOST_Sollmodus 7;
BA_ "GenSigSwitchedByIgnition" SG_ 1284 MVK_BOOST_Sollmodus 0;
BA_ "GenSigSendType" SG_ 1284 MVK_DCDC_Sollmodus 3;
BA_ "GenSigStartValue" SG_ 1284 MVK_DCDC_Sollmodus 7;
BA_ "GenSigSwitchedByIgnition" SG_ 1284 MVK_DCDC_Sollmodus 0;
BA_ "GenSigSendType" SG_ 1284 MVK_DCDC_Sollmodus_02 3;
BA_ "GenSigStartValue" SG_ 1284 MVK_DCDC_Sollmodus_02 7;
BA_ "GenSigSwitchedByIgnition" SG_ 1284 MVK_DCDC_Sollmodus_02 0;
BA_ "GenSigSendType" SG_ 1284 MVK_eABC_Sollmodus 3;
BA_ "GenSigStartValue" SG_ 1284 MVK_eABC_Sollmodus 7;
BA_ "GenSigSwitchedByIgnition" SG_ 1284 MVK_eABC_Sollmodus 0;
BA_ "GenSigSendType" SG_ 1284 MVK_eAWS_Sollmodus 3;
BA_ "GenSigStartValue" SG_ 1284 MVK_eAWS_Sollmodus 7;
BA_ "GenSigSwitchedByIgnition" SG_ 1284 MVK_eAWS_Sollmodus 0;
BA_ "GenSigSendType" SG_ 1284 MVK_eKAT_Sollmodus 3;
BA_ "GenSigStartValue" SG_ 1284 MVK_eKAT_Sollmodus 6;
BA_ "GenSigSwitchedByIgnition" SG_ 1284 MVK_eKAT_Sollmodus 0;
BA_ "GenSigSendType" SG_ 1284 MVK_eKMV_Sollmodus 3;
BA_ "GenSigStartValue" SG_ 1284 MVK_eKMV_Sollmodus 7;
BA_ "GenSigSwitchedByIgnition" SG_ 1284 MVK_eKMV_Sollmodus 0;
BA_ "GenSigSendType" SG_ 1284 MVK_Istmodus_Anf 3;
BA_ "GenSigSwitchedByIgnition" SG_ 1284 MVK_Istmodus_Anf 0;
BA_ "GenSigSendType" SG_ 1284 MVK_MO_EmSollzustand 3;
BA_ "GenSigStartValue" SG_ 1284 MVK_MO_EmSollzustand 255;
BA_ "GenSigSwitchedByIgnition" SG_ 1284 MVK_MO_EmSollzustand 0;
BA_ "GenSigSendType" SG_ 1284 MVK_MV_Netz_Warnungen 3;
BA_ "GenSigSwitchedByIgnition" SG_ 1284 MVK_MV_Netz_Warnungen 0;
BA_ "GenSigSendType" SG_ 1284 MVK_MVH_L_Sollmodus 3;
BA_ "GenSigStartValue" SG_ 1284 MVK_MVH_L_Sollmodus 7;
BA_ "GenSigSwitchedByIgnition" SG_ 1284 MVK_MVH_L_Sollmodus 0;
BA_ "GenSigSendType" SG_ 1284 MVK_MVPTC_Sollmodus 3;
BA_ "GenSigStartValue" SG_ 1284 MVK_MVPTC_Sollmodus 7;
BA_ "GenSigSwitchedByIgnition" SG_ 1284 MVK_MVPTC_Sollmodus 0;
BA_ "GenSigSendType" SG_ 1157 ND_SatInUse 0;
BA_ "GenSigStartValue" SG_ 1157 ND_SatInUse 30;
BA_ "GenSigSwitchedByIgnition" SG_ 1157 ND_SatInUse 0;
BA_ "Fehlerwert" SG_ 1157 ND_SatInUse 31;
BA_ "GenSigSendType" SG_ 1157 ND_SatInView 0;
BA_ "GenSigStartValue" SG_ 1157 ND_SatInView 30;
BA_ "GenSigSwitchedByIgnition" SG_ 1157 ND_SatInView 0;
BA_ "Fehlerwert" SG_ 1157 ND_SatInView 31;
BA_ "GenSigSendType" SG_ 1157 ND_UTC 0;
BA_ "GenSigSwitchedByIgnition" SG_ 1157 ND_UTC 0;
BA_ "GenSigSendType" SG_ 1157 NP_Altitude 0;
BA_ "GenSigStartValue" SG_ 1157 NP_Altitude 4094;
BA_ "GenSigSwitchedByIgnition" SG_ 1157 NP_Altitude 0;
BA_ "Fehlerwert" SG_ 1157 NP_Altitude 4095;
BA_ "GenSigSendType" SG_ 1157 POS_Guete_horizontal 0;
BA_ "GenSigStartValue" SG_ 1157 POS_Guete_horizontal 126;
BA_ "GenSigSwitchedByIgnition" SG_ 1157 POS_Guete_horizontal 0;
BA_ "Fehlerwert" SG_ 1157 POS_Guete_horizontal 127;
BA_ "GenSigSendType" SG_ 1157 POS_Guete_horizontal_verfuegbar 0;
BA_ "GenSigSwitchedByIgnition" SG_ 1157 POS_Guete_horizontal_verfuegbar 0;
BA_ "GenSigSendType" SG_ 2527679512 ND_Fuelstation_detected 0;
BA_ "GenSigStartValue" SG_ 2527679512 ND_Fuelstation_detected 3;
BA_ "GenSigSwitchedByIgnition" SG_ 2527679512 ND_Fuelstation_detected 0;
BA_ "GenSigSendType" SG_ 2527679512 ND_NrSameMeasure 0;
BA_ "GenSigSwitchedByIgnition" SG_ 2527679512 ND_NrSameMeasure 0;
BA_ "GenSigSendType" SG_ 2527679512 ND_RecDelay 0;
BA_ "GenSigStartValue" SG_ 2527679512 ND_RecDelay 4094;
BA_ "GenSigSwitchedByIgnition" SG_ 2527679512 ND_RecDelay 0;
BA_ "Fehlerwert" SG_ 2527679512 ND_RecDelay 4095;
BA_ "GenSigSendType" SG_ 2527679512 ND_RouteType 0;
BA_ "GenSigSwitchedByIgnition" SG_ 2527679512 ND_RouteType 0;
BA_ "GenSigSendType" SG_ 2527679512 ND_SendDelay 0;
BA_ "GenSigStartValue" SG_ 2527679512 ND_SendDelay 4094;
BA_ "GenSigSwitchedByIgnition" SG_ 2527679512 ND_SendDelay 0;
BA_ "Fehlerwert" SG_ 2527679512 ND_SendDelay 4095;
BA_ "GenSigSendType" SG_ 2527679512 ND_TimeOffset 0;
BA_ "GenSigSwitchedByIgnition" SG_ 2527679512 ND_TimeOffset 0;
BA_ "GenSigSendType" SG_ 2527679512 ND_TimeToDestination 0;
BA_ "GenSigStartValue" SG_ 2527679512 ND_TimeToDestination 511;
BA_ "GenSigSwitchedByIgnition" SG_ 2527679512 ND_TimeToDestination 0;
BA_ "Fehlerwert" SG_ 2527679512 ND_TimeToDestination 510;
BA_ "GenSigSendType" SG_ 2527679512 ND_Timezone_DaylightSavingOffset 0;
BA_ "GenSigSwitchedByIgnition" SG_ 2527679512 ND_Timezone_DaylightSavingOffset 0;
BA_ "GenSigSendType" SG_ 2527679512 ND_Timezone_Offset 0;
BA_ "GenSigStartValue" SG_ 2527679512 ND_Timezone_Offset 14;
BA_ "GenSigSwitchedByIgnition" SG_ 2527679512 ND_Timezone_Offset 0;
BA_ "Fehlerwert" SG_ 2527679512 ND_Timezone_Offset 15;
BA_ "GenSigSendType" SG_ 2527679512 ND_Timezone_SignBit 0;
BA_ "GenSigSwitchedByIgnition" SG_ 2527679512 ND_Timezone_SignBit 0;
BA_ "GenSigSendType" SG_ 2527679512 ND_Timezone_Validity 0;
BA_ "GenSigSwitchedByIgnition" SG_ 2527679512 ND_Timezone_Validity 0;
BA_ "GenSigSendType" SG_ 2527679512 ND_Velocity 0;
BA_ "GenSigStartValue" SG_ 2527679512 ND_Velocity 1022;
BA_ "GenSigSwitchedByIgnition" SG_ 2527679512 ND_Velocity 0;
BA_ "Fehlerwert" SG_ 2527679512 ND_Velocity 1023;
BA_ "GenSigSendType" SG_ 1696 NV_Akt_Status_MMI 3;
BA_ "GenSigStartValue" SG_ 1696 NV_Akt_Status_MMI 3;
BA_ "GenSigSendType" SG_ 1696 NV_aktiv 3;
BA_ "GenSigSendType" SG_ 1696 NV_Akustik_deaktiviert_Icon 3;
BA_ "GenSigSendType" SG_ 1696 NV_Anf_Prefill 3;
BA_ "GenSigSendType" SG_ 1696 NV_AnforderungBildaufschaltung 3;
BA_ "GenSigSendType" SG_ 1696 NV_FAS_Fkt_Status 0;
BA_ "Fehlerwert" SG_ 1696 NV_FAS_Fkt_Status 3;
BA_ "GenSigSendType" SG_ 1696 NV_FGM_deaktiviert_Icon 3;
BA_ "GenSigSendType" SG_ 1696 NV_Gong 3;
BA_ "GenSigSendType" SG_ 1696 NV_HBA_Parameter 3;
BA_ "GenSigSendType" SG_ 1696 NV_Hinweise 3;
BA_ "GenSigSendType" SG_ 1696 NV_LED_Leiste 3;
BA_ "GenSigSendType" SG_ 1696 NV_Markierungslicht_links 3;
BA_ "GenSigSendType" SG_ 1696 NV_Markierungslicht_rechts 3;
BA_ "GenSigSendType" SG_ 1696 NV_Piktogramm_aktiv 3;
BA_ "GenSigSendType" SG_ 1696 NV_PreSense_Modus_System 3;
BA_ "GenSigSendType" SG_ 1696 NV_PreSense_Modus_Warnung 3;
BA_ "GenSigSendType" SG_ 1696 NV_PreSense_Status 3;
BA_ "GenSigSendType" SG_ 1696 NV_Symbol 3;
BA_ "GenSigSendType" SG_ 1696 NV_Symbol_Tierwarnung 3;
BA_ "GenSigSendType" SG_ 1696 NV_Texte 3;
BA_ "GenSigActiveRepetitions" SG_ 2600468496 NM_Gateway_CAB 3;
BA_ "GenSigSendType" SG_ 2600468496 NM_Gateway_CAB 4;
BA_ "GenSigFuncType" SG_ 2600468496 NM_Gateway_CAB 16;
BA_ "GenSigSwitchedByIgnition" SG_ 2600468496 NM_Gateway_CAB 0;
BA_ "GenSigSendType" SG_ 2600468496 NM_Gateway_Car_Wakeup 3;
BA_ "GenSigSwitchedByIgnition" SG_ 2600468496 NM_Gateway_Car_Wakeup 0;
BA_ "GenSigSwitchedByIgnition" SG_ 2600468496 NM_Gateway_CBV_AWB 0;
BA_ "GenSigSwitchedByIgnition" SG_ 2600468496 NM_Gateway_CBV_CRI 0;
BA_ "GenSigSwitchedByIgnition" SG_ 2600468496 NM_Gateway_NM_aktiv_Buskopplung 0;
BA_ "GenSigSwitchedByIgnition" SG_ 2600468496 NM_Gateway_NM_aktiv_Connect 0;
BA_ "GenSigSwitchedByIgnition" SG_ 2600468496 NM_Gateway_NM_aktiv_CWU 0;
BA_ "GenSigSwitchedByIgnition" SG_ 2600468496 NM_Gateway_NM_aktiv_Diagnose 0;
BA_ "GenSigSwitchedByIgnition" SG_ 2600468496 NM_Gateway_NM_aktiv_EM 0;
BA_ "GenSigSwitchedByIgnition" SG_ 2600468496 NM_Gateway_NM_aktiv_FC 0;
BA_ "GenSigSwitchedByIgnition" SG_ 2600468496 NM_Gateway_NM_aktiv_Fremdladung 0;
BA_ "GenSigSwitchedByIgnition" SG_ 2600468496 NM_Gateway_NM_aktiv_KL15 0;
BA_ "GenSigSwitchedByIgnition" SG_ 2600468496 NM_Gateway_NM_aktiv_LIN2 0;
BA_ "GenSigSwitchedByIgnition" SG_ 2600468496 NM_Gateway_NM_aktiv_OBDC 0;
BA_ "GenSigSwitchedByIgnition" SG_ 2600468496 NM_Gateway_NM_aktiv_Tmin 0;
BA_ "GenSigSwitchedByIgnition" SG_ 2600468496 NM_Gateway_NM_State 0;
BA_ "GenSigStartValue" SG_ 2600468496 NM_Gateway_SNI 16;
BA_ "GenSigSwitchedByIgnition" SG_ 2600468496 NM_Gateway_SNI 0;
BA_ "GenSigSwitchedByIgnition" SG_ 2600468496 NM_Gateway_UDS_CC 0;
BA_ "GenSigActiveRepetitions" SG_ 2600468507 NM_HUD_CAB 3;
BA_ "GenSigSendType" SG_ 2600468507 NM_HUD_CAB 4;
BA_ "GenSigSwitchedByIgnition" SG_ 2600468507 NM_HUD_CAB 0;
BA_ "GenSigSendType" SG_ 2600468507 NM_HUD_Car_WakeUp 3;
BA_ "GenSigSwitchedByIgnition" SG_ 2600468507 NM_HUD_Car_WakeUp 0;
BA_ "GenSigSwitchedByIgnition" SG_ 2600468507 NM_HUD_CBV_AWB 0;
BA_ "GenSigStartValue" SG_ 2600468507 NM_HUD_CBV_CRI 1;
BA_ "GenSigSwitchedByIgnition" SG_ 2600468507 NM_HUD_CBV_CRI 0;
BA_ "GenSigSwitchedByIgnition" SG_ 2600468507 NM_HUD_NM_aktiv_Diagnose 0;
BA_ "GenSigSwitchedByIgnition" SG_ 2600468507 NM_HUD_NM_aktiv_KL15 0;
BA_ "GenSigSwitchedByIgnition" SG_ 2600468507 NM_HUD_NM_aktiv_Tmin 0;
BA_ "GenSigSwitchedByIgnition" SG_ 2600468507 NM_HUD_NM_State 0;
BA_ "GenSigStartValue" SG_ 2600468507 NM_HUD_SNI 27;
BA_ "GenSigSwitchedByIgnition" SG_ 2600468507 NM_HUD_SNI 0;
BA_ "GenSigSwitchedByIgnition" SG_ 2600468507 NM_HUD_UDS_CC 0;
BA_ "GenSigActiveRepetitions" SG_ 2600468500 NM_Kombi_CAB 3;
BA_ "GenSigSendType" SG_ 2600468500 NM_Kombi_CAB 4;
BA_ "GenSigSwitchedByIgnition" SG_ 2600468500 NM_Kombi_CAB 0;
BA_ "GenSigSendType" SG_ 2600468500 NM_Kombi_Car_Wakeup 3;
BA_ "GenSigSwitchedByIgnition" SG_ 2600468500 NM_Kombi_Car_Wakeup 0;
BA_ "GenSigSwitchedByIgnition" SG_ 2600468500 NM_Kombi_CBV_AWB 0;
BA_ "GenSigFuncType" SG_ 2600468500 NM_Kombi_CBV_CRI 8;
BA_ "GenSigSwitchedByIgnition" SG_ 2600468500 NM_Kombi_CBV_CRI 0;
BA_ "GenSigSwitchedByIgnition" SG_ 2600468500 NM_Kombi_NM_aktiv_Buzzer 0;
BA_ "GenSigSwitchedByIgnition" SG_ 2600468500 NM_Kombi_NM_aktiv_Diagnose 0;
BA_ "GenSigSwitchedByIgnition" SG_ 2600468500 NM_Kombi_NM_aktiv_Display 0;
BA_ "GenSigSwitchedByIgnition" SG_ 2600468500 NM_Kombi_NM_aktiv_KL15 0;
BA_ "GenSigSwitchedByIgnition" SG_ 2600468500 NM_Kombi_NM_aktiv_Tankinhalt 0;
BA_ "GenSigSwitchedByIgnition" SG_ 2600468500 NM_Kombi_NM_aktiv_Tmin 0;
BA_ "GenSigSwitchedByIgnition" SG_ 2600468500 NM_Kombi_NM_State 0;
BA_ "GenSigStartValue" SG_ 2600468500 NM_Kombi_SNI 20;
BA_ "GenSigSwitchedByIgnition" SG_ 2600468500 NM_Kombi_SNI 0;
BA_ "GenSigSwitchedByIgnition" SG_ 2600468500 NM_Kombi_UDS_CC 0;
BA_ "GenSigActiveRepetitions" SG_ 2600468563 NM_Waehlhebel_CAB 3;
BA_ "GenSigSendType" SG_ 2600468563 NM_Waehlhebel_CAB 4;
BA_ "GenSigSwitchedByIgnition" SG_ 2600468563 NM_Waehlhebel_CAB 0;
BA_ "GenSigSendType" SG_ 2600468563 NM_Waehlhebel_Car_Wakeup 3;
BA_ "GenSigSwitchedByIgnition" SG_ 2600468563 NM_Waehlhebel_Car_Wakeup 0;
BA_ "GenSigSwitchedByIgnition" SG_ 2600468563 NM_Waehlhebel_CBV_AWB 0;
BA_ "GenSigSwitchedByIgnition" SG_ 2600468563 NM_Waehlhebel_CBV_CRI 0;
BA_ "GenSigSwitchedByIgnition" SG_ 2600468563 NM_Waehlhebel_NM_aktiv_Diagnose 0;
BA_ "GenSigSwitchedByIgnition" SG_ 2600468563 NM_Waehlhebel_NM_aktiv_KL15 0;
BA_ "GenSigSwitchedByIgnition" SG_ 2600468563 NM_Waehlhebel_NM_aktiv_Tmin 0;
BA_ "GenSigSwitchedByIgnition" SG_ 2600468563 NM_Waehlhebel_NM_State 0;
BA_ "GenSigStartValue" SG_ 2600468563 NM_Waehlhebel_SNI 83;
BA_ "GenSigSwitchedByIgnition" SG_ 2600468563 NM_Waehlhebel_SNI 0;
BA_ "GenSigSwitchedByIgnition" SG_ 2600468563 NM_Waehlhebel_UDS_CC 0;
BA_ "GenSigSendType" SG_ 1635 BEM_02_Abschaltstufen 0;
BA_ "GenSigSwitchedByIgnition" SG_ 1635 BEM_02_Abschaltstufen 0;
BA_ "GenSigSendType" SG_ 1635 BEM_Anf_KL15_schalten 0;
BA_ "GenSigSwitchedByIgnition" SG_ 1635 BEM_Anf_KL15_schalten 0;
BA_ "GenSigSendType" SG_ 1635 BEM_Batteriediagnose 0;
BA_ "GenSigSwitchedByIgnition" SG_ 1635 BEM_Batteriediagnose 0;
BA_ "Fehlerwert" SG_ 1635 BEM_Batteriediagnose 7;
BA_ "GenSigSendType" SG_ 1635 BEM_Generatordiagnose 0;
BA_ "GenSigSwitchedByIgnition" SG_ 1635 BEM_Generatordiagnose 0;
BA_ "GenSigSendType" SG_ 1635 BEM_HL_Regelung_Status 0;
BA_ "GenSigSwitchedByIgnition" SG_ 1635 BEM_HL_Regelung_Status 0;
BA_ "GenSigSendType" SG_ 1635 BEM_Ladezustand 0;
BA_ "GenSigStartValue" SG_ 1635 BEM_Ladezustand 14;
BA_ "GenSigSwitchedByIgnition" SG_ 1635 BEM_Ladezustand 0;
BA_ "Fehlerwert" SG_ 1635 BEM_Ladezustand 15;
BA_ "GenSigSendType" SG_ 1635 BEM_MMI_Vorwarnung 0;
BA_ "GenSigSwitchedByIgnition" SG_ 1635 BEM_MMI_Vorwarnung 0;
BA_ "GenSigSendType" SG_ 1635 BEM_Red_Innengeblaese 0;
BA_ "GenSigSwitchedByIgnition" SG_ 1635 BEM_Red_Innengeblaese 0;
BA_ "GenSigSendType" SG_ 1635 BEM_REK_aktiv 0;
BA_ "GenSigSwitchedByIgnition" SG_ 1635 BEM_REK_aktiv 0;
BA_ "GenSigSendType" SG_ 1635 BEM_STH_Einschaltverbot 0;
BA_ "GenSigSwitchedByIgnition" SG_ 1635 BEM_STH_Einschaltverbot 0;
BA_ "GenSigSendType" SG_ 1635 BEM_STH_Zielzeit 0;
BA_ "GenSigStartValue" SG_ 1635 BEM_STH_Zielzeit 14;
BA_ "GenSigSwitchedByIgnition" SG_ 1635 BEM_STH_Zielzeit 0;
BA_ "Fehlerwert" SG_ 1635 BEM_STH_Zielzeit 15;
BA_ "GenSigSendType" SG_ 1635 BEM_UBDM 0;
BA_ "GenSigSwitchedByIgnition" SG_ 1635 BEM_UBDM 0;
BA_ "Fehlerwert" SG_ 1635 BEM_UBDM 255;
BA_ "GenSigSendType" SG_ 1635 BEM_UGenSoll 0;
BA_ "GenSigSwitchedByIgnition" SG_ 1635 BEM_UGenSoll 0;
BA_ "GenSigSendType" SG_ 1635 MIB_Stromsparmodus 0;
BA_ "GenSigSwitchedByIgnition" SG_ 1635 MIB_Stromsparmodus 0;
BA_ "GenSigSendType" SG_ 1635 NVEM_Anf_SD_schalten 0;
BA_ "GenSigSwitchedByIgnition" SG_ 1635 NVEM_Anf_SD_schalten 0;
BA_ "GenSigSendType" SG_ 1635 NVEM_Batterie_Service 0;
BA_ "GenSigSwitchedByIgnition" SG_ 1635 NVEM_Batterie_Service 0;
BA_ "GenSigSendType" SG_ 1635 NVEM_Freigabe_OnlineUpdate 0;
BA_ "GenSigSwitchedByIgnition" SG_ 1635 NVEM_Freigabe_OnlineUpdate 0;
BA_ "GenSigSendType" SG_ 1635 NVEM_Freigabe_ORU4 0;
BA_ "GenSigSwitchedByIgnition" SG_ 1635 NVEM_Freigabe_ORU4 0;
BA_ "GenSigSendType" SG_ 1635 NVEM_Last_Anf 0;
BA_ "GenSigSwitchedByIgnition" SG_ 1635 NVEM_Last_Anf 0;
BA_ "GenSigSendType" SG_ 2527679508 NVEM_06_BZ 0;
BA_ "GenSigFuncType" SG_ 2527679508 NVEM_06_BZ 1;
BA_ "GenSigSwitchedByIgnition" SG_ 2527679508 NVEM_06_BZ 0;
BA_ "GenSigSendType" SG_ 2527679508 NVEM_06_CRC 0;
BA_ "GenSigFuncType" SG_ 2527679508 NVEM_06_CRC 2;
BA_ "GenSigSwitchedByIgnition" SG_ 2527679508 NVEM_06_CRC 0;
BA_ "GenSigSendType" SG_ 2527679508 NVEM_Bordnetzdiagnose 0;
BA_ "GenSigSwitchedByIgnition" SG_ 2527679508 NVEM_Bordnetzdiagnose 0;
BA_ "GenSigSendType" SG_ 2527679508 NVEM_Energie_Klima_Vorgabe 0;
BA_ "GenSigStartValue" SG_ 2527679508 NVEM_Energie_Klima_Vorgabe 254;
BA_ "GenSigSwitchedByIgnition" SG_ 2527679508 NVEM_Energie_Klima_Vorgabe 0;
BA_ "Fehlerwert" SG_ 2527679508 NVEM_Energie_Klima_Vorgabe 255;
BA_ "GenSigSendType" SG_ 2527679508 NVEM_Max_Rampenzeit 0;
BA_ "GenSigStartValue" SG_ 2527679508 NVEM_Max_Rampenzeit 6;
BA_ "GenSigSwitchedByIgnition" SG_ 2527679508 NVEM_Max_Rampenzeit 0;
BA_ "GenSigSendType" SG_ 2527679508 NVEM_Max_Spannung 0;
BA_ "GenSigStartValue" SG_ 2527679508 NVEM_Max_Spannung 126;
BA_ "GenSigSwitchedByIgnition" SG_ 2527679508 NVEM_Max_Spannung 0;
BA_ "Fehlerwert" SG_ 2527679508 NVEM_Max_Spannung 127;
BA_ "GenSigSendType" SG_ 2527679508 NVEM_Min_Spannung 0;
BA_ "GenSigStartValue" SG_ 2527679508 NVEM_Min_Spannung 126;
BA_ "GenSigSwitchedByIgnition" SG_ 2527679508 NVEM_Min_Spannung 0;
BA_ "Fehlerwert" SG_ 2527679508 NVEM_Min_Spannung 127;
BA_ "GenSigSendType" SG_ 2527679508 NVEM_Min_Spannung_Start 3;
BA_ "GenSigStartValue" SG_ 2527679508 NVEM_Min_Spannung_Start 62;
BA_ "GenSigSwitchedByIgnition" SG_ 2527679508 NVEM_Min_Spannung_Start 0;
BA_ "Fehlerwert" SG_ 2527679508 NVEM_Min_Spannung_Start 63;
BA_ "GenSigSendType" SG_ 2527679508 NVEM_MV_DC_uMinLV 0;
BA_ "GenSigStartValue" SG_ 2527679508 NVEM_MV_DC_uMinLV 126;
BA_ "GenSigSwitchedByIgnition" SG_ 2527679508 NVEM_MV_DC_uMinLV 0;
BA_ "Fehlerwert" SG_ 2527679508 NVEM_MV_DC_uMinLV 127;
BA_ "GenSigSendType" SG_ 2527679508 NVEM_MV_DC_uSollLV 0;
BA_ "GenSigStartValue" SG_ 2527679508 NVEM_MV_DC_uSollLV 126;
BA_ "GenSigSwitchedByIgnition" SG_ 2527679508 NVEM_MV_DC_uSollLV 0;
BA_ "Fehlerwert" SG_ 2527679508 NVEM_MV_DC_uSollLV 127;
BA_ "GenSigSendType" SG_ 913 MO_QBit_Aussen_Temp 0;
BA_ "GenSigStartValue" SG_ 913 MO_QBit_Aussen_Temp 1;
BA_ "GenSigSwitchedByIgnition" SG_ 913 MO_QBit_Aussen_Temp 0;
BA_ "GenSigSendType" SG_ 913 MO_Servicemodus 0;
BA_ "GenSigSwitchedByIgnition" SG_ 913 MO_Servicemodus 0;
BA_ "GenSigSendType" SG_ 913 OBD_Abs_Load_Val 0;
BA_ "GenSigStartValue" SG_ 913 OBD_Abs_Load_Val 65535;
BA_ "GenSigSwitchedByIgnition" SG_ 913 OBD_Abs_Load_Val 0;
BA_ "GenSigSendType" SG_ 913 OBD_Abs_Pedal_Pos 0;
BA_ "GenSigStartValue" SG_ 913 OBD_Abs_Pedal_Pos 255;
BA_ "GenSigSwitchedByIgnition" SG_ 913 OBD_Abs_Pedal_Pos 0;
BA_ "GenSigSendType" SG_ 913 OBD_Abs_Throttle_Pos 0;
BA_ "GenSigStartValue" SG_ 913 OBD_Abs_Throttle_Pos 255;
BA_ "GenSigSwitchedByIgnition" SG_ 913 OBD_Abs_Throttle_Pos 0;
BA_ "GenSigSendType" SG_ 913 OBD_Calc_Load_Val 0;
BA_ "GenSigStartValue" SG_ 913 OBD_Calc_Load_Val 255;
BA_ "GenSigSwitchedByIgnition" SG_ 913 OBD_Calc_Load_Val 0;
BA_ "GenSigSendType" SG_ 913 OBD_ClearMem_Inhibit 0;
BA_ "GenSigSwitchedByIgnition" SG_ 913 OBD_ClearMem_Inhibit 0;
BA_ "GenSigSendType" SG_ 913 OBD_Driving_Cycle 0;
BA_ "GenSigSwitchedByIgnition" SG_ 913 OBD_Driving_Cycle 0;
BA_ "GenSigSendType" SG_ 913 OBD_Eng_Cool_Temp 0;
BA_ "GenSigStartValue" SG_ 913 OBD_Eng_Cool_Temp 255;
BA_ "GenSigSwitchedByIgnition" SG_ 913 OBD_Eng_Cool_Temp 0;
BA_ "GenSigSendType" SG_ 913 OBD_Kaltstart_Denominator 0;
BA_ "GenSigSwitchedByIgnition" SG_ 913 OBD_Kaltstart_Denominator 0;
BA_ "GenSigSendType" SG_ 913 OBD_Minimum_Trip 0;
BA_ "GenSigSwitchedByIgnition" SG_ 913 OBD_Minimum_Trip 0;
BA_ "GenSigSendType" SG_ 913 OBD_Normed_Trip 0;
BA_ "GenSigSwitchedByIgnition" SG_ 913 OBD_Normed_Trip 0;
BA_ "GenSigSendType" SG_ 913 OBD_Sperrung_IUMPR 0;
BA_ "GenSigSwitchedByIgnition" SG_ 913 OBD_Sperrung_IUMPR 0;
BA_ "GenSigSendType" SG_ 913 OBD_Sperrung_Kaltstart_Denom 0;
BA_ "GenSigSwitchedByIgnition" SG_ 913 OBD_Sperrung_Kaltstart_Denom 0;
BA_ "GenSigSendType" SG_ 913 OBD_Warm_Up_Cycle 0;
BA_ "GenSigSwitchedByIgnition" SG_ 913 OBD_Warm_Up_Cycle 0;
BA_ "GenSigSendType" SG_ 2549940736 OBDC_Funktionaler_Req_All_Data 3;
BA_ "GenSigFuncType" SG_ 2549940736 OBDC_Funktionaler_Req_All_Data 9;
BA_ "GenSigSwitchedByIgnition" SG_ 2549940736 OBDC_Funktionaler_Req_All_Data 0;
BA_ "GenSigSendType" SG_ 2549875227 OBDC_HUD_Req_Data 3;
BA_ "GenSigFuncType" SG_ 2549875227 OBDC_HUD_Req_Data 9;
BA_ "GenSigSwitchedByIgnition" SG_ 2549875227 OBDC_HUD_Req_Data 0;
BA_ "GenSigSendType" SG_ 2550006299 OBDC_HUD_Resp_Data 3;
BA_ "GenSigFuncType" SG_ 2550006299 OBDC_HUD_Resp_Data 9;
BA_ "GenSigSwitchedByIgnition" SG_ 2550006299 OBDC_HUD_Resp_Data 0;
BA_ "GenSigSendType" SG_ 2549875220 OBDC_Kombi_Req_Data 3;
BA_ "GenSigFuncType" SG_ 2549875220 OBDC_Kombi_Req_Data 9;
BA_ "GenSigSwitchedByIgnition" SG_ 2549875220 OBDC_Kombi_Req_Data 0;
BA_ "GenSigSendType" SG_ 2550006292 OBDC_Kombi_Resp_Data 3;
BA_ "GenSigFuncType" SG_ 2550006292 OBDC_Kombi_Resp_Data 9;
BA_ "GenSigSwitchedByIgnition" SG_ 2550006292 OBDC_Kombi_Resp_Data 0;
BA_ "GenSigSendType" SG_ 2549875283 OBDC_Waehlhebel_Req_Data 3;
BA_ "GenSigFuncType" SG_ 2549875283 OBDC_Waehlhebel_Req_Data 9;
BA_ "GenSigSwitchedByIgnition" SG_ 2549875283 OBDC_Waehlhebel_Req_Data 0;
BA_ "GenSigSendType" SG_ 2550006355 OBDC_Waehlhebel_Resp_Data 3;
BA_ "GenSigFuncType" SG_ 2550006355 OBDC_Waehlhebel_Resp_Data 9;
BA_ "GenSigSwitchedByIgnition" SG_ 2550006355 OBDC_Waehlhebel_Resp_Data 0;
BA_ "GenSigSendType" SG_ 2589283656 ORU_Status 3;
BA_ "GenSigSwitchedByIgnition" SG_ 2589283656 ORU_Status 0;
BA_ "GenSigSendType" SG_ 2589283656 ORU_Warnung 3;
BA_ "GenSigSwitchedByIgnition" SG_ 2589283656 ORU_Warnung 0;
BA_ "GenSigActiveRepetitions" SG_ 2527679670 ORU_EM_Anfrage_Flashdauer 5;
BA_ "GenSigSendType" SG_ 2527679670 ORU_EM_Anfrage_Flashdauer 4;
BA_ "GenSigSwitchedByIgnition" SG_ 2527679670 ORU_EM_Anfrage_Flashdauer 0;
BA_ "GenSigActiveRepetitions" SG_ 2527679670 ORU_EM_Anfrage_freigegebeneNetze 5;
BA_ "GenSigSendType" SG_ 2527679670 ORU_EM_Anfrage_freigegebeneNetze 4;
BA_ "GenSigSwitchedByIgnition" SG_ 2527679670 ORU_EM_Anfrage_freigegebeneNetze 0;
BA_ "GenSigActiveRepetitions" SG_ 2527679670 ORU_EM_Anfrage_Stromaufnahme 5;
BA_ "GenSigSendType" SG_ 2527679670 ORU_EM_Anfrage_Stromaufnahme 4;
BA_ "GenSigSwitchedByIgnition" SG_ 2527679670 ORU_EM_Anfrage_Stromaufnahme 0;
BA_ "GenSigActiveRepetitions" SG_ 2527679670 ORU_Status_Anf 5;
BA_ "GenSigSendType" SG_ 2527679670 ORU_Status_Anf 4;
BA_ "GenSigSwitchedByIgnition" SG_ 2527679670 ORU_Status_Anf 0;
BA_ "GenSigSendType" SG_ 2527679670 OTA_FC_FahrwerkAnf 0;
BA_ "GenSigSwitchedByIgnition" SG_ 2527679670 OTA_FC_FahrwerkAnf 0;
BA_ "GenSigSendType" SG_ 2527679670 OTA_FC_FoD_Stornierung 3;
BA_ "GenSigActiveRepetitions" SG_ 2527679670 OTA_FC_Hinweis_Update 5;
BA_ "GenSigSendType" SG_ 2527679670 OTA_FC_Hinweis_Update 4;
BA_ "GenSigSwitchedByIgnition" SG_ 2527679670 OTA_FC_Hinweis_Update 0;
BA_ "GenSigActiveRepetitions" SG_ 2527679670 OTA_FC_IOF_Ausfall 5;
BA_ "GenSigSendType" SG_ 2527679670 OTA_FC_IOF_Ausfall 4;
BA_ "GenSigSwitchedByIgnition" SG_ 2527679670 OTA_FC_IOF_Ausfall 0;
BA_ "GenSigSendType" SG_ 2527679670 OTA_FC_LiftAnf 0;
BA_ "GenSigSwitchedByIgnition" SG_ 2527679670 OTA_FC_LiftAnf 0;
BA_ "GenSigSendType" SG_ 2527679670 OTA_FC_NiveauAnf 0;
BA_ "GenSigSwitchedByIgnition" SG_ 2527679670 OTA_FC_NiveauAnf 0;
BA_ "GenSigActiveRepetitions" SG_ 2527679670 OTA_FC_PredMaint_Ausfall 5;
BA_ "GenSigSendType" SG_ 2527679670 OTA_FC_PredMaint_Ausfall 4;
BA_ "GenSigSwitchedByIgnition" SG_ 2527679670 OTA_FC_PredMaint_Ausfall 0;
BA_ "GenSigActiveRepetitions" SG_ 2527679670 OTA_FC_Warnung_Update 5;
BA_ "GenSigSendType" SG_ 2527679670 OTA_FC_Warnung_Update 4;
BA_ "GenSigSwitchedByIgnition" SG_ 2527679670 OTA_FC_Warnung_Update 0;
BA_ "GenSigSendType" SG_ 970 PACC02_Automode 0;
BA_ "GenSigSendType" SG_ 970 PACC02_Durchschnittsgeschw 0;
BA_ "GenSigSendType" SG_ 970 PACC02_InnoDrive_Texte 0;
BA_ "GenSigSwitchedByIgnition" SG_ 970 PACC02_InnoDrive_Texte 0;
BA_ "GenSigSendType" SG_ 970 PACC02_naechstes_Event 0;
BA_ "GenSigSendType" SG_ 970 PACC02_Offset 0;
BA_ "GenSigStartValue" SG_ 970 PACC02_Offset 255;
BA_ "GenSigSendType" SG_ 970 PACC02_Segelanteil 0;
BA_ "GenSigSendType" SG_ 970 PACC02_Sollgeschwindigkeit 0;
BA_ "GenSigStartValue" SG_ 970 PACC02_Sollgeschwindigkeit 1022;
BA_ "GenSigSendType" SG_ 970 PACC02_Systemstatus 0;
BA_ "GenSigSendType" SG_ 970 PACC02_Systemstatus_Anzeige 0;
BA_ "GenSigSwitchedByIgnition" SG_ 970 PACC02_Systemstatus_Anzeige 0;
BA_ "GenSigSendType" SG_ 970 PACC02_Uebernahmeaufforderung 0;
BA_ "GenSigSendType" SG_ 970 PACC02_Vorausschaugeschw 0;
BA_ "GenSigStartValue" SG_ 970 PACC02_Vorausschaugeschw 1023;
BA_ "GenSigSendType" SG_ 2463978731 PACC02_Event_aktiv 0;
BA_ "GenSigSwitchedByIgnition" SG_ 2463978731 PACC02_Event_aktiv 0;
BA_ "GenSigSendType" SG_ 2463978731 PACC02_Geschw_Vorausschau 0;
BA_ "GenSigSwitchedByIgnition" SG_ 2463978731 PACC02_Geschw_Vorausschau 0;
BA_ "GenSigSendType" SG_ 2463978731 PACC02_Hinweis_Geschw 0;
BA_ "GenSigSwitchedByIgnition" SG_ 2463978731 PACC02_Hinweis_Geschw 0;
BA_ "GenSigSendType" SG_ 2463978731 PACC02_Offset_aktiv 0;
BA_ "GenSigSwitchedByIgnition" SG_ 2463978731 PACC02_Offset_aktiv 0;
BA_ "GenSigSendType" SG_ 2463978731 PACC02_Offset_Anzeige 0;
BA_ "GenSigSwitchedByIgnition" SG_ 2463978731 PACC02_Offset_Anzeige 0;
BA_ "GenSigSendType" SG_ 908 PACC_Automode 0;
BA_ "GenSigStartValue" SG_ 908 PACC_Automode 1;
BA_ "GenSigSwitchedByIgnition" SG_ 908 PACC_Automode 0;
BA_ "GenSigSendType" SG_ 908 PACC_Durchschnittsgeschw 0;
BA_ "GenSigSendType" SG_ 908 PACC_naechstes_Event 0;
BA_ "GenSigSendType" SG_ 908 PACC_Offset 0;
BA_ "GenSigStartValue" SG_ 908 PACC_Offset 255;
BA_ "GenSigSendType" SG_ 908 PACC_Segelanteil 0;
BA_ "GenSigSendType" SG_ 908 PACC_Sollgeschwindigkeit 0;
BA_ "GenSigSendType" SG_ 908 PACC_Systemstatus 0;
BA_ "GenSigSendType" SG_ 908 PACC_Sytemstatus_Anzeige 0;
BA_ "GenSigSwitchedByIgnition" SG_ 908 PACC_Sytemstatus_Anzeige 0;
BA_ "GenSigSendType" SG_ 908 PACC_Uebernahmeaufforderung 0;
BA_ "GenSigSendType" SG_ 908 PACC_Vorausschaugeschw 0;
BA_ "GenSigStartValue" SG_ 908 PACC_Vorausschaugeschw 1023;
BA_ "GenSigSendType" SG_ 696 PADM_Warnmeldung_Prio2 0;
BA_ "GenSigSwitchedByIgnition" SG_ 696 PADM_Warnmeldung_Prio2 0;
BA_ "GenSigSendType" SG_ 872 PDC2_Tonausgabe_Front 3;
BA_ "GenSigSendType" SG_ 872 PDC2_Tonausgabe_Heck 3;
BA_ "GenSigSendType" SG_ 872 PH2_Abschaltursache 3;
BA_ "GenSigSendType" SG_ 872 PH2_Anf_Audioabsenkung 3;
BA_ "GenSigSendType" SG_ 872 PH2_Anf_Verdeck 3;
BA_ "GenSigSendType" SG_ 872 PH2_defekt 3;
BA_ "GenSigSendType" SG_ 872 PH2_Display_Kundenwunsch 3;
BA_ "GenSigSendType" SG_ 872 PH2_Frequenz_hinten 3;
BA_ "GenSigSendType" SG_ 872 PH2_Frequenz_vorn 3;
BA_ "GenSigSendType" SG_ 872 PH2_gestoert 3;
BA_ "GenSigSendType" SG_ 872 PH2_Lautstaerke_hinten 3;
BA_ "GenSigSendType" SG_ 872 PH2_Lautstaerke_vorn 3;
BA_ "GenSigSendType" SG_ 872 PH2_nachtr_Stopp_An 3;
BA_ "GenSigSendType" SG_ 872 PH2_Opt_Anz_H_Hindernis 3;
BA_ "GenSigSendType" SG_ 872 PH2_Opt_Anz_V_Hindernis 3;
BA_ "GenSigSendType" SG_ 872 PH2_Opt_Anzeige_H_ein 3;
BA_ "GenSigSendType" SG_ 872 PH2_Opt_Anzeige_V_ein 3;
BA_ "GenSigSendType" SG_ 872 PH2_StartStopp_Info 3;
BA_ "GenSigSendType" SG_ 872 PH2_Stoermeldung 3;
BA_ "GenSigSendType" SG_ 872 PH2_Systemzustand 3;
BA_ "GenSigSendType" SG_ 872 PH2_Taster 3;
BA_ "Fehlerwert" SG_ 872 PH2_Taster 3;
BA_ "GenSigSendType" SG_ 872 PH2_Tongeber_H_aktiv 3;
BA_ "GenSigSendType" SG_ 872 PH2_Tongeber_H_verfuegbar 3;
BA_ "GenSigSendType" SG_ 872 PH2_Tongeber_mute 3;
BA_ "GenSigSendType" SG_ 872 PH2_Tongeber_V_aktiv 3;
BA_ "GenSigSendType" SG_ 872 PH2_Visualisierung 3;
BA_ "GenSigStartValue" SG_ 872 PH2_Visualisierung 6;
BA_ "Fehlerwert" SG_ 872 PH2_Visualisierung 7;
BA_ "GenSigSendType" SG_ 2463978617 PH2_Aufschaltursache 3;
BA_ "GenSigSendType" SG_ 2463978617 PH2_Verschmutzungsmeldung 3;
BA_ "GenSigSendType" SG_ 2463978617 PH2_WAH_Meldung 3;
BA_ "GenSigSendType" SG_ 1175 PDC_Tonausgabe_Front 3;
BA_ "GenSigSendType" SG_ 1175 PDC_Tonausgabe_Heck 3;
BA_ "GenSigSendType" SG_ 1175 PH_Abschaltursache 3;
BA_ "GenSigSendType" SG_ 1175 PH_Anf_Audioabsenkung 3;
BA_ "GenSigSendType" SG_ 1175 PH_Anf_Verdeck 3;
BA_ "GenSigSendType" SG_ 1175 PH_defekt 3;
BA_ "GenSigSendType" SG_ 1175 PH_Display_Kundenwunsch 3;
BA_ "GenSigSendType" SG_ 1175 PH_Frequenz_hinten 3;
BA_ "GenSigSendType" SG_ 1175 PH_Frequenz_vorn 3;
BA_ "GenSigSendType" SG_ 1175 PH_gestoert 3;
BA_ "GenSigSendType" SG_ 1175 PH_Lautstaerke_hinten 3;
BA_ "GenSigSendType" SG_ 1175 PH_Lautstaerke_vorn 3;
BA_ "GenSigSendType" SG_ 1175 PH_nachtr_Stopp_Anf 3;
BA_ "GenSigSendType" SG_ 1175 PH_Opt_Anz_H_Hindernis 3;
BA_ "GenSigSendType" SG_ 1175 PH_Opt_Anz_V_Hindernis 3;
BA_ "GenSigSendType" SG_ 1175 PH_Opt_Anzeige_H_ein 3;
BA_ "GenSigSendType" SG_ 1175 PH_Opt_Anzeige_V_ein 3;
BA_ "GenSigSendType" SG_ 1175 PH_StartStopp_Info 3;
BA_ "GenSigSendType" SG_ 1175 PH_Stoermeldung 3;
BA_ "GenSigSendType" SG_ 1175 PH_Systemzustand 3;
BA_ "GenSigSendType" SG_ 1175 PH_Taster 3;
BA_ "Fehlerwert" SG_ 1175 PH_Taster 3;
BA_ "GenSigSendType" SG_ 1175 PH_Tongeber_H_aktiv 3;
BA_ "GenSigSendType" SG_ 1175 PH_Tongeber_H_verfuegbar 3;
BA_ "GenSigSendType" SG_ 1175 PH_Tongeber_mute 3;
BA_ "GenSigSendType" SG_ 1175 PH_Tongeber_V_aktiv 3;
BA_ "GenSigSendType" SG_ 1175 PH_Visualisierung 3;
BA_ "GenSigStartValue" SG_ 1175 PH_Visualisierung 6;
BA_ "Fehlerwert" SG_ 1175 PH_Visualisierung 7;
BA_ "GenSigSendType" SG_ 1175 PLA_Anf_Aufschaltung_RVC 3;
BA_REL_ "GenSigTimeoutTime" BU_SG_REL_ CGS SG_ 2600468496 NM_Gateway_SNI 2000;
BA_REL_ "GenSigTimeoutTime" BU_SG_REL_ CGS SG_ 2600468496 NM_Gateway_CBV_CRI 2000;
BA_REL_ "GenSigTimeoutTime" BU_SG_REL_ CGS SG_ 2600468496 NM_Gateway_CAB 2000;
BA_REL_ "GenSigTimeoutTime" BU_SG_REL_ CGS SG_ 2600468507 NM_HUD_SNI 2000;
BA_REL_ "GenSigTimeoutTime" BU_SG_REL_ CGS SG_ 2600468507 NM_HUD_CBV_CRI 2000;
BA_REL_ "GenSigTimeoutTime" BU_SG_REL_ CGS SG_ 2600468507 NM_HUD_CAB 2000;
BA_REL_ "GenSigTimeoutTime" BU_SG_REL_ CGS SG_ 2600468500 NM_Kombi_SNI 2000;
BA_REL_ "GenSigTimeoutTime" BU_SG_REL_ CGS SG_ 2600468500 NM_Kombi_CBV_CRI 2000;
BA_REL_ "GenSigTimeoutTime" BU_SG_REL_ CGS SG_ 2600468500 NM_Kombi_CAB 2000;
BA_REL_ "GenSigTimeoutTime" BU_SG_REL_ Gateway SG_ 2600468507 NM_HUD_SNI 2000;
BA_REL_ "GenSigTimeoutTime" BU_SG_REL_ Gateway SG_ 2600468507 NM_HUD_CBV_AWB 2000;
BA_REL_ "GenSigTimeoutTime" BU_SG_REL_ Gateway SG_ 2600468507 NM_HUD_CBV_CRI 2000;
BA_REL_ "GenSigTimeoutTime" BU_SG_REL_ Gateway SG_ 2600468507 NM_HUD_Car_WakeUp 2000;
BA_REL_ "GenSigTimeoutTime" BU_SG_REL_ Gateway SG_ 2600468507 NM_HUD_CAB 2000;
BA_REL_ "GenSigTimeoutTime" BU_SG_REL_ Gateway SG_ 2600468500 NM_Kombi_SNI 2000;
BA_REL_ "GenSigTimeoutTime" BU_SG_REL_ Gateway SG_ 2600468500 NM_Kombi_CBV_AWB 2000;
BA_REL_ "GenSigTimeoutTime" BU_SG_REL_ Gateway SG_ 2600468500 NM_Kombi_CBV_CRI 2000;
BA_REL_ "GenSigTimeoutTime" BU_SG_REL_ Gateway SG_ 2600468500 NM_Kombi_Car_Wakeup 2000;
BA_REL_ "GenSigTimeoutTime" BU_SG_REL_ Gateway SG_ 2600468500 NM_Kombi_CAB 2000;
BA_REL_ "GenSigTimeoutTime" BU_SG_REL_ Gateway SG_ 2600468563 NM_Waehlhebel_SNI 2000;
BA_REL_ "GenSigTimeoutTime" BU_SG_REL_ Gateway SG_ 2600468563 NM_Waehlhebel_CBV_AWB 2000;
BA_REL_ "GenSigTimeoutTime" BU_SG_REL_ Gateway SG_ 2600468563 NM_Waehlhebel_CBV_CRI 2000;
BA_REL_ "GenSigTimeoutTime" BU_SG_REL_ Gateway SG_ 2600468563 NM_Waehlhebel_Car_Wakeup 2000;
BA_REL_ "GenSigTimeoutTime" BU_SG_REL_ Gateway SG_ 2600468563 NM_Waehlhebel_CAB 2000;
BA_REL_ "GenSigTimeoutTime" BU_SG_REL_ Gateway_PAG SG_ 2600468507 NM_HUD_SNI 2000;
BA_REL_ "GenSigTimeoutTime" BU_SG_REL_ Gateway_PAG SG_ 2600468507 NM_HUD_CBV_AWB 2000;
BA_REL_ "GenSigTimeoutTime" BU_SG_REL_ Gateway_PAG SG_ 2600468507 NM_HUD_CBV_CRI 2000;
BA_REL_ "GenSigTimeoutTime" BU_SG_REL_ Gateway_PAG SG_ 2600468507 NM_HUD_CAB 2000;
BA_REL_ "GenSigTimeoutTime" BU_SG_REL_ Gateway_PAG SG_ 2600468500 NM_Kombi_SNI 2000;
BA_REL_ "GenSigTimeoutTime" BU_SG_REL_ Gateway_PAG SG_ 2600468500 NM_Kombi_CBV_AWB 2000;
BA_REL_ "GenSigTimeoutTime" BU_SG_REL_ Gateway_PAG SG_ 2600468500 NM_Kombi_CBV_CRI 2000;
BA_REL_ "GenSigTimeoutTime" BU_SG_REL_ Gateway_PAG SG_ 2600468500 NM_Kombi_Car_Wakeup 2000;
BA_REL_ "GenSigTimeoutTime" BU_SG_REL_ Gateway_PAG SG_ 2600468500 NM_Kombi_CAB 2000;
BA_REL_ "GenSigTimeoutTime" BU_SG_REL_ Gateway_PAG SG_ 2600468563 NM_Waehlhebel_SNI 2000;
BA_REL_ "GenSigTimeoutTime" BU_SG_REL_ Gateway_PAG SG_ 2600468563 NM_Waehlhebel_CBV_AWB 2000;
BA_REL_ "GenSigTimeoutTime" BU_SG_REL_ Gateway_PAG SG_ 2600468563 NM_Waehlhebel_CBV_CRI 2000;
BA_REL_ "GenSigTimeoutTime" BU_SG_REL_ Gateway_PAG SG_ 2600468563 NM_Waehlhebel_Car_Wakeup 2000;
BA_REL_ "GenSigTimeoutTime" BU_SG_REL_ Gateway_PAG SG_ 2600468563 NM_Waehlhebel_CAB 2000;
BA_REL_ "GenSigTimeoutTime" BU_SG_REL_ HUD SG_ 1635 BEM_02_Abschaltstufen 1000;
BA_REL_ "GenSigTimeoutTime" BU_SG_REL_ HUD SG_ 1155 Mo_Powermeter_Grenze 3200;
BA_REL_ "GenSigTimeoutTime" BU_SG_REL_ HUD SG_ 1155 MO_Powermeter_Charge_Grenze 3200;
BA_REL_ "GenSigTimeoutTime" BU_SG_REL_ HUD SG_ 1155 MO_Powermeter_Grenze_strategisch 3200;
BA_REL_ "GenSigTimeoutTime" BU_SG_REL_ HUD SG_ 878 RML_Status_Anzeige_Range 800;
BA_REL_ "GenSigTimeoutTime" BU_SG_REL_ HUD SG_ 878 RML_vMax_Range 800;
BA_REL_ "GenSigTimeoutTime" BU_SG_REL_ HUD SG_ 1696 NV_Symbol 2000;
BA_REL_ "GenSigTimeoutTime" BU_SG_REL_ HUD SG_ 1696 NV_Symbol_Tierwarnung 2000;
BA_REL_ "GenSigTimeoutTime" BU_SG_REL_ HUD SG_ 1696 NV_LED_Leiste 2000;
BA_REL_ "GenSigTimeoutTime" BU_SG_REL_ HUD SG_ 2600468496 NM_Gateway_SNI 2000;
BA_REL_ "GenSigTimeoutTime" BU_SG_REL_ HUD SG_ 2600468496 NM_Gateway_CBV_CRI 2000;
BA_REL_ "GenSigTimeoutTime" BU_SG_REL_ HUD SG_ 2600468496 NM_Gateway_CAB 2000;
BA_REL_ "GenSigTimeoutTime" BU_SG_REL_ HUD SG_ 2600468507 NM_HUD_SNI 2000;
BA_REL_ "GenSigTimeoutTime" BU_SG_REL_ HUD SG_ 2600468507 NM_HUD_CBV_CRI 2000;
BA_REL_ "GenSigTimeoutTime" BU_SG_REL_ HUD SG_ 2600468507 NM_HUD_CAB 2000;
BA_REL_ "GenSigTimeoutTime" BU_SG_REL_ HUD SG_ 2600468500 NM_Kombi_SNI 2000;
BA_REL_ "GenSigTimeoutTime" BU_SG_REL_ HUD SG_ 2600468500 NM_Kombi_CBV_CRI 2000;
BA_REL_ "GenSigTimeoutTime" BU_SG_REL_ HUD SG_ 2600468500 NM_Kombi_CAB 2000;
BA_REL_ "GenSigTimeoutTime" BU_SG_REL_ HUD SG_ 2600468563 NM_Waehlhebel_SNI 2000;
BA_REL_ "GenSigTimeoutTime" BU_SG_REL_ HUD SG_ 2600468563 NM_Waehlhebel_CBV_CRI 2000;
BA_REL_ "GenSigTimeoutTime" BU_SG_REL_ HUD SG_ 2600468563 NM_Waehlhebel_CAB 2000;
BA_REL_ "GenSigTimeoutTime" BU_SG_REL_ HUD SG_ 913 OBD_Warm_Up_Cycle 5000;
BA_REL_ "GenSigTimeoutTime" BU_SG_REL_ HUD SG_ 2589283656 ORU_Status 5000;
BA_REL_ "GenSigTimeoutTime" BU_SG_REL_ HUD SG_ 970 PACC02_Systemstatus_Anzeige 1000;
BA_REL_ "GenSigTimeoutTime" BU_SG_REL_ HUD SG_ 970 PACC02_Automode 1000;
BA_REL_ "GenSigTimeoutTime" BU_SG_REL_ HUD SG_ 970 PACC02_Vorausschaugeschw 1000;
BA_REL_ "GenSigTimeoutTime" BU_SG_REL_ HUD SG_ 970 PACC02_Sollgeschwindigkeit 1000;
BA_REL_ "GenSigTimeoutTime" BU_SG_REL_ HUD SG_ 970 PACC02_naechstes_Event 1000;
BA_REL_ "GenSigTimeoutTime" BU_SG_REL_ HUD SG_ 2463978731 PACC02_Geschw_Vorausschau 1000;
BA_REL_ "GenSigTimeoutTime" BU_SG_REL_ HUD SG_ 2463978731 PACC02_Event_aktiv 1000;
BA_REL_ "GenSigTimeoutTime" BU_SG_REL_ HUD SG_ 2463978731 PACC02_Offset_aktiv 1000;
BA_REL_ "GenSigTimeoutTime" BU_SG_REL_ HUD SG_ 2463978731 PACC02_Offset_Anzeige 1000;
BA_REL_ "GenSigTimeoutTime" BU_SG_REL_ HUD SG_ 908 PACC_Sytemstatus_Anzeige 1000;
BA_REL_ "GenSigTimeoutTime" BU_SG_REL_ HUD SG_ 908 PACC_Automode 1000;
BA_REL_ "GenSigTimeoutTime" BU_SG_REL_ HUD SG_ 908 PACC_Systemstatus 1000;
BA_REL_ "GenSigTimeoutTime" BU_SG_REL_ HUD SG_ 908 PACC_Sollgeschwindigkeit 1000;
BA_REL_ "GenSigTimeoutTime" BU_SG_REL_ Kombi SG_ 1635 BEM_02_Abschaltstufen 1000;
BA_REL_ "GenSigTimeoutTime" BU_SG_REL_ Kombi SG_ 1635 BEM_Generatordiagnose 1000;
BA_REL_ "GenSigTimeoutTime" BU_SG_REL_ Kombi SG_ 1635 BEM_Ladezustand 1000;
BA_REL_ "GenSigTimeoutTime" BU_SG_REL_ Kombi SG_ 1635 BEM_Batteriediagnose 1000;
BA_REL_ "GenSigTimeoutTime" BU_SG_REL_ Kombi SG_ 1635 NVEM_Batterie_Service 1000;
BA_REL_ "GenSigTimeoutTime" BU_SG_REL_ Kombi SG_ 1155 Mo_Powermeter_Grenze 3200;
BA_REL_ "GenSigTimeoutTime" BU_SG_REL_ Kombi SG_ 1155 MO_Text_Aktivierung_Antrieb 3200;
BA_REL_ "GenSigTimeoutTime" BU_SG_REL_ Kombi SG_ 1155 MO_Powermeter_Inszenierung_aktiv 3200;
BA_REL_ "GenSigTimeoutTime" BU_SG_REL_ Kombi SG_ 1155 MO_Powermeter_Charge_Grenze 3200;
BA_REL_ "GenSigTimeoutTime" BU_SG_REL_ Kombi SG_ 1155 MO_Powermeter_Grenze_strategisch 3200;
BA_REL_ "GenSigTimeoutTime" BU_SG_REL_ Kombi SG_ 1155 MO_Powermeter_untere_E_Grenze 3200;
BA_REL_ "GenSigTimeoutTime" BU_SG_REL_ Kombi SG_ 1155 MO_Powermeter_obere_E_Grenze 3200;
BA_REL_ "GenSigTimeoutTime" BU_SG_REL_ Kombi SG_ 878 RML_Status_Anzeige_Range 800;
BA_REL_ "GenSigTimeoutTime" BU_SG_REL_ Kombi SG_ 878 RML_vMax_Range 800;
BA_REL_ "GenSigTimeoutTime" BU_SG_REL_ Kombi SG_ 2527679823 MO_WI_StWarnVolWa 1600;
BA_REL_ "GenSigTimeoutTime" BU_SG_REL_ Kombi SG_ 688 MO_Verbrauch_EM_Ges 500;
BA_REL_ "GenSigTimeoutTime" BU_SG_REL_ Kombi SG_ 688 MO_Verbrauch_EM_Ges_Ueberlauf 500;
BA_REL_ "GenSigTimeoutTime" BU_SG_REL_ Kombi SG_ 688 MO_Rekuperation_Ges_EM 500;
BA_REL_ "GenSigTimeoutTime" BU_SG_REL_ Kombi SG_ 688 MO_Rekuperation_EM_Ges_Ueberlauf 500;
BA_REL_ "GenSigTimeoutTime" BU_SG_REL_ Kombi SG_ 689 TME_Verbrauch_gesamt_Ueberlauf 500;
BA_REL_ "GenSigTimeoutTime" BU_SG_REL_ Kombi SG_ 689 TME_Verbrauch_gesamt 500;
BA_REL_ "GenSigTimeoutTime" BU_SG_REL_ Kombi SG_ 1284 MVK_MV_Netz_Warnungen 1000;
BA_REL_ "GenSigTimeoutTime" BU_SG_REL_ Kombi SG_ 2527679512 ND_Fuelstation_detected 2000;
BA_REL_ "GenSigTimeoutTime" BU_SG_REL_ Kombi SG_ 1696 NV_aktiv 2000;
BA_REL_ "GenSigTimeoutTime" BU_SG_REL_ Kombi SG_ 1696 NV_Texte 2000;
BA_REL_ "GenSigTimeoutTime" BU_SG_REL_ Kombi SG_ 1696 NV_Gong 2000;
BA_REL_ "GenSigTimeoutTime" BU_SG_REL_ Kombi SG_ 1696 NV_Symbol 2000;
BA_REL_ "GenSigTimeoutTime" BU_SG_REL_ Kombi SG_ 1696 NV_Hinweise 2000;
BA_REL_ "GenSigTimeoutTime" BU_SG_REL_ Kombi SG_ 1696 NV_Piktogramm_aktiv 2000;
BA_REL_ "GenSigTimeoutTime" BU_SG_REL_ Kombi SG_ 1696 NV_Akustik_deaktiviert_Icon 2000;
BA_REL_ "GenSigTimeoutTime" BU_SG_REL_ Kombi SG_ 1696 NV_FGM_deaktiviert_Icon 2000;
BA_REL_ "GenSigTimeoutTime" BU_SG_REL_ Kombi SG_ 1696 NV_Symbol_Tierwarnung 2000;
BA_REL_ "GenSigTimeoutTime" BU_SG_REL_ Kombi SG_ 1696 NV_LED_Leiste 2000;
BA_REL_ "GenSigTimeoutTime" BU_SG_REL_ Kombi SG_ 1696 NV_Akt_Status_MMI 2000;
BA_REL_ "GenSigTimeoutTime" BU_SG_REL_ Kombi SG_ 1696 NV_AnforderungBildaufschaltung 2000;
BA_REL_ "GenSigTimeoutTime" BU_SG_REL_ Kombi SG_ 2600468496 NM_Gateway_SNI 2000;
BA_REL_ "GenSigTimeoutTime" BU_SG_REL_ Kombi SG_ 2600468496 NM_Gateway_CBV_CRI 2000;
BA_REL_ "GenSigTimeoutTime" BU_SG_REL_ Kombi SG_ 2600468496 NM_Gateway_CAB 2000;
BA_REL_ "GenSigTimeoutTime" BU_SG_REL_ Kombi SG_ 2600468507 NM_HUD_SNI 2000;
BA_REL_ "GenSigTimeoutTime" BU_SG_REL_ Kombi SG_ 2600468507 NM_HUD_CBV_CRI 2000;
BA_REL_ "GenSigTimeoutTime" BU_SG_REL_ Kombi SG_ 2600468507 NM_HUD_CAB 2000;
BA_REL_ "GenSigTimeoutTime" BU_SG_REL_ Kombi SG_ 2600468500 NM_Kombi_SNI 2000;
BA_REL_ "GenSigTimeoutTime" BU_SG_REL_ Kombi SG_ 2600468500 NM_Kombi_CBV_CRI 2000;
BA_REL_ "GenSigTimeoutTime" BU_SG_REL_ Kombi SG_ 2600468500 NM_Kombi_CAB 2000;
BA_REL_ "GenSigTimeoutTime" BU_SG_REL_ Kombi SG_ 2600468563 NM_Waehlhebel_SNI 2000;
BA_REL_ "GenSigTimeoutTime" BU_SG_REL_ Kombi SG_ 2600468563 NM_Waehlhebel_CBV_CRI 2000;
BA_REL_ "GenSigTimeoutTime" BU_SG_REL_ Kombi SG_ 2600468563 NM_Waehlhebel_CAB 2000;
BA_REL_ "GenSigTimeoutTime" BU_SG_REL_ Kombi SG_ 2527679508 NVEM_06_CRC 1000;
BA_REL_ "GenSigTimeoutTime" BU_SG_REL_ Kombi SG_ 2527679508 NVEM_06_BZ 1000;
BA_REL_ "GenSigTimeoutTime" BU_SG_REL_ Kombi SG_ 2527679508 NVEM_Bordnetzdiagnose 1000;
BA_REL_ "GenSigTimeoutTime" BU_SG_REL_ Kombi SG_ 913 OBD_Warm_Up_Cycle 5000;
BA_REL_ "GenSigTimeoutTime" BU_SG_REL_ Kombi SG_ 2589283656 ORU_Warnung 5000;
BA_REL_ "GenSigTimeoutTime" BU_SG_REL_ Kombi SG_ 872 PH2_Stoermeldung 1000;
BA_REL_ "GenSigTimeoutTime" BU_SG_REL_ Kombi SG_ 2463978617 PH2_Verschmutzungsmeldung 5000;
BA_REL_ "GenSigTimeoutTime" BU_SG_REL_ Kombi SG_ 2463978617 PH2_WAH_Meldung 5000;
BA_REL_ "GenSigTimeoutTime" BU_SG_REL_ Kombi SG_ 1175 PDC_Tonausgabe_Front 1000;
BA_REL_ "GenSigTimeoutTime" BU_SG_REL_ Kombi SG_ 1175 PDC_Tonausgabe_Heck 1000;
BA_REL_ "GenSigTimeoutTime" BU_SG_REL_ Kombi SG_ 1175 PH_Frequenz_hinten 1000;
BA_REL_ "GenSigTimeoutTime" BU_SG_REL_ Kombi SG_ 1175 PH_Lautstaerke_hinten 1000;
BA_REL_ "GenSigTimeoutTime" BU_SG_REL_ Kombi SG_ 1175 PH_Frequenz_vorn 1000;
BA_REL_ "GenSigTimeoutTime" BU_SG_REL_ Kombi SG_ 1175 PH_Lautstaerke_vorn 1000;
BA_REL_ "GenSigTimeoutTime" BU_SG_REL_ Kombi SG_ 1175 PH_Stoermeldung 1000;
BA_REL_ "GenSigTimeoutTime" BU_SG_REL_ Kombi_LB SG_ 1635 BEM_02_Abschaltstufen 1000;
BA_REL_ "GenSigTimeoutTime" BU_SG_REL_ Kombi_LB SG_ 1635 BEM_Generatordiagnose 1000;
BA_REL_ "GenSigTimeoutTime" BU_SG_REL_ Kombi_LB SG_ 1635 BEM_Ladezustand 1000;
BA_REL_ "GenSigTimeoutTime" BU_SG_REL_ Kombi_LB SG_ 1635 BEM_Batteriediagnose 1000;
BA_REL_ "GenSigTimeoutTime" BU_SG_REL_ Kombi_LB SG_ 1635 NVEM_Batterie_Service 1000;
BA_REL_ "GenSigTimeoutTime" BU_SG_REL_ Kombi_LB SG_ 1155 Mo_Powermeter_Grenze 3200;
BA_REL_ "GenSigTimeoutTime" BU_SG_REL_ Kombi_LB SG_ 1155 MO_Text_Aktivierung_Antrieb 3200;
BA_REL_ "GenSigTimeoutTime" BU_SG_REL_ Kombi_LB SG_ 1155 MO_Powermeter_Inszenierung_aktiv 3200;
BA_REL_ "GenSigTimeoutTime" BU_SG_REL_ Kombi_LB SG_ 1155 MO_Powermeter_Charge_Grenze 3200;
BA_REL_ "GenSigTimeoutTime" BU_SG_REL_ Kombi_LB SG_ 1155 MO_Powermeter_Grenze_strategisch 3200;
BA_REL_ "GenSigTimeoutTime" BU_SG_REL_ Kombi_LB SG_ 1155 MO_Powermeter_untere_E_Grenze 3200;
BA_REL_ "GenSigTimeoutTime" BU_SG_REL_ Kombi_LB SG_ 1155 MO_Powermeter_obere_E_Grenze 3200;
BA_REL_ "GenSigTimeoutTime" BU_SG_REL_ Kombi_LB SG_ 878 RML_Status_Anzeige_Range 800;
BA_REL_ "GenSigTimeoutTime" BU_SG_REL_ Kombi_LB SG_ 878 RML_vMax_Range 800;
BA_REL_ "GenSigTimeoutTime" BU_SG_REL_ Kombi_LB SG_ 688 MO_Verbrauch_EM_Ges 500;
BA_REL_ "GenSigTimeoutTime" BU_SG_REL_ Kombi_LB SG_ 688 MO_Verbrauch_EM_Ges_Ueberlauf 500;
BA_REL_ "GenSigTimeoutTime" BU_SG_REL_ Kombi_LB SG_ 688 MO_Rekuperation_Ges_EM 500;
BA_REL_ "GenSigTimeoutTime" BU_SG_REL_ Kombi_LB SG_ 688 MO_Rekuperation_EM_Ges_Ueberlauf 500;
BA_REL_ "GenSigTimeoutTime" BU_SG_REL_ Kombi_LB SG_ 689 TME_Verbrauch_gesamt_Ueberlauf 500;
BA_REL_ "GenSigTimeoutTime" BU_SG_REL_ Kombi_LB SG_ 689 TME_Verbrauch_gesamt 500;
BA_REL_ "GenSigTimeoutTime" BU_SG_REL_ Kombi_LB SG_ 2527679512 ND_Fuelstation_detected 2000;
BA_REL_ "GenSigTimeoutTime" BU_SG_REL_ Kombi_LB SG_ 2600468496 NM_Gateway_SNI 2000;
BA_REL_ "GenSigTimeoutTime" BU_SG_REL_ Kombi_LB SG_ 2600468496 NM_Gateway_CBV_CRI 2000;
BA_REL_ "GenSigTimeoutTime" BU_SG_REL_ Kombi_LB SG_ 2600468496 NM_Gateway_CAB 2000;
BA_REL_ "GenSigTimeoutTime" BU_SG_REL_ Kombi_LB SG_ 2600468507 NM_HUD_SNI 2000;
BA_REL_ "GenSigTimeoutTime" BU_SG_REL_ Kombi_LB SG_ 2600468507 NM_HUD_CBV_CRI 2000;
BA_REL_ "GenSigTimeoutTime" BU_SG_REL_ Kombi_LB SG_ 2600468507 NM_HUD_CAB 2000;
BA_REL_ "GenSigTimeoutTime" BU_SG_REL_ Kombi_LB SG_ 2600468563 NM_Waehlhebel_SNI 2000;
BA_REL_ "GenSigTimeoutTime" BU_SG_REL_ Kombi_LB SG_ 2600468563 NM_Waehlhebel_CBV_CRI 2000;
BA_REL_ "GenSigTimeoutTime" BU_SG_REL_ Kombi_LB SG_ 2600468563 NM_Waehlhebel_CAB 2000;
BA_REL_ "GenSigTimeoutTime" BU_SG_REL_ Kombi_LB SG_ 2527679508 NVEM_06_CRC 1000;
BA_REL_ "GenSigTimeoutTime" BU_SG_REL_ Kombi_LB SG_ 2527679508 NVEM_06_BZ 1000;
BA_REL_ "GenSigTimeoutTime" BU_SG_REL_ Kombi_LB SG_ 2527679508 NVEM_Bordnetzdiagnose 1000;
BA_REL_ "GenSigTimeoutTime" BU_SG_REL_ Kombi_LB SG_ 2589283656 ORU_Warnung 5000;
BA_REL_ "GenSigTimeoutTime" BU_SG_REL_ Kombi_LB SG_ 872 PH2_Stoermeldung 1000;
BA_REL_ "GenSigTimeoutTime" BU_SG_REL_ Kombi_LB SG_ 2463978617 PH2_Verschmutzungsmeldung 5000;
BA_REL_ "GenSigTimeoutTime" BU_SG_REL_ Kombi_LB SG_ 2463978617 PH2_WAH_Meldung 5000;
BA_REL_ "GenSigTimeoutTime" BU_SG_REL_ Kombi_LB SG_ 1175 PDC_Tonausgabe_Front 1000;
BA_REL_ "GenSigTimeoutTime" BU_SG_REL_ Kombi_LB SG_ 1175 PDC_Tonausgabe_Heck 1000;
BA_REL_ "GenSigTimeoutTime" BU_SG_REL_ Kombi_LB SG_ 1175 PH_Frequenz_hinten 1000;
BA_REL_ "GenSigTimeoutTime" BU_SG_REL_ Kombi_LB SG_ 1175 PH_Lautstaerke_hinten 1000;
BA_REL_ "GenSigTimeoutTime" BU_SG_REL_ Kombi_LB SG_ 1175 PH_Frequenz_vorn 1000;
BA_REL_ "GenSigTimeoutTime" BU_SG_REL_ Kombi_LB SG_ 1175 PH_Lautstaerke_vorn 1000;
BA_REL_ "GenSigTimeoutTime" BU_SG_REL_ Kombi_LB SG_ 1175 PH_Stoermeldung 1000;
BA_REL_ "GenSigTimeoutTime" BU_SG_REL_ Kombi_PAG SG_ 1635 BEM_02_Abschaltstufen 1000;
BA_REL_ "GenSigTimeoutTime" BU_SG_REL_ Kombi_PAG SG_ 1635 BEM_Generatordiagnose 1000;
BA_REL_ "GenSigTimeoutTime" BU_SG_REL_ Kombi_PAG SG_ 1635 BEM_Ladezustand 1000;
BA_REL_ "GenSigTimeoutTime" BU_SG_REL_ Kombi_PAG SG_ 1635 BEM_Batteriediagnose 1000;
BA_REL_ "GenSigTimeoutTime" BU_SG_REL_ Kombi_PAG SG_ 1635 BEM_UBDM 1000;
BA_REL_ "GenSigTimeoutTime" BU_SG_REL_ Kombi_PAG SG_ 1635 NVEM_Batterie_Service 1000;
BA_REL_ "GenSigTimeoutTime" BU_SG_REL_ Kombi_PAG SG_ 1155 Mo_Powermeter_Grenze 3200;
BA_REL_ "GenSigTimeoutTime" BU_SG_REL_ Kombi_PAG SG_ 1155 MO_Powermeter_Charge_Grenze 3200;
BA_REL_ "GenSigTimeoutTime" BU_SG_REL_ Kombi_PAG SG_ 1155 MO_Powermeter_Grenze_strategisch 3200;
BA_REL_ "GenSigTimeoutTime" BU_SG_REL_ Kombi_PAG SG_ 1155 MO_Powermeter_untere_E_Grenze 3200;
BA_REL_ "GenSigTimeoutTime" BU_SG_REL_ Kombi_PAG SG_ 1155 MO_Powermeter_obere_E_Grenze 3200;
BA_REL_ "GenSigTimeoutTime" BU_SG_REL_ Kombi_PAG SG_ 878 RML_Status_Anzeige_Range 800;
BA_REL_ "GenSigTimeoutTime" BU_SG_REL_ Kombi_PAG SG_ 878 RML_vMax_Range 800;
BA_REL_ "GenSigTimeoutTime" BU_SG_REL_ Kombi_PAG SG_ 2527679823 MO_WI_FlgInfoTmpLvlVolWa 1600;
BA_REL_ "GenSigTimeoutTime" BU_SG_REL_ Kombi_PAG SG_ 2527679823 MO_WI_StWarnVolWa 1600;
BA_REL_ "GenSigTimeoutTime" BU_SG_REL_ Kombi_PAG SG_ 688 MO_Verbrauch_EM_Ges 500;
BA_REL_ "GenSigTimeoutTime" BU_SG_REL_ Kombi_PAG SG_ 688 MO_Verbrauch_EM_Ges_Ueberlauf 500;
BA_REL_ "GenSigTimeoutTime" BU_SG_REL_ Kombi_PAG SG_ 688 MO_Rekuperation_Ges_EM 500;
BA_REL_ "GenSigTimeoutTime" BU_SG_REL_ Kombi_PAG SG_ 688 MO_Rekuperation_EM_Ges_Ueberlauf 500;
BA_REL_ "GenSigTimeoutTime" BU_SG_REL_ Kombi_PAG SG_ 1284 MVK_MV_Netz_Warnungen 1000;
BA_REL_ "GenSigTimeoutTime" BU_SG_REL_ Kombi_PAG SG_ 2527679512 ND_Fuelstation_detected 2000;
BA_REL_ "GenSigTimeoutTime" BU_SG_REL_ Kombi_PAG SG_ 1696 NV_aktiv 2000;
BA_REL_ "GenSigTimeoutTime" BU_SG_REL_ Kombi_PAG SG_ 1696 NV_Texte 2000;
BA_REL_ "GenSigTimeoutTime" BU_SG_REL_ Kombi_PAG SG_ 1696 NV_Gong 2000;
BA_REL_ "GenSigTimeoutTime" BU_SG_REL_ Kombi_PAG SG_ 1696 NV_Symbol 2000;
BA_REL_ "GenSigTimeoutTime" BU_SG_REL_ Kombi_PAG SG_ 1696 NV_Hinweise 2000;
BA_REL_ "GenSigTimeoutTime" BU_SG_REL_ Kombi_PAG SG_ 1696 NV_Piktogramm_aktiv 2000;
BA_REL_ "GenSigTimeoutTime" BU_SG_REL_ Kombi_PAG SG_ 1696 NV_Akustik_deaktiviert_Icon 2000;
BA_REL_ "GenSigTimeoutTime" BU_SG_REL_ Kombi_PAG SG_ 1696 NV_FGM_deaktiviert_Icon 2000;
BA_REL_ "GenSigTimeoutTime" BU_SG_REL_ Kombi_PAG SG_ 1696 NV_Symbol_Tierwarnung 2000;
BA_REL_ "GenSigTimeoutTime" BU_SG_REL_ Kombi_PAG SG_ 1696 NV_LED_Leiste 2000;
BA_REL_ "GenSigTimeoutTime" BU_SG_REL_ Kombi_PAG SG_ 1696 NV_Akt_Status_MMI 2000;
BA_REL_ "GenSigTimeoutTime" BU_SG_REL_ Kombi_PAG SG_ 2600468496 NM_Gateway_SNI 2000;
BA_REL_ "GenSigTimeoutTime" BU_SG_REL_ Kombi_PAG SG_ 2600468496 NM_Gateway_CBV_CRI 2000;
BA_REL_ "GenSigTimeoutTime" BU_SG_REL_ Kombi_PAG SG_ 2600468496 NM_Gateway_CAB 2000;
BA_REL_ "GenSigTimeoutTime" BU_SG_REL_ Kombi_PAG SG_ 2600468507 NM_HUD_SNI 2000;
BA_REL_ "GenSigTimeoutTime" BU_SG_REL_ Kombi_PAG SG_ 2600468507 NM_HUD_CBV_CRI 2000;
BA_REL_ "GenSigTimeoutTime" BU_SG_REL_ Kombi_PAG SG_ 2600468507 NM_HUD_CAB 2000;
BA_REL_ "GenSigTimeoutTime" BU_SG_REL_ Kombi_PAG SG_ 2600468500 NM_Kombi_SNI 2000;
BA_REL_ "GenSigTimeoutTime" BU_SG_REL_ Kombi_PAG SG_ 2600468500 NM_Kombi_CBV_CRI 2000;
BA_REL_ "GenSigTimeoutTime" BU_SG_REL_ Kombi_PAG SG_ 2600468500 NM_Kombi_CAB 2000;
BA_REL_ "GenSigTimeoutTime" BU_SG_REL_ Kombi_PAG SG_ 2600468563 NM_Waehlhebel_SNI 2000;
BA_REL_ "GenSigTimeoutTime" BU_SG_REL_ Kombi_PAG SG_ 2600468563 NM_Waehlhebel_CBV_CRI 2000;
BA_REL_ "GenSigTimeoutTime" BU_SG_REL_ Kombi_PAG SG_ 2600468563 NM_Waehlhebel_CAB 2000;
BA_REL_ "GenSigTimeoutTime" BU_SG_REL_ Kombi_PAG SG_ 2527679508 NVEM_06_CRC 1000;
BA_REL_ "GenSigTimeoutTime" BU_SG_REL_ Kombi_PAG SG_ 2527679508 NVEM_06_BZ 1000;
BA_REL_ "GenSigTimeoutTime" BU_SG_REL_ Kombi_PAG SG_ 2527679508 NVEM_Bordnetzdiagnose 1000;
BA_REL_ "GenSigTimeoutTime" BU_SG_REL_ Kombi_PAG SG_ 913 OBD_Warm_Up_Cycle 5000;
BA_REL_ "GenSigTimeoutTime" BU_SG_REL_ Kombi_PAG SG_ 2589283656 ORU_Warnung 5000;
BA_REL_ "GenSigTimeoutTime" BU_SG_REL_ Kombi_PAG SG_ 2589283656 ORU_Status 5000;
BA_REL_ "GenSigTimeoutTime" BU_SG_REL_ Kombi_PAG SG_ 2527679670 OTA_FC_Hinweis_Update 5000;
BA_REL_ "GenSigTimeoutTime" BU_SG_REL_ Kombi_PAG SG_ 2527679670 OTA_FC_PredMaint_Ausfall 5000;
BA_REL_ "GenSigTimeoutTime" BU_SG_REL_ Kombi_PAG SG_ 2527679670 OTA_FC_Warnung_Update 5000;
BA_REL_ "GenSigTimeoutTime" BU_SG_REL_ Kombi_PAG SG_ 2527679670 OTA_FC_IOF_Ausfall 5000;
BA_REL_ "GenSigTimeoutTime" BU_SG_REL_ Kombi_PAG SG_ 2527679670 OTA_FC_FoD_Stornierung 5000;
BA_REL_ "GenSigTimeoutTime" BU_SG_REL_ Kombi_PAG SG_ 970 PACC02_InnoDrive_Texte 1000;
BA_REL_ "GenSigTimeoutTime" BU_SG_REL_ Kombi_PAG SG_ 970 PACC02_Systemstatus_Anzeige 1000;
BA_REL_ "GenSigTimeoutTime" BU_SG_REL_ Kombi_PAG SG_ 970 PACC02_Automode 1000;
BA_REL_ "GenSigTimeoutTime" BU_SG_REL_ Kombi_PAG SG_ 970 PACC02_Uebernahmeaufforderung 1000;
BA_REL_ "GenSigTimeoutTime" BU_SG_REL_ Kombi_PAG SG_ 970 PACC02_Systemstatus 1000;
BA_REL_ "GenSigTimeoutTime" BU_SG_REL_ Kombi_PAG SG_ 970 PACC02_Vorausschaugeschw 1000;
BA_REL_ "GenSigTimeoutTime" BU_SG_REL_ Kombi_PAG SG_ 970 PACC02_Offset 1000;
BA_REL_ "GenSigTimeoutTime" BU_SG_REL_ Kombi_PAG SG_ 970 PACC02_Sollgeschwindigkeit 1000;
BA_REL_ "GenSigTimeoutTime" BU_SG_REL_ Kombi_PAG SG_ 970 PACC02_naechstes_Event 1000;
BA_REL_ "GenSigTimeoutTime" BU_SG_REL_ Kombi_PAG SG_ 2463978731 PACC02_Geschw_Vorausschau 1000;
BA_REL_ "GenSigTimeoutTime" BU_SG_REL_ Kombi_PAG SG_ 2463978731 PACC02_Event_aktiv 1000;
BA_REL_ "GenSigTimeoutTime" BU_SG_REL_ Kombi_PAG SG_ 2463978731 PACC02_Hinweis_Geschw 1000;
BA_REL_ "GenSigTimeoutTime" BU_SG_REL_ Kombi_PAG SG_ 2463978731 PACC02_Offset_aktiv 1000;
BA_REL_ "GenSigTimeoutTime" BU_SG_REL_ Kombi_PAG SG_ 2463978731 PACC02_Offset_Anzeige 1000;
BA_REL_ "GenSigTimeoutTime" BU_SG_REL_ Kombi_PAG SG_ 908 PACC_Sytemstatus_Anzeige 1000;
BA_REL_ "GenSigTimeoutTime" BU_SG_REL_ Kombi_PAG SG_ 908 PACC_Automode 1000;
BA_REL_ "GenSigTimeoutTime" BU_SG_REL_ Kombi_PAG SG_ 908 PACC_Systemstatus 1000;
BA_REL_ "GenSigTimeoutTime" BU_SG_REL_ Kombi_PAG SG_ 908 PACC_Sollgeschwindigkeit 1000;
BA_REL_ "GenSigTimeoutTime" BU_SG_REL_ Kombi_PAG SG_ 696 PADM_Warnmeldung_Prio2 1600;
BA_REL_ "GenSigTimeoutTime" BU_SG_REL_ Kombi_PAG SG_ 872 PDC2_Tonausgabe_Front 1000;
BA_REL_ "GenSigTimeoutTime" BU_SG_REL_ Kombi_PAG SG_ 872 PDC2_Tonausgabe_Heck 1000;
BA_REL_ "GenSigTimeoutTime" BU_SG_REL_ Kombi_PAG SG_ 872 PH2_Lautstaerke_hinten 1000;
BA_REL_ "GenSigTimeoutTime" BU_SG_REL_ Kombi_PAG SG_ 872 PH2_Lautstaerke_vorn 1000;
BA_REL_ "GenSigTimeoutTime" BU_SG_REL_ Kombi_PAG SG_ 872 PH2_Stoermeldung 1000;
BA_REL_ "GenSigTimeoutTime" BU_SG_REL_ Kombi_PAG SG_ 2463978617 PH2_Verschmutzungsmeldung 5000;
BA_REL_ "GenSigTimeoutTime" BU_SG_REL_ Kombi_PAG SG_ 2463978617 PH2_WAH_Meldung 5000;
BA_REL_ "GenSigTimeoutTime" BU_SG_REL_ Kombi_PAG SG_ 1175 PDC_Tonausgabe_Front 1000;
BA_REL_ "GenSigTimeoutTime" BU_SG_REL_ Kombi_PAG SG_ 1175 PDC_Tonausgabe_Heck 1000;
BA_REL_ "GenSigTimeoutTime" BU_SG_REL_ Kombi_PAG SG_ 1175 PH_Frequenz_hinten 1000;
BA_REL_ "GenSigTimeoutTime" BU_SG_REL_ Kombi_PAG SG_ 1175 PH_Lautstaerke_hinten 1000;
BA_REL_ "GenSigTimeoutTime" BU_SG_REL_ Kombi_PAG SG_ 1175 PH_Frequenz_vorn 1000;
BA_REL_ "GenSigTimeoutTime" BU_SG_REL_ Kombi_PAG SG_ 1175 PH_Lautstaerke_vorn 1000;
BA_REL_ "GenSigTimeoutTime" BU_SG_REL_ Kombi_PAG SG_ 1175 PH_Stoermeldung 1000;
BA_REL_ "GenSigTimeoutTime" BU_SG_REL_ Waehlhebel_SB SG_ 2600468496 NM_Gateway_SNI 2000;
BA_REL_ "GenSigTimeoutTime" BU_SG_REL_ Waehlhebel_SB SG_ 2600468496 NM_Gateway_CBV_CRI 2000;
BA_REL_ "GenSigTimeoutTime" BU_SG_REL_ Waehlhebel_SB SG_ 2600468496 NM_Gateway_CAB 2000;
BA_REL_ "GenSigTimeoutTime" BU_SG_REL_ Waehlhebel_SB SG_ 2600468507 NM_HUD_SNI 2000;
BA_REL_ "GenSigTimeoutTime" BU_SG_REL_ Waehlhebel_SB SG_ 2600468507 NM_HUD_CBV_CRI 2000;
BA_REL_ "GenSigTimeoutTime" BU_SG_REL_ Waehlhebel_SB SG_ 2600468507 NM_HUD_CAB 2000;
BA_REL_ "GenSigTimeoutTime" BU_SG_REL_ Waehlhebel_SB SG_ 2600468500 NM_Kombi_SNI 2000;
BA_REL_ "GenSigTimeoutTime" BU_SG_REL_ Waehlhebel_SB SG_ 2600468500 NM_Kombi_CBV_CRI 2000;
BA_REL_ "GenSigTimeoutTime" BU_SG_REL_ Waehlhebel_SB SG_ 2600468500 NM_Kombi_CAB 2000;
BA_REL_ "GenSigTimeoutTime" BU_SG_REL_ Waehlhebel_SB SG_ 913 OBD_Driving_Cycle 5000;
BA_REL_ "GenSigTimeoutTime" BU_SG_REL_ Waehlhebel_SB SG_ 913 OBD_Warm_Up_Cycle 5000;
VAL_ 1155 Mo_Powermeter_Grenze 4093 "OFF" ;
VAL_ 1155 MO_Text_Aktivierung_Antrieb 0 "keine_Anzeige" 1 "Ladestecker_nicht_fahrbereit" 2 "erneute_Aktivierung_erforderlich" 3 "Warten_Antrieb_wird_aktiviert" 4 "zum_Fahren_Bremse_und_Fahrstufe" 5 "h2_Tankklappe_nicht_fahrbereit" 6 "zum_Starten_Bremse_treten" 7 "zum_Starten_Kupplung_treten" 15 "Init" ;
VAL_ 1155 MO_Powermeter_Inszenierung_aktiv 0 "keine_Anzeige" 1 "Inszenierung_aktiv" ;
VAL_ 1155 MO_Powermeter_Charge_Grenze 1022 "Init" 1023 "Fehler" ;
VAL_ 1155 MO_Powermeter_Grenze_strategisch 4094 "Init" 4095 "Fehler" ;
VAL_ 1155 MO_Powermeter_untere_E_Grenze 4094 "Init" 4095 "Fehler" ;
VAL_ 1155 MO_Powermeter_obere_E_Grenze 4094 "Init" 4095 "Fehler" ;
VAL_ 878 RML_Status_Anzeige_Range 0 "Range_Limit_aus" 1 "Range_Limit_passiv" 2 "Range_Limit_aktiv" 3 "Range_Limit_ueberstimmt" 4 "Range_Limit_Fehler" ;
VAL_ 878 RML_vMax_Range 1022 "kein_Range_Limit" 1023 "Init" ;
VAL_ 2527679823 MO_WI_FlgInfoTmpLvlVolWa 0 "Temporaere_Fuellstandanz_inaktiv" 1 "Temporaere_Fuellstandanz_aktiv" ;
VAL_ 2527679823 MO_WI_StWarnVolWa 0 "keine_Anzeige" 1 "Warnung_Fuellstand_1" 2 "Warnung_Fuellstand_2" 3 "Warnung_Fuellstand_3" ;
VAL_ 2589284146 MRR_HL_P_Text_ASCII_01 45 "Init" ;
VAL_ 2589284146 MRR_HL_P_Text_ASCII_08 45 "Init" ;
VAL_ 2589284146 MRR_HL_P_Text_ASCII_15 45 "Init" ;
VAL_ 2589284146 MRR_HL_P_Text_ASCII_02 45 "Init" ;
VAL_ 2589284146 MRR_HL_P_Text_ASCII_09 45 "Init" ;
VAL_ 2589284146 MRR_HL_P_Text_ASCII_16 45 "Init" ;
VAL_ 2589284146 MRR_HL_P_Text_ASCII_03 45 "Init" ;
VAL_ 2589284146 MRR_HL_P_Text_ASCII_10 45 "Init" ;
VAL_ 2589284146 MRR_HL_P_Text_ASCII_17 45 "Init" ;
VAL_ 2589284146 MRR_HL_P_Text_ASCII_04 45 "Init" ;
VAL_ 2589284146 MRR_HL_P_Text_ASCII_11 45 "Init" ;
VAL_ 2589284146 MRR_HL_P_Text_ASCII_18 45 "Init" ;
VAL_ 2589284146 MRR_HL_P_Text_ASCII_05 45 "Init" ;
VAL_ 2589284146 MRR_HL_P_Text_ASCII_12 45 "Init" ;
VAL_ 2589284146 MRR_HL_P_Text_ASCII_19 45 "Init" ;
VAL_ 2589284146 MRR_HL_P_Text_ASCII_06 45 "Init" ;
VAL_ 2589284146 MRR_HL_P_Text_ASCII_13 45 "Init" ;
VAL_ 2589284146 MRR_HL_P_Text_ASCII_20 45 "Init" ;
VAL_ 2589284146 MRR_HL_P_Text_ASCII_07 45 "Init" ;
VAL_ 2589284146 MRR_HL_P_Text_ASCII_14 45 "Init" ;
VAL_ 2589284146 MRR_HL_P_Text_ASCII_21 45 "Init" ;
VAL_ 2589284147 MRR_HR_P_Text_ASCII_01 45 "Init" ;
VAL_ 2589284147 MRR_HR_P_Text_ASCII_08 45 "Init" ;
VAL_ 2589284147 MRR_HR_P_Text_ASCII_15 45 "Init" ;
VAL_ 2589284147 MRR_HR_P_Text_ASCII_02 45 "Init" ;
VAL_ 2589284147 MRR_HR_P_Text_ASCII_09 45 "Init" ;
VAL_ 2589284147 MRR_HR_P_Text_ASCII_16 45 "Init" ;
VAL_ 2589284147 MRR_HR_P_Text_ASCII_03 45 "Init" ;
VAL_ 2589284147 MRR_HR_P_Text_ASCII_10 45 "Init" ;
VAL_ 2589284147 MRR_HR_P_Text_ASCII_17 45 "Init" ;
VAL_ 2589284147 MRR_HR_P_Text_ASCII_04 45 "Init" ;
VAL_ 2589284147 MRR_HR_P_Text_ASCII_11 45 "Init" ;
VAL_ 2589284147 MRR_HR_P_Text_ASCII_18 45 "Init" ;
VAL_ 2589284147 MRR_HR_P_Text_ASCII_05 45 "Init" ;
VAL_ 2589284147 MRR_HR_P_Text_ASCII_12 45 "Init" ;
VAL_ 2589284147 MRR_HR_P_Text_ASCII_19 45 "Init" ;
VAL_ 2589284147 MRR_HR_P_Text_ASCII_06 45 "Init" ;
VAL_ 2589284147 MRR_HR_P_Text_ASCII_13 45 "Init" ;
VAL_ 2589284147 MRR_HR_P_Text_ASCII_20 45 "Init" ;
VAL_ 2589284147 MRR_HR_P_Text_ASCII_07 45 "Init" ;
VAL_ 2589284147 MRR_HR_P_Text_ASCII_14 45 "Init" ;
VAL_ 2589284147 MRR_HR_P_Text_ASCII_21 45 "Init" ;
VAL_ 2589284144 MRR_VL_P_Text_ASCII_01 45 "Init" ;
VAL_ 2589284144 MRR_VL_P_Text_ASCII_08 45 "Init" ;
VAL_ 2589284144 MRR_VL_P_Text_ASCII_15 45 "Init" ;
VAL_ 2589284144 MRR_VL_P_Text_ASCII_02 45 "Init" ;
VAL_ 2589284144 MRR_VL_P_Text_ASCII_09 45 "Init" ;
VAL_ 2589284144 MRR_VL_P_Text_ASCII_16 45 "Init" ;
VAL_ 2589284144 MRR_VL_P_Text_ASCII_03 45 "Init" ;
VAL_ 2589284144 MRR_VL_P_Text_ASCII_10 45 "Init" ;
VAL_ 2589284144 MRR_VL_P_Text_ASCII_17 45 "Init" ;
VAL_ 2589284144 MRR_VL_P_Text_ASCII_04 45 "Init" ;
VAL_ 2589284144 MRR_VL_P_Text_ASCII_11 45 "Init" ;
VAL_ 2589284144 MRR_VL_P_Text_ASCII_18 45 "Init" ;
VAL_ 2589284144 MRR_VL_P_Text_ASCII_05 45 "Init" ;
VAL_ 2589284144 MRR_VL_P_Text_ASCII_12 45 "Init" ;
VAL_ 2589284144 MRR_VL_P_Text_ASCII_19 45 "Init" ;
VAL_ 2589284144 MRR_VL_P_Text_ASCII_06 45 "Init" ;
VAL_ 2589284144 MRR_VL_P_Text_ASCII_13 45 "Init" ;
VAL_ 2589284144 MRR_VL_P_Text_ASCII_20 45 "Init" ;
VAL_ 2589284144 MRR_VL_P_Text_ASCII_07 45 "Init" ;
VAL_ 2589284144 MRR_VL_P_Text_ASCII_14 45 "Init" ;
VAL_ 2589284144 MRR_VL_P_Text_ASCII_21 45 "Init" ;
VAL_ 2589284145 MRR_VR_P_Text_ASCII_01 45 "Init" ;
VAL_ 2589284145 MRR_VR_P_Text_ASCII_08 45 "Init" ;
VAL_ 2589284145 MRR_VR_P_Text_ASCII_15 45 "Init" ;
VAL_ 2589284145 MRR_VR_P_Text_ASCII_02 45 "Init" ;
VAL_ 2589284145 MRR_VR_P_Text_ASCII_09 45 "Init" ;
VAL_ 2589284145 MRR_VR_P_Text_ASCII_16 45 "Init" ;
VAL_ 2589284145 MRR_VR_P_Text_ASCII_03 45 "Init" ;
VAL_ 2589284145 MRR_VR_P_Text_ASCII_10 45 "Init" ;
VAL_ 2589284145 MRR_VR_P_Text_ASCII_17 45 "Init" ;
VAL_ 2589284145 MRR_VR_P_Text_ASCII_04 45 "Init" ;
VAL_ 2589284145 MRR_VR_P_Text_ASCII_11 45 "Init" ;
VAL_ 2589284145 MRR_VR_P_Text_ASCII_18 45 "Init" ;
VAL_ 2589284145 MRR_VR_P_Text_ASCII_05 45 "Init" ;
VAL_ 2589284145 MRR_VR_P_Text_ASCII_12 45 "Init" ;
VAL_ 2589284145 MRR_VR_P_Text_ASCII_19 45 "Init" ;
VAL_ 2589284145 MRR_VR_P_Text_ASCII_06 45 "Init" ;
VAL_ 2589284145 MRR_VR_P_Text_ASCII_13 45 "Init" ;
VAL_ 2589284145 MRR_VR_P_Text_ASCII_20 45 "Init" ;
VAL_ 2589284145 MRR_VR_P_Text_ASCII_07 45 "Init" ;
VAL_ 2589284145 MRR_VR_P_Text_ASCII_14 45 "Init" ;
VAL_ 2589284145 MRR_VR_P_Text_ASCII_21 45 "Init" ;
VAL_ 688 MO_Verbrauch_EM_Ges_Ueberlauf 0 "kein_Ueberlauf" 1 "Ueberlauf_Verbrauchssignal" ;
VAL_ 688 MO_Rekuperation_EM_Ges_Ueberlauf 0 "kein_Ueberlauf" 1 "Ueberlauf_Reku_Leistungssignal" ;
VAL_ 689 TME_PlanAntw_Zaehler 14 "Init" 15 "Fehler" ;
VAL_ 689 TME_Verbrauch_gesamt_Ueberlauf 0 "kein_Ueberlauf" 1 "Ueberlauf" ;
VAL_ 689 TME_Energie_Thermo 16382 "Init" 16383 "Fehler" ;
VAL_ 689 TME_Energie_Komfort 16382 "Init" 16383 "Fehler" ;
VAL_ 1284 MVK_DCDC_Sollmodus_02 0 "Standby" 1 "MV_On" 2 "Tiefsetzen" 3 "Hochsetzen" 4 "Startunterstuetzung_48V" 6 "Startunterstuetzung_12V" 7 "Init" 9 "MV_On_Notbetrieb" 10 "Tiefsetzen_Notbetrieb" 11 "Pruefpuls_12V" 13 "Reaktivierung_BMS" ;
VAL_ 1284 MVK_eKAT_Sollmodus 0 "Standby" 1 "Freigabe" 6 "Init" ;
VAL_ 1284 MVK_eKMV_Sollmodus 0 "Keine_Freigabe" 1 "Freigabe" 7 "Init" ;
VAL_ 1284 MVK_MVH_L_Sollmodus 0 "Keine_Freigabe" 1 "Freigabe" 7 "Init" ;
VAL_ 1284 MV_Bordnetz_aktiv 0 "inaktiv" 1 "aktiv" ;
VAL_ 1284 MVK_BOOST_Sollmodus 0 "Keine_Freigabe" 1 "Freigabe" 7 "Init" ;
VAL_ 1284 MVK_eABC_Sollmodus 0 "Keine_Freigabe" 1 "Freigabe" 7 "Init" ;
VAL_ 1284 MVK_eAWS_Sollmodus 0 "Keine_Freigabe" 1 "Freigabe" 7 "Init" ;
VAL_ 1284 MV_Bordnetz_Fehler 0 "kein_Fehler" 1 "Fehler" ;
VAL_ 1284 MVK_MVPTC_Sollmodus 0 "Keine_Freigabe" 1 "Freigabe" 7 "Init" ;
VAL_ 1284 MVK_Istmodus_Anf 0 "nicht_angefordert" 1 "angefordert" ;
VAL_ 1284 MVK_MO_EmSollzustand 0 "MvOff" 1 "MvStbyReq" 2 "MvStbyWait" 3 "MvBattOnReq" 4 "MvBattOnWait" 10 "MvOnIdle" 18 "MvOnDrvReq" 19 "MvOnDrvWait" 20 "MvOnDrv" 28 "MvStepUpReq" 29 "MvStepUpWait" 30 "MvStepUp" 38 "MvStepDownReq" 39 "MvStepDownWait" 40 "MvStepDown" 96 "MvCpntOffReq" 97 "MvCpntOffWait" 98 "MvBattOffReq" 99 "MvBattOffWait" 109 "MvDcDcFailOffReq" 110 "MvDcDcFail" 119 "MvElmFailOffReq" 120 "MvElmFail" 126 "MvFailCpntOffReq" 127 "MvFailCpntOffWait" 128 "MvFailBattOffReq" 129 "MvFailBattOffWait" 130 "MvFailBattOff" 138 "MvFailUCtlReq" 139 "MvFailUCtlWait" 140 "MvFailUCtl" 150 "MvEmgcyOff" 255 "Init" ;
VAL_ 1284 MVK_BMS_Sollmodus 0 "MV_Off" 1 "MV_On" 7 "Init" ;
VAL_ 1284 MVK_DCDC_Sollmodus 0 "Standby" 1 "MV_On" 2 "Tiefsetzen" 3 "Hochsetzen" 4 "Startunterstuetzung_48V" 6 "Startunterstuetzung_12V" 7 "Init" ;
VAL_ 1284 MVK_MV_Netz_Warnungen 0 "Keine_Warnung" 1 "Warntext_MV_Netz_Anf" 2 "Fehlertext_MV_Netz_Anf" 3 "Warnung_Kein_Wiederstart_moeglic" ;
VAL_ 1157 ND_SatInUse 30 "Init" 31 "Fehler" ;
VAL_ 1157 POS_Guete_horizontal_verfuegbar 0 "nicht_verfuegbar" 1 "verfuegbar" ;
VAL_ 1157 ND_SatInView 30 "Init" 31 "Fehler" ;
VAL_ 1157 POS_Guete_horizontal 124 "von_248m_bis_400m" 125 "mehr_als_400m" 126 "Init" 127 "Fehler" ;
VAL_ 1157 NP_Altitude 4094 "Init" 4095 "Fehler" ;
VAL_ 2527679512 ND_Timezone_Offset 14 "Init" 15 "Fehler" ;
VAL_ 2527679512 ND_Timezone_SignBit 0 "PLUS_Vorzeichen" 1 "MINUS_Vorzeichen" ;
VAL_ 2527679512 ND_Timezone_Validity 0 "invalid" 1 "valid" ;
VAL_ 2527679512 ND_TimeToDestination 510 "Fehler" 511 "Init" ;
VAL_ 2527679512 ND_RouteType 0 "keine_Zielfuehrung_oder_MPR_aktiv" 1 "MPR_aktiv" 2 "Zielfuehrung_aktiv" 3 "reserviert" ;
VAL_ 2527679512 ND_TimeOffset 0 "Ziel_in_gleicher_Zeitzone" 1 "Ziel_in_Zeitzone_plus_1" 2 "Ziel_in_Zeitzone_minus_1" 3 "Zielzeitzone_groesser_plus_minus_1" ;
VAL_ 2527679512 ND_Fuelstation_detected 0 "nicht_verbaut" 1 "Tankstelle_nicht_erkannt" 2 "Tankstelle_erkannt" 3 "Init" ;
VAL_ 2527679512 ND_Velocity 1022 "Init" 1023 "Fehler" ;
VAL_ 2527679512 ND_RecDelay 4094 "Init" 4095 "Fehler" ;
VAL_ 2527679512 ND_SendDelay 4094 "Init" 4095 "Fehler" ;
VAL_ 1696 NV_aktiv 0 "NV nicht aktiv" 1 "NV aktiv" ;
VAL_ 1696 NV_Texte 0 "Init" 1 "Abblendlicht_einschalten" 2 "Fussgaengermarkierung_n_v" 3 "zur_Zeit_nicht_verfuegbar" 4 "Systemfehler" 5 "Fussgaengermarkierung_deakt" 6 "Blindheit_erkannt" 7 "kein_Text" ;
VAL_ 1696 NV_Gong 0 "kein_Gong" 1 "Gong_leise" 2 "Gong_mittel" 3 "Gong_laut" ;
VAL_ 1696 NV_Symbol 0 "kein_Symbol_anzeigen" 1 "Symbol_fuer_erkanntes_Objekt_anzeigen" ;
VAL_ 1696 NV_Hinweise 0 "keine_Anzeige" 1 "Disclaimer" 2 "Fussgaenger_Markierung_nicht_verfuegbar" 3 "Nachtsichtsystem_wird_initialisiert" ;
VAL_ 1696 NV_Piktogramm_aktiv 0 "keine_Anzeigenprioritaet" 1 "Anzeigenprioritaet" ;
VAL_ 1696 NV_Akustik_deaktiviert_Icon 0 "aus" 1 "ein" ;
VAL_ 1696 NV_FGM_deaktiviert_Icon 0 "aus" 1 "ein" ;
VAL_ 1696 NV_Markierungslicht_links 0 "Aus" 1 "Ein" ;
VAL_ 1696 NV_Markierungslicht_rechts 0 "Aus" 1 "Ein" ;
VAL_ 1696 NV_Symbol_Tierwarnung 0 "Aus" 1 "Ein" ;
VAL_ 1696 NV_Anf_Prefill 0 "nicht_angefordert" 1 "angefordert" ;
VAL_ 1696 NV_HBA_Parameter 0 "Defaultparametersatz" 1 "Parametersatz_mit_leicht_erhoehter_Empfindlichkeit" 2 "Parametersatz_mit_erhoehter_Empfindlichkeit" 3 "Parametersatz_mit_hoechster_Empfindlichkeit" ;
VAL_ 1696 NV_LED_Leiste 0 "AUS_keine_Anzeige" 1 "Stufe_1_glimmen" 2 "Stufe_2_leuchten" 3 "Stufe_3_blinken" ;
VAL_ 1696 NV_PreSense_Status 0 "Init" 1 "verfuegbar" 2 "nicht_verfuegbar" ;
VAL_ 1696 NV_PreSense_Modus_System 0 "deaktiviert" 1 "aktiviert" ;
VAL_ 1696 NV_PreSense_Modus_Warnung 0 "Aus" 1 "Setting_2" 2 "Setting_3" 3 "Setting_4" 4 "Setting_5" 5 "Ein" ;
VAL_ 1696 NV_FAS_Fkt_Status 0 "Init" 1 "Funktion_Ist_Ein" 2 "Funktion_Ist_Aus" 3 "Fehler" ;
VAL_ 1696 NV_Akt_Status_MMI 0 "deaktiviert" 1 "aktiviert" 3 "Init" ;
VAL_ 1696 NV_AnforderungBildaufschaltung 0 "KeineBildaufschaltung" 1 "Bildaufschaltung" ;
VAL_ 2600468496 NM_Gateway_SNI 16 "Gateway" ;
VAL_ 2600468496 NM_Gateway_CBV_AWB 0 "Passiver_WakeUp" 1 "Aktiver_WakeUp" ;
VAL_ 2600468496 NM_Gateway_CBV_CRI 0 "NM_ohne_Clusteranforderungen" 1 "NM_mit_Clusteranforderungen" ;
VAL_ 2600468496 NM_Gateway_NM_State 0 "Init" 1 "NM_RM_aus_BSM" 2 "NM_RM_aus_PBSM" 4 "NM_NO_aus_RM" 8 "NM_NO_aus_RS" 16 "reserved" 32 "reserved" ;
VAL_ 2600468496 NM_Gateway_Car_Wakeup 0 "Inaktiv" 1 "Car_Wakeup" ;
VAL_ 2600468496 NM_Gateway_UDS_CC 0 "Inaktiv" 1 "CC_aktiv" ;
VAL_ 2600468496 NM_Gateway_NM_aktiv_KL15 0 "Inaktiv" 1 "KL15_EIN" ;
VAL_ 2600468496 NM_Gateway_NM_aktiv_Diagnose 0 "Init" 1 "Diagnose_aktiv" ;
VAL_ 2600468496 NM_Gateway_NM_aktiv_Tmin 0 "Inaktiv" 1 "Mindestaktivzeit" ;
VAL_ 2600468496 NM_Gateway_NM_aktiv_CWU 0 "kein_CWU_gesetzt" 1 "CWU_gesetzt" ;
VAL_ 2600468496 NM_Gateway_NM_aktiv_FC 0 "kein_FC_gesetzt" 1 "FC_gesetzt" ;
VAL_ 2600468496 NM_Gateway_NM_aktiv_Connect 0 "inaktiv" 1 "Nachlauf_aufgrund_Connect" ;
VAL_ 2600468496 NM_Gateway_NM_aktiv_EM 0 "inaktiv" 1 "Nachlauf_aufgrund_Energiemanagement" ;
VAL_ 2600468496 NM_Gateway_NM_aktiv_OBDC 0 "kein_Nachlauf" 1 "Nachlauf_aufgrund_OBDC" ;
VAL_ 2600468496 NM_Gateway_NM_aktiv_Buskopplung 0 "inaktiv" 1 "Nachlauf_aufgrund_Buskopplung" ;
VAL_ 2600468496 NM_Gateway_NM_aktiv_LIN2 0 "Inaktiv" 1 "LIN2_aktiv" ;
VAL_ 2600468496 NM_Gateway_NM_aktiv_Fremdladung 0 "inaktiv" 1 "Nachlauf_aufgrund_Connect" ;
VAL_ 2600468496 NM_Gateway_CAB 0 "inaktiv" 1 "CAB_01__Tueren" 2 "CAB_02__Anhaenger_KCAN" 4 "CAB_03__Nightvision" 8 "CAB_04__Sitzverstellung" 16 "CAB_05__Klappen" 32 "CAB_06__Infotainment" 64 "CAB_07__Sub_Infotainment" 128 "CAB_08__Anzeige" 256 "CAB_09__Laden_HCAN" 512 "CAB_10__Klima" 1024 "CAB_11__FlexRay" 262144 "CAB_19__VLAN_RemoteFC" 524288 "CAB_20__VLAN_Komfort" 1048576 "CAB_21__VLAN_Internet" 2097152 "CAB_22__VLAN_Connect" 4194304 "CAB_23__VLAN_Infotainment" 8388608 "CAB_24__VLAN_FAS" ;
VAL_ 2600468507 NM_HUD_SNI 27 "HUD" ;
VAL_ 2600468507 NM_HUD_CBV_AWB 0 "Passiver_WakeUp" 1 "Aktiver_WakeUp" ;
VAL_ 2600468507 NM_HUD_CBV_CRI 0 "NM_ohne_Clusteranforderungen" 1 "NM_mit_Clusteranforderungen" ;
VAL_ 2600468507 NM_HUD_NM_State 0 "Init" 1 "NM_RM_aus_BSM" 2 "NM_RM_aus_PBSM" 4 "NM_NO_aus_RM" 8 "NM_NO_aus_RS" 16 "reserved" 32 "reserved" ;
VAL_ 2600468507 NM_HUD_Car_WakeUp 0 "Inaktiv" 1 "Car_Wakeup" ;
VAL_ 2600468507 NM_HUD_UDS_CC 0 "Inaktiv" 1 "CC_aktiv" ;
VAL_ 2600468507 NM_HUD_NM_aktiv_KL15 0 "Inaktiv" 1 "KL15_EIN" ;
VAL_ 2600468507 NM_HUD_NM_aktiv_Diagnose 0 "Init" 1 "Diagnose_aktiv" ;
VAL_ 2600468507 NM_HUD_NM_aktiv_Tmin 0 "Inaktiv" 1 "Mindestaktivzeit" ;
VAL_ 2600468507 NM_HUD_CAB 0 "inaktiv" 1 "CAB_01__Tueren" 2 "CAB_02__Anhaenger_KCAN" 4 "CAB_03__Nightvision" 8 "CAB_04__Sitzverstellung" 16 "CAB_05__Klappen" 32 "CAB_06__Infotainment" 64 "CAB_07__Sub_Infotainment" 128 "CAB_08__Anzeige" 256 "CAB_09__Laden_HCAN" 512 "CAB_10__Klima" 1024 "CAB_11__FlexRay" 262144 "CAB_19__VLAN_RemoteFC" 524288 "CAB_20__VLAN_Komfort" 1048576 "CAB_21__VLAN_Internet" 2097152 "CAB_22__VLAN_Connect" 4194304 "CAB_23__VLAN_Infotainment" 8388608 "CAB_24__VLAN_FAS" ;
VAL_ 2600468500 NM_Kombi_SNI 20 "Kombi" ;
VAL_ 2600468500 NM_Kombi_CBV_AWB 0 "Passiver_WakeUp" 1 "Aktiver_WakeUp" ;
VAL_ 2600468500 NM_Kombi_CBV_CRI 0 "Standard_Layout" 1 "TNB_Layout" ;
VAL_ 2600468500 NM_Kombi_NM_State 0 "Init" 1 "NM_RM_aus_BSM" 2 "NM_RM_aus_PBSM" 4 "NM_NO_aus_RM" 8 "NM_NO_aus_RS" 16 "reserved" 32 "reserved" ;
VAL_ 2600468500 NM_Kombi_Car_Wakeup 0 "Inaktiv" 1 "Car_Wakeup" ;
VAL_ 2600468500 NM_Kombi_UDS_CC 0 "Init" 1 "CC_aktiv" ;
VAL_ 2600468500 NM_Kombi_NM_aktiv_KL15 0 "Inaktiv" 1 "KL15_EIN" ;
VAL_ 2600468500 NM_Kombi_NM_aktiv_Diagnose 0 "Init" 1 "Diagnose_aktiv" ;
VAL_ 2600468500 NM_Kombi_NM_aktiv_Tmin 0 "Inaktiv" 1 "Mindestaktivzeit" ;
VAL_ 2600468500 NM_Kombi_NM_aktiv_Buzzer 1 "Buzzer_aktiv" ;
VAL_ 2600468500 NM_Kombi_NM_aktiv_Display 1 "Display_aktiv" ;
VAL_ 2600468500 NM_Kombi_NM_aktiv_Tankinhalt 1 "Tankinhaltermittlung_aktiv" ;
VAL_ 2600468500 NM_Kombi_CAB 0 "inaktiv" 1 "CAB_01__Tueren" 2 "CAB_02__Anhaenger_KCAN" 4 "CAB_03__Nightvision" 8 "CAB_04__Sitzverstellung" 16 "CAB_05__Klappen" 32 "CAB_06__Infotainment" 64 "CAB_07__Sub_Infotainment" 128 "CAB_08__Anzeige" 256 "CAB_09__Laden_HCAN" 512 "CAB_10__Klima" 1024 "CAB_11__FlexRay" 262144 "CAB_19__VLAN_RemoteFC" 524288 "CAB_20__VLAN_Komfort" 1048576 "CAB_21__VLAN_Internet" 2097152 "CAB_22__VLAN_Connect" 4194304 "CAB_23__VLAN_Infotainment" 8388608 "CAB_24__VLAN_FAS" ;
VAL_ 2600468563 NM_Waehlhebel_SNI 83 "Waehlhebel" ;
VAL_ 2600468563 NM_Waehlhebel_CBV_AWB 0 "Passiver_WakeUp" 1 "Aktiver_WakeUp" ;
VAL_ 2600468563 NM_Waehlhebel_CBV_CRI 0 "NM_ohne_Clusteranforderungen" 1 "NM_mit_Clusteranforderungen" ;
VAL_ 2600468563 NM_Waehlhebel_NM_State 0 "Init" 1 "NM_RM_aus_BSM" 2 "NM_RM_aus_PBSM" 4 "NM_NO_aus_RM" 8 "NM_NO_aus_RS" 16 "reserved" 32 "reserved" ;
VAL_ 2600468563 NM_Waehlhebel_Car_Wakeup 0 "Inaktiv" 1 "Car_Wakeup" ;
VAL_ 2600468563 NM_Waehlhebel_UDS_CC 0 "Inaktiv" 1 "CC_aktiv" ;
VAL_ 2600468563 NM_Waehlhebel_NM_aktiv_KL15 0 "Inaktiv" 1 "KL15_EIN" ;
VAL_ 2600468563 NM_Waehlhebel_NM_aktiv_Diagnose 0 "Init" 1 "Diagnose_aktiv" ;
VAL_ 2600468563 NM_Waehlhebel_NM_aktiv_Tmin 0 "Inaktiv" 1 "Mindestaktivzeit" ;
VAL_ 2600468563 NM_Waehlhebel_CAB 0 "inaktiv" 1 "CAB_01__Tueren" 2 "CAB_02__Anhaenger_KCAN" 4 "CAB_03__Nightvision" 8 "CAB_04__Sitzverstellung" 16 "CAB_05__Klappen" 32 "CAB_06__Infotainment" 64 "CAB_07__Sub_Infotainment" 128 "CAB_08__Anzeige" 256 "CAB_09__Laden_HCAN" 512 "CAB_10__Klima" 1024 "CAB_11__FlexRay" 262144 "CAB_19__VLAN_RemoteFC" 524288 "CAB_20__VLAN_Komfort" 1048576 "CAB_21__VLAN_Internet" 2097152 "CAB_22__VLAN_Connect" 4194304 "CAB_23__VLAN_Infotainment" 8388608 "CAB_24__VLAN_FAS" ;
VAL_ 1635 BEM_02_Abschaltstufen 0 "Stufe 0 (keine Einschraenkungen)" 1 "Stufe 1" 2 "Stufe 2" 3 "Stufe 3" 4 "Transportmodus" 7 "Ruhestrommessmodus" ;
VAL_ 1635 BEM_STH_Zielzeit 14 "Init" 15 "Fehler" ;
VAL_ 1635 BEM_MMI_Vorwarnung 0 "keine Anzeige" 1 "Anzeige MMI-Vorwarnung" ;
VAL_ 1635 NVEM_Anf_SD_schalten 0 "Anf_SD_Nachlauf_nicht_aktiv" 1 "Anf_SD_Nachlauf_aktiv" ;
VAL_ 1635 BEM_Generatordiagnose 0 "keine Anzeige" 1 "Ladekontrollanzeige ein (Vorhalt)" 2 "rotes Batteriesymbol und Text (Generator defekt)" 3 "Hybrid_DCDC_Wandler_defekt" ;
VAL_ 1635 BEM_Red_Innengeblaese 0 "keine Reduzierung" 1 "Reduzierung Stufe 1" 2 "Reduzierung Stufe 2" 3 "Reduzierung Stufe 2 und Abschaltung Kompressor" ;
VAL_ 1635 BEM_STH_Einschaltverbot 0 "volle Verfuegbarkeit Standheizung/-lueftung" 1 "Standheizung/-lueftung nicht aktivierbar" ;
VAL_ 1635 BEM_HL_Regelung_Status 0 "HL_Regelung_inaktiv_(vor_und_waehrend_Motorstart)" 1 "HL_Regelung_Stufe_1" 2 "HL_Regelung_Stufe_2" 3 "HL_Regelung_Stufe_3" 4 "Verbrauchernotabschaltung_(VNA)" 5 "HL_Regelung_Stufe_5" 7 "Default" ;
VAL_ 1635 BEM_Ladezustand 14 "Init" 15 "Fehler" ;
VAL_ 1635 BEM_Batteriediagnose 0 "keine_Anzeige" 1 "nicht_belegt" 2 "Anzeige_aberkannte_Batterie" 3 "Anzeige_schwache_Batterie" 4 "Anzeige_Batterie_OK" 5 "Anzeige_Batterie_Laden" 6 "Anzeige_Batterie_Pruefen" 7 "Fehler" ;
VAL_ 1635 MIB_Stromsparmodus 0 "inaktiv" 1 "aktiv" ;
VAL_ 1635 BEM_REK_aktiv 0 "keine_Rekuperationsfreigabe" 1 "Rekuperationsfreigabe" ;
VAL_ 1635 NVEM_Last_Anf 0 "keine Anforderung" 1 "Verbraucher_Anforderung_Stufe_1" 2 "Verbraucher_Anforderung_Stufe_2" 3 "Verbraucher_Anforderung_Stufe_3" ;
VAL_ 1635 BEM_UBDM 0 "Init" 255 "Fehler" ;
VAL_ 1635 BEM_Anf_KL15_schalten 0 "Keine_Einschraenkung_Kl15" 1 "Empfehlung_auto_Abschaltung_Kl15" 2 "Veto_auto_Abschaltung_Kl15" 3 "Veto_auto_Abschaltung_Fahrtbetrieb" ;
VAL_ 1635 NVEM_Batterie_Service 0 "kein_Service" 1 "Service_Information1" 2 "Service_Information2" 3 "Service_Information3" ;
VAL_ 1635 NVEM_Freigabe_OnlineUpdate 0 "keine_Freigabe" 1 "Freigabe" ;
VAL_ 1635 NVEM_Freigabe_ORU4 0 "Init" 1 "keine_Freigabe" 2 "Freigabe_erteilt" 3 "Veto_Freigabe" ;
VAL_ 2527679508 NVEM_Max_Rampenzeit 0 "No_LRC" 1 "250ms" 2 "500ms" 3 "750ms" 4 "1s" 5 "2s" 6 "3s" 7 "4s" 8 "5s" 9 "6s" 10 "7s" 11 "8s" 12 "9s" 13 "10s" 14 "12s" 15 "15s" ;
VAL_ 2527679508 NVEM_Min_Spannung 126 "Init" 127 "Fehler" ;
VAL_ 2527679508 NVEM_Min_Spannung_Start 62 "Init" 63 "Fehler" ;
VAL_ 2527679508 NVEM_Max_Spannung 126 "Init" 127 "Fehler" ;
VAL_ 2527679508 NVEM_Energie_Klima_Vorgabe 254 "Init" 255 "Fehler" ;
VAL_ 2527679508 NVEM_MV_DC_uMinLV 126 "Init" 127 "Fehler" ;
VAL_ 2527679508 NVEM_MV_DC_uSollLV 126 "Init" 127 "Fehler" ;
VAL_ 2527679508 NVEM_Bordnetzdiagnose 0 "kein_Fehler" 1 "Warnung_1" 2 "Warnung_2" 3 "Warnung_3" ;
VAL_ 913 MO_Servicemodus 0 "nicht_aktiv" 1 "Service_Mode_1" 2 "Service_Mode_2" 3 "Service_Mode_3" 4 "Service_Mode_4" 5 "Service_Mode_5" 6 "Service_Mode_6" 7 "Service_Mode_7" 8 "Service_Mode_8" 9 "Service_Mode_9" 10 "Service_Mode_10" 11 "Service_Mode_11" 12 "Service_Mode_12" 13 "Service_Mode_13" 14 "Service_Mode_14" 15 "Service_Mode_15" ;
VAL_ 913 OBD_ClearMem_Inhibit 0 "FSP_Loeschen_zulaessig" 1 "FSP_Loeschen_nicht_zulaessig" ;
VAL_ 913 OBD_Sperrung_Kaltstart_Denom 0 "EVAP_Berechnung_freigegeben" 1 "EVAP_Berechnung_gesperrt" ;
VAL_ 913 MO_QBit_Aussen_Temp 0 "gueltiger_Wert" 1 "Ersatz_Init_oder_Fehlerwert" ;
VAL_ 913 OBD_Sperrung_IUMPR 0 "IUMPR_Berechnung_freigegeben" 1 "IUMPR_Berechnung_gesperrt" ;
VAL_ 913 OBD_Kaltstart_Denominator 0 "Denominator_nicht_hochzaehlen" 1 "Bedingungen_zum_Inkr_des_Kaltstart_Denom_erf" ;
VAL_ 913 OBD_Minimum_Trip 0 "kein_Min_Normed_Trip" 1 "Min_Normed_Trip" ;
VAL_ 913 OBD_Driving_Cycle 0 "kein_Driving_Cycle_erkannt" 1 "Driving_Cycle_erkannt" ;
VAL_ 913 OBD_Warm_Up_Cycle 0 "kein_Warm_Up_Cycle_erkannt" 1 "Warm_Up_Cycle_erkannt" ;
VAL_ 913 OBD_Normed_Trip 0 "kein_Normed_Trip" 1 "Normed_Trip" ;
VAL_ 2589283656 ORU_Warnung 0 "keine_Anzeige" 1 "Update_unvollstaendig_Prio1" 2 "Update_fehlgeschlagen_Prio1" 3 "reserviert" ;
VAL_ 2589283656 ORU_Status 0 "IDLE" 1 "PENDING" 2 "PREPARATION" 3 "PREPARATION_HV" 4 "RUNNING" 5 "RUNNING_HV" 6 "PENDING_NOTREADY" 7 "FAILURE_POWERTRAIN_DISABLED" ;
VAL_ 2527679670 OTA_FC_Hinweis_Update 0 "inaktiv" 1 "aktiv" ;
VAL_ 2527679670 OTA_FC_PredMaint_Ausfall 0 "inaktiv" 1 "aktiv" ;
VAL_ 2527679670 OTA_FC_Warnung_Update 0 "inaktiv" 1 "aktiv" ;
VAL_ 2527679670 OTA_FC_IOF_Ausfall 0 "inaktiv" 1 "aktiv" ;
VAL_ 2527679670 OTA_FC_FoD_Stornierung 0 "inaktiv" 1 "aktiv" ;
VAL_ 2527679670 OTA_FC_FahrwerkAnf 0 "KeineOTAFCAnf_Fahrwerk" 1 "OTAFCAnf_FahrwerkNormal" 2 "OTAFCAnf_FahrwerkSport" 3 "OTAFCAnf_FahrwerkSportPlus" ;
VAL_ 2527679670 OTA_FC_LiftAnf 0 "KeineOTAFCAnf_Lift" 1 "OTAFCAnf_Lift" ;
VAL_ 2527679670 OTA_FC_NiveauAnf 0 "KeineOTAFCAnf_Niveau" 1 "OTAFCAnf_NiveauSGN" 2 "OTAFCAnf_NiveauGN" 3 "OTAFCAnf_NiveauNN" 4 "OTAFCAnf_NiveauTN" 5 "OTAFCAnf_NiveauBN" ;
VAL_ 2527679670 ORU_EM_Anfrage_freigegebeneNetze 0 "only_12V" 1 "networks_48V_and_12V" 2 "networks_HV_and_12V" 3 "networks_HV_and_48V_and_12V" ;
VAL_ 2527679670 ORU_Status_Anf 0 "IDLE" 1 "PENDING" 2 "PREPARATION" 3 "PREPARATION_HV" 4 "RUNNING" 5 "RUNNING_HV" 6 "PENDING_NOTREADY" ;
VAL_ 970 PACC02_InnoDrive_Texte 0 "Init" 1 "Strasse_nicht_moeglich" 2 "Strasse_nicht_erfasst" 3 "zul_Geschw_zu_gering" 4 "Land_nicht_moeglich" 5 "Anhaengerbetrieb" 6 "temporaer_nicht_moeglich" 7 "Vorfahrtsregeln_wieder_verfuegba" 8 "Ortung" 9 "Vorfahrtsregeln_nicht_verfuegbar" 10 "Strassenverlauf_nicht_verfuegbar" 11 "Tempolimits_nicht_verfuegbar" ;
VAL_ 970 PACC02_Systemstatus_Anzeige 0 "OFF" 1 "INIT" 2 "STANDBY" 3 "AKTIV_regelt" 4 "PASSIV" 5 "NICHT_VERFUEGBAR" 6 "FEHLER_System" 7 "FEHLER_Irreversibel" ;
VAL_ 970 PACC02_Automode 0 "Automode_inaktiv" 1 "Automode_aktiv" ;
VAL_ 970 PACC02_Segelanteil 0 "Init" ;
VAL_ 970 PACC02_Durchschnittsgeschw 0 "Init" ;
VAL_ 970 PACC02_Uebernahmeaufforderung 0 "keine_Uebernahmeaufforderung" 1 "Uebernahmeaufforderung" ;
VAL_ 970 PACC02_Systemstatus 0 "OFF" 1 "INIT" 2 "STANDBY" 3 "AKTIV_regelt" 4 "PASSIV" 5 "FEHLER_Karte" 6 "FEHLER_System" 7 "FEHLER_Irreversibel" ;
VAL_ 970 PACC02_Vorausschaugeschw 1023 "Init" ;
VAL_ 970 PACC02_Sollgeschwindigkeit 1023 "Init" ;
VAL_ 970 PACC02_naechstes_Event 0 "Init" 1 "Tempolimit_5kmh" 2 "Tempolimit_10kmh" 3 "Tempolimit_15kmh" 4 "Tempolimit_20kmh" 5 "Tempolimit_25kmh" 6 "Tempolimit_30kmh" 7 "Tempolimit_35kmh" 8 "Tempolimit_40kmh" 9 "Tempolimit_45kmh" 10 "Tempolimit_50kmh" 11 "Tempolimit_55kmh" 12 "Tempolimit_60kmh" 13 "Tempolimit_65kmh" 14 "Tempolimit_70kmh" 15 "Tempolimit_75kmh" 16 "Tempolimit_80kmh" 17 "Tempolimit_90kmh" 18 "Tempolimit_100kmh" 19 "Tempolimit_110kmh" 20 "Tempolimit_120kmh" 21 "Tempolimit_130kmh" 22 "Tempolimit_140kmh" 23 "Tempolimit_150kmh" 24 "Tempolimit_160kmh" 25 "Tempolimit_unbegrenzt" 26 "Linkskurve" 27 "Rechtskurve" 28 "Kuppe" 29 "Steigung" 30 "Gefaelle" 31 "Kreuzung" 32 "Ampel" 33 "Bahnuebergang" 34 "Ortsanfang" 35 "Kreisverkehr" 36 "Abzweigung_links" 37 "Abzweigung_rechts" 38 "Abfahrt_links" 39 "Abfahrt_rechts" 40 "Stoppstelle" 41 "Vorfahrt_beachten" 42 "PVS_Limit" ;
VAL_ 2463978731 PACC02_Geschw_Vorausschau 0 "Setzgeschwindigkeit_aktuell" 1 "Setzgeschwindigkeit_Vorausschau" ;
VAL_ 2463978731 PACC02_Event_aktiv 0 "Vorausschauevent_inaktiv" 1 "Vorausschauevent_aktiv" ;
VAL_ 2463978731 PACC02_Hinweis_Geschw 0 "Tempolimit_Assi_nicht_verfuegbar" 1 "Tempolimit_Assi_verfuegbar" ;
VAL_ 2463978731 PACC02_Offset_aktiv 0 "Regelung_StrVer_nicht_verfuegbar" 1 "Regelung_StrVer_verfuegbar" ;
VAL_ 2463978731 PACC02_Offset_Anzeige 0 "Auslief_Zust_kein_PID_vorhanden" 1 "Auslief_Zust_Temp_Assi_vorhanden" 2 "Auslief_Zust_StrV_Rege_vorhanden" 3 "Auslief_Zust_Temp_StrV_vorhanden" 4 "Dev_Temp_StrV_vorh_aktiv_u_verfu" ;
VAL_ 908 PACC_Sytemstatus_Anzeige 0 "OFF" 1 "INIT" 2 "STANDBY" 3 "AKTIV_regelt" 4 "PASSIV" 5 "FEHLER_Karte" 6 "FEHLER_System" 7 "FEHLER_irreversibel" ;
VAL_ 908 PACC_Automode 0 "Automode_inaktiv" 1 "Automode_aktiv" ;
VAL_ 908 PACC_Segelanteil 0 "Init" ;
VAL_ 908 PACC_Durchschnittsgeschw 0 "Init" ;
VAL_ 908 PACC_Uebernahmeaufforderung 0 "keine_Uebernahmeaufforderung" 1 "Uebernahmeaufforderung" ;
VAL_ 908 PACC_Systemstatus 0 "OFF" 1 "INIT" 2 "STANDBY" 3 "AKTIV_regelt" 4 "PASSIV" 5 "FEHLER_Karte" 6 "FEHLER_System" 7 "FEHLER_Irreversibel" ;
VAL_ 908 PACC_Vorausschaugeschw 1023 "Init" ;
VAL_ 908 PACC_naechstes_Event 0 "Init" 1 "Tempolimit_5kmh" 2 "Tempolimit_10kmh" 3 "Tempolimit_15kmh" 4 "Tempolimit_20kmh" 5 "Tempolimit_25kmh" 6 "Tempolimit_30kmh" 7 "Tempolimit_35kmh" 8 "Tempolimit_40kmh" 9 "Tempolimit_45kmh" 10 "Tempolimit_50kmh" 11 "Tempolimit_55kmh" 12 "Tempolimit_60kmh" 13 "Tempolimit_65kmh" 14 "Tempolimit_70kmh" 15 "Tempolimit_75kmh" 16 "Tempolimit_80kmh" 17 "Tempolimit_90kmh" 18 "Tempolimit_100kmh" 19 "Tempolimit_110kmh" 20 "Tempolimit_120kmh" 21 "Tempolimit_130kmh" 22 "Tempolimit_140kmh" 23 "Tempolimit_150kmh" 24 "Tempolimit_160kmh" 25 "Tempolimit_unbegrenzt" 26 "Linkskurve" 27 "Rechtskurve" 28 "Kuppe" 29 "Steigung" 30 "Gefaelle" 31 "Kreuzung" 32 "Ampel" 33 "Bahnuebergang" 34 "Ortsanfang" 35 "Kreisverkehr" ;
VAL_ 696 PADM_Warnmeldung_Prio2 0 "keine_Anzeige" 1 "Fehlermeldung" ;
VAL_ 872 PH2_Visualisierung 0 "Aus" 1 "Angefragt" 2 "InAnzeige" 3 "Abgefordert" 6 "Init" 7 "Fehler" ;
VAL_ 872 PDC2_Tonausgabe_Front 0 "kein_Ton" 1 "Intervallton_1" 2 "Intervallton_2" 3 "Intervallton_3" 4 "Intervallton_4" 5 "Intervallton_5" 6 "Dauerton" 7 "Fehlerton" 8 "FCTAton" ;
VAL_ 872 PDC2_Tonausgabe_Heck 0 "kein_Ton" 1 "Intervallton_1" 2 "Intervallton_2" 3 "Intervallton_3" 4 "Intervallton_4" 5 "Intervallton_5" 6 "Dauerton" 7 "Fehlerton" 8 "Erstwarnton_hinten" 9 "RCTATon" ;
VAL_ 872 PH2_nachtr_Stopp_An 0 "nicht_angefordert" 1 "angefordert" ;
VAL_ 872 PH2_Abschaltursache 0 "keine, bzw. System aktiv" 1 "Abschaltung durch Herausnahme R-Gang" 2 "Abschaltung ueber Geschwindigkeit" 3 "Abschaltung ueber PDC-Taster" 4 "Abschaltung wegen PLA" 5 "Abschaltung durch KL 15 Bit = 0" 6 "tbd." 7 "Fehler-/gestört Zustand, System noch aktiv" ;
VAL_ 872 PH2_Opt_Anzeige_V_ein 0 "optische Anzeige vorne nicht aktiv" 1 "optische Anzeige vorne aktiviert" ;
VAL_ 872 PH2_Opt_Anzeige_H_ein 0 "Optische Anzeige aus" 1 "optische Anzeige hinten aktiviert" ;
VAL_ 872 PH2_Opt_Anz_V_Hindernis 0 "optische Anzeige vorne meldet kein Hindernis" 1 "optische Anzeige vorne meldet Hindernis im Warnbereich" ;
VAL_ 872 PH2_Opt_Anz_H_Hindernis 0 "optische Anzeige hinten meldet kein Hindernis" 1 "optische Anzeige hinten meldet Hindernis im Warnbereich" ;
VAL_ 872 PH2_Tongeber_V_aktiv 0 "Tongeber vorne nicht aktiv" 1 "Tongeber vorne  aktiv" ;
VAL_ 872 PH2_Tongeber_H_aktiv 0 "Tongeber hinten nicht aktiv" 1 "Tongeber hinten aktiv" ;
VAL_ 872 PH2_Tongeber_mute 0 "Tongeber nicht stummgeschaltet" 1 "Tongeber stummgeschaltet" ;
VAL_ 872 PH2_Anf_Audioabsenkung 0 "keine Absenkung der Lautstärke" 1 "Anforderung an das Audiosystem für Absenkung der Lautstärke" ;
VAL_ 872 PH2_Tongeber_H_verfuegbar 0 "nicht verfügbar" 1 "verfügbar" ;
VAL_ 872 PH2_Taster 0 "Taster_nicht_gedrueckt" 1 "Taster_gedrueckt" 2 "reserviert" 3 "Fehler" ;
VAL_ 872 PH2_Anf_Verdeck 0 "Verdeckbetrieb_freigegeben" 1 "Verdeckbetrieb_sperren" 2 "reserviert" 3 "reserviert" ;
VAL_ 872 PH2_StartStopp_Info 0 "Motorlauf_nicht_notwendig_(Stoppfreigabe)" 1 "Motoranlauf_nicht_zwingend_notwendig_(Stoppverbot,keine_Startanforderung)" 2 "Motoranlauf_zwingend_notwendig_(Startanforderung)" 3 "Systemfehler" ;
VAL_ 872 PH2_Stoermeldung 0 "keine_Anzeige_kein_Gong" 1 "Textmeldung_PDC_hinten_gestoert_mit_Gong" 2 "Textmeldung_PDC_hinten_gestoert_ohne_Gong" 3 "Textmeldung_PDC_vorn_gestoert_mit_Gong" 4 "Textmeldung_PDC_vorn_gestoert_ohne_Gong" 5 "Textmeldung_PDC_gestoert_mit_Gong" 6 "Textmeldung_PDC_gestoert_ohne_Gong" 7 "Textmeldung_PDC_seitlich_gestoert_mit_Gong" 8 "Textmeldung_PDC_seitlich_gestoert_ohne_Gong" ;
VAL_ 872 PH2_defekt 0 "PH aktiv" 1 "PH wurde aufgrund eines Defektes deaktiviert" ;
VAL_ 872 PH2_gestoert 0 "PH aktiv" 1 "PH wurde auf Grund einer Stoerung tempraer deaktiviert" ;
VAL_ 872 PH2_Systemzustand 0 "Anlage aus" 1 "Anlage durch einlegen R-Gang aktiviert" 2 "Anlage manuell durch Taster aktiviert" 3 "Anlage automatisch aktiviert" 4 "Anlage_durch_ARA_aktiviert" 6 "Init_Initialisierungsphase_nach_Kl15_ein_oder_Reset" 7 "Fehler-/gestört Zustand, System noch aktiv" ;
VAL_ 872 PH2_Display_Kundenwunsch 0 "Anzeige aus" 1 "Grafik" 2 "Rear View" 3 "automatisch" ;
VAL_ 2463978617 PH2_Verschmutzungsmeldung 0 "keine_Anzeige_kein_Gong" 1 "Textmeldung_PDC_hinten_verschmutzt_mit_Gong" 2 "Textmeldung_PDC_hinten_verschmutzt_ohne_Gong" 3 "Textmeldung_PDC_vorn_verschmutzt_mit_Gong" 4 "Textmeldung_PDC_vorn_verschmutzt_ohne_Gong" 5 "Textmeldung_PDC_verschmutzt_mit_Gong" 6 "Textmeldung_PDC_verschmutzt_ohne_Gong" 7 "Textmeldung_PDC_seitlich_verschmutzt_mit_Gong" 8 "Textmeldung_PDC_seitlich_verschmutzt_ohne_Gong" ;
VAL_ 2463978617 PH2_Aufschaltursache 0 "Anlage aus" 1 "Anlage durch einlegen R-Gang aktiviert" 2 "Anlage manuell durch Taster aktiviert" 3 "Anlage automatisch aktiviert" 4 "Anlage durch ARA aktiviert" 5 "Rueckwaertsrollen" 6 "Anlage_durch_PLA_aktiviert" 7 "Anlage_durch_IPA_aktiviert" 8 "Anlage_durch_FA_aktiviert" 9 "Anlage_durch_RBF_oder_MA_aktiviert" 10 "Anlage_durch_Smartphone_aktiviert" 11 "Anlage_durch_Jokertaste_aktiviert" 12 "Anlage_durch_Favoritentasten_aktiviert" 13 "Anlage_durch_SideViewTaster_aktiviert" 14 "Anlage_durch_RCTA_aktiviert" 15 "Anlage_durch_KAS_aktiviert" 16 "Anlage_durch_AWC_aktiviert" 30 "Init_Initialisierungsphase_nach_Kl_15_ein_oder_Reset" 31 "Fehler_gestoerter_Zustand_System_noch_aktiv" ;
VAL_ 2463978617 PH2_WAH_Meldung 0 "Init" 1 "Fehlermeldung_bei_Nichtverfuegbarkeit_mit_Gong" 2 "Fehlermeldung_bei_Nichtverfuegbarkeit_ohne_Gong" 3 "Anzeige_dass_Fahrzeug_erkannt_wurde_und_Funktion_aktiv_ist" 4 "Wiederanfahrhinweis_mit_Gong" 5 "Wiederanfahrhinweis_ohne_Gong" ;
VAL_ 1175 PH_Visualisierung 0 "Aus" 1 "Angefragt" 2 "InAnzeige" 3 "Abgefordert" 6 "Init" 7 "Fehler" ;
VAL_ 1175 PDC_Tonausgabe_Front 0 "kein_Ton" 1 "Intervallton_1" 2 "Intervallton_2" 3 "Intervallton_3" 4 "Intervallton_4" 5 "Intervallton_5" 6 "Dauerton" 7 "Fehlerton" 8 "RCTATon" ;
VAL_ 1175 PDC_Tonausgabe_Heck 0 "kein_Ton" 1 "Intervallton_1" 2 "Intervallton_2" 3 "Intervallton_3" 4 "Intervallton_4" 5 "Intervallton_5" 6 "Dauerton" 7 "Fehlerton" 8 "Erstwarnton_hinten" 9 "RCTATon" ;
VAL_ 1175 PH_nachtr_Stopp_Anf 0 "nicht_angefordert" 1 "angefordert" ;
VAL_ 1175 PH_Abschaltursache 0 "keine, bzw. System aktiv" 1 "Abschaltung durch Herausnahme R-Gang" 2 "Abschaltung ueber Geschwindigkeit" 3 "Abschaltung ueber PDC-Taster" 4 "Abschaltung wegen PLA" 5 "Abschaltung durch KL 15 Bit = 0" 6 "tbd." 7 "Fehler-/gestört Zustand, System noch aktiv" ;
VAL_ 1175 PH_Opt_Anzeige_V_ein 0 "optische Anzeige vorne nicht aktiv" 1 "optische Anzeige vorne aktiviert" ;
VAL_ 1175 PH_Opt_Anzeige_H_ein 0 "Optische Anzeige aus" 1 "optische Anzeige hinten aktiviert" ;
VAL_ 1175 PH_Opt_Anz_V_Hindernis 0 "optische Anzeige vorne meldet kein Hindernis" 1 "optische Anzeige vorne meldet Hindernis im Warnbereich" ;
VAL_ 1175 PH_Opt_Anz_H_Hindernis 0 "optische Anzeige hinten meldet kein Hindernis" 1 "optische Anzeige hinten meldet Hindernis im Warnbereich" ;
VAL_ 1175 PH_Tongeber_V_aktiv 0 "Tongeber vorne nicht aktiv" 1 "Tongeber vorne  aktiv" ;
VAL_ 1175 PH_Tongeber_H_aktiv 0 "Tongeber hinten nicht aktiv" 1 "Tongeber hinten aktiv" ;
VAL_ 1175 PH_Tongeber_mute 0 "Tongeber nicht stummgeschaltet" 1 "Tongeber stummgeschaltet" ;
VAL_ 1175 PH_Anf_Audioabsenkung 0 "Keine_Audioabsenkung" 1 "Anforderung_Audioabsenkung" ;
VAL_ 1175 PH_Tongeber_H_verfuegbar 0 "nicht verfügbar" 1 "verfügbar" ;
VAL_ 1175 PLA_Anf_Aufschaltung_RVC 0 "Keine_RVC_Aufschalteanf" 1 "RVC_Aufschalteanforderung" ;
VAL_ 1175 PH_Taster 0 "Taster_nicht_gedrueckt" 1 "Taster_gedrueckt" 2 "reserviert" 3 "Fehler" ;
VAL_ 1175 PH_Anf_Verdeck 0 "Verdeckbetrieb_freigegeben" 1 "Verdeckbetrieb_sperren" 2 "reserviert" 3 "reserviert" ;
VAL_ 1175 PH_StartStopp_Info 0 "Motorlauf_nicht_notwendig_(Stoppfreigabe)" 1 "Motoranlauf_nicht_zwingend_notwendig_(Stoppverbot,keine_Startanforderung)" 2 "Motoranlauf_zwingend_notwendig_(Startanforderung)" 3 "Systemfehler" ;
VAL_ 1175 PH_Stoermeldung 0 "keine_Anzeige_kein_Gong" 1 "Textmeldung_PDC_hinten_gestoert_mit_Gong" 2 "Textmeldung_PDC_hinten_gestoert_ohne_Gong" 3 "Textmeldung_PDC_vorn_gestoert_mit_Gong" 4 "Textmeldung_PDC_vorn_gestoert_ohne_Gong" 5 "Textmeldung_PDC_gestoert_mit_Gong" 6 "Textmeldung_PDC_gestoert_ohne_Gong" 7 "Textmeldung_PDC_seitlich_gestoert_mit_Gong" 8 "Textmeldung_PDC_seitlich_gestoert_ohne_Gong" ;
VAL_ 1175 PH_defekt 0 "PH aktiv" 1 "PH wurde aufgrund eines Defektes deaktiviert" ;
VAL_ 1175 PH_gestoert 0 "PH aktiv" 1 "PH wurde auf Grund einer Stoerung tempraer deaktiviert" ;
VAL_ 1175 PH_Systemzustand 0 "Anlage aus" 1 "Anlage durch einlegen R-Gang aktiviert" 2 "Anlage manuell durch Taster aktiviert" 3 "Anlage automatisch aktiviert" 4 "Anlage durch ARA aktiviert" 6 "Init - Initialisierungsphase nach Kl. 15 ein / Reset" 7 "Fehler-/gestört Zustand, System noch aktiv" ;
VAL_ 1175 PH_Display_Kundenwunsch 0 "Anzeige aus" 1 "Grafik" 2 "Rear View" 3 "automatisch" ;
